VERSION "hnnbnnnynnnnnnnnnnnnnnnnnnnnnnnnnnnnnnnnnn/4/%%%/4/'%**4nnn///"

NS_ :

BS_:

BU_: BAP_Tester Fahrerdisplay_Kombi HUD ICAS1_X_Gateway ICAS3_Gateway ICC_IO_Node Kombi SmartLight_01 ZR_MIB_TOP_ab_Gen3

BO_ 1175 Parkhilfe_01: 8 ICAS1_X_Gateway
	SG_ PDC_Tonausgabe_Front : 4|4@1+ (1,0) [0|15] ""  Vector__XXX
	SG_ PDC_Tonausgabe_Heck : 8|4@1+ (1,0) [0|15] ""  Vector__XXX
	SG_ PH_Abschaltursache : 13|3@1+ (1,0) [0|7] ""  Vector__XXX
	SG_ PH_Anf_Audioabsenkung : 23|1@1+ (1,0) [0|1] ""  ICAS3_Gateway,ZR_MIB_TOP_ab_Gen3
	SG_ PH_Anf_Verdeck : 30|2@1+ (1,0) [0|3] ""  Vector__XXX
	SG_ PH_defekt : 56|1@1+ (1,0) [0|1] ""  Vector__XXX
	SG_ PH_Display_Kundenwunsch : 61|2@1+ (1,0) [0|3] ""  Vector__XXX
	SG_ PH_Frequenz_hinten : 32|4@1+ (1,0) [0|15] ""  Vector__XXX
	SG_ PH_Frequenz_vorn : 40|4@1+ (1,0) [0|15] ""  Vector__XXX
	SG_ PH_gestoert : 57|1@1+ (1,0) [0|1] ""  Vector__XXX
	SG_ PH_Lautstaerke_hinten : 36|4@1+ (1,0) [0|15] ""  Vector__XXX
	SG_ PH_Lautstaerke_vorn : 44|4@1+ (1,0) [0|15] ""  Vector__XXX
	SG_ PH_nachtr_Stopp_Anf : 12|1@1+ (1,0) [0|1] ""  Vector__XXX
	SG_ PH_Opt_Anz_H_Hindernis : 19|1@1+ (1,0) [0|1] ""  Vector__XXX
	SG_ PH_Opt_Anz_V_Hindernis : 18|1@1+ (1,0) [0|1] ""  Vector__XXX
	SG_ PH_Opt_Anzeige_H_ein : 17|1@1+ (1,0) [0|1] ""  Vector__XXX
	SG_ PH_Opt_Anzeige_V_ein : 16|1@1+ (1,0) [0|1] ""  Vector__XXX
	SG_ PH_StartStopp_Info : 49|2@1+ (1,0) [0|3] ""  Vector__XXX
	SG_ PH_Stoermeldung : 52|4@1+ (1,0) [0|15] ""  Kombi
	SG_ PH_Systemzustand : 58|3@1+ (1,0) [0|7] ""  Vector__XXX
	SG_ PH_Taster : 28|2@1+ (1,0) [0|3] ""  Vector__XXX
	SG_ PH_Tongeber_H_aktiv : 21|1@1+ (1,0) [0|1] ""  Vector__XXX
	SG_ PH_Tongeber_H_verfuegbar : 24|1@1+ (1,0) [0|1] ""  Vector__XXX
	SG_ PH_Tongeber_mute : 22|1@1+ (1,0) [0|1] ""  Vector__XXX
	SG_ PH_Tongeber_V_aktiv : 20|1@1+ (1,0) [0|1] ""  Vector__XXX
	SG_ PH_Visualisierung : 0|3@1+ (1,0) [0|7] ""  ICAS3_Gateway
	SG_ PLA_Anf_Aufschaltung_RVC : 25|1@1+ (1,0) [0|1] ""  Vector__XXX

BO_ 1355 Parkhilfe_04: 8 ICAS1_X_Gateway
	SG_ APS_PaCo_WarningTones : 48|1@1+ (1,0) [0|1] ""  Vector__XXX
	SG_ APSOPS_PaCo_ApproachingFront : 47|1@1+ (1,0) [0|1] ""  Vector__XXX
	SG_ APSOPS_PaCo_ApproachingRear : 46|1@1+ (1,0) [0|1] ""  Vector__XXX
	SG_ APSOPS_PaCo_Button : 38|2@1+ (1,0) [0|3] ""  Vector__XXX
	SG_ APSOPS_PaCo_FunctionState : 43|3@1+ (1,0) [0|7] ""  Vector__XXX
	SG_ APSOPS_PaCo_MainState : 40|3@1+ (1,0) [0|7] ""  Vector__XXX
	SG_ APSOPS_PaCo_ObstacleDetectFront : 35|3@1+ (1,0) [0|7] ""  Vector__XXX
	SG_ APSOPS_PaCo_ObstacleDetectRear : 32|3@1+ (1,0) [0|7] ""  Vector__XXX
	SG_ PH_Aufschaltursache : 16|5@1+ (1,0) [0|31] ""  Vector__XXX
	SG_ PH_Ton_Ausgabe : 21|3@1+ (1,0) [0|7] ""  ICAS3_Gateway,ZR_MIB_TOP_ab_Gen3
	SG_ PH_Ton_Lautstaerke : 52|3@1+ (1,0) [0|7] ""  ICAS3_Gateway,ZR_MIB_TOP_ab_Gen3
	SG_ PH_Ton_Pausenlaenge : 24|8@1+ (1,0) [0|255] ""  ICAS3_Gateway,ZR_MIB_TOP_ab_Gen3
	SG_ PH_Ton_Richtung : 49|3@1+ (1,0) [0|7] ""  ICAS3_Gateway,ZR_MIB_TOP_ab_Gen3
	SG_ PH_Verschmutzungsmeldung : 12|4@1+ (1,0) [0|15] ""  Kombi
	SG_ PH_WAH_Meldung : 55|3@1+ (1,0) [0|7] ""  Kombi
	SG_ RBF_Anf_Meldungen : 9|3@1+ (1,0) [0|7] ""  Kombi
	SG_ RBF_PaCo_Anf_Meldungen : 58|3@1+ (1,0) [0|7] ""  Vector__XXX
	SG_ RBFMA_PaCo_BrakeIntervention : 0|3@1+ (1,0) [0|7] ""  Vector__XXX
	SG_ RBFMA_PaCo_MainState : 3|3@1+ (1,0) [0|7] ""  Vector__XXX

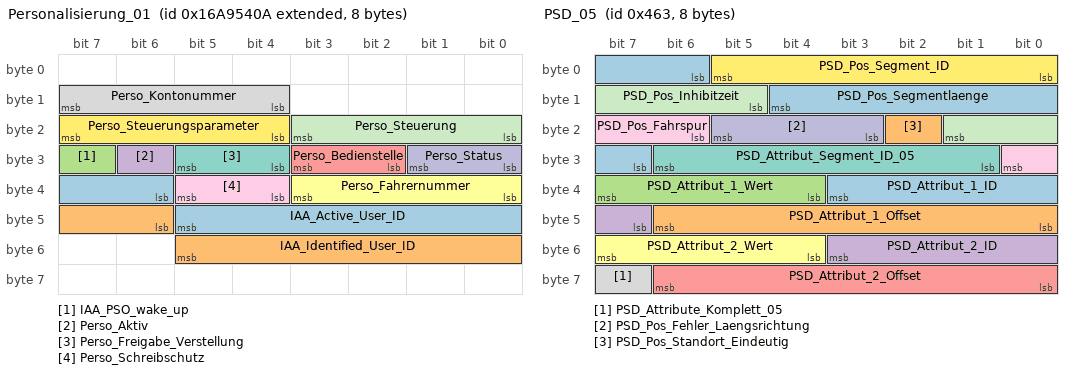
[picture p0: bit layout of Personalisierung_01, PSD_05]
BO_ 2527679498 Personalisierung_01: 8 ICAS1_X_Gateway
	SG_ IAA_Active_User_ID : 38|8@1+ (1,0) [0|255] "None"  ICAS3_Gateway,ZR_MIB_TOP_ab_Gen3
	SG_ IAA_Identified_User_ID : 46|8@1+ (1,0) [0|255] "None"  ICAS3_Gateway,ZR_MIB_TOP_ab_Gen3
	SG_ IAA_PSO_wake_up : 31|1@1+ (1,0) [0|1] ""  ICAS3_Gateway,ZR_MIB_TOP_ab_Gen3
	SG_ Perso_Aktiv : 30|1@1+ (1,0) [0|1] ""  ICAS3_Gateway
	SG_ Perso_Bedienstelle : 26|2@1+ (1,0) [0|3] ""  ICAS3_Gateway
	SG_ Perso_Fahrernummer : 32|4@1+ (1,0) [0|15] ""  ICAS3_Gateway,ZR_MIB_TOP_ab_Gen3
	SG_ Perso_Freigabe_Verstellung : 28|2@1+ (1,0) [0|3] ""  ICAS3_Gateway,ZR_MIB_TOP_ab_Gen3
	SG_ Perso_Kontonummer : 12|4@1+ (1,0) [0|15] ""  ICAS3_Gateway,Kombi,ZR_MIB_TOP_ab_Gen3
	SG_ Perso_Schreibschutz : 36|2@1+ (1,0) [0|3] ""  ICAS3_Gateway
	SG_ Perso_Status : 24|2@1+ (1,0) [0|3] ""  ICAS3_Gateway,Kombi,ZR_MIB_TOP_ab_Gen3
	SG_ Perso_Steuerung : 16|4@1+ (1,0) [0|15] ""  ICAS3_Gateway,Kombi,ZR_MIB_TOP_ab_Gen3
	SG_ Perso_Steuerungsparameter : 20|4@1+ (1,0) [0|15] ""  ICAS3_Gateway,Kombi,ZR_MIB_TOP_ab_Gen3

BO_ 319 PreCrash_02: 8 ICAS1_X_Gateway
	SG_ PreCrash_Anforderung_AFR : 26|3@1+ (1,0) [0|7] ""  Vector__XXX
	SG_ PreCrash_BFS_KSV_verfahren : 47|4@1+ (1,0) [0|15] ""  Vector__XXX
	SG_ PreCrash_BFS_Laengsverstellung : 55|1@1+ (1,0) [0|1] ""  Vector__XXX
	SG_ PreCrash_BFS_Pneumatik_ansteuern : 32|1@1+ (1,0) [0|1] ""  Vector__XXX
	SG_ PreCrash_BFS_Sitzlehne_verfahren : 37|3@1+ (1,0) [0|7] ""  Vector__XXX
	SG_ PreCrash_Blinken : 20|3@1+ (1,0) [0|7] ""  Vector__XXX
	SG_ PreCrash_Charisma_FahrPr : 12|4@1+ (1,0) [0|15] ""  Vector__XXX
	SG_ PreCrash_Charisma_Status : 16|2@1+ (1,0) [0|3] ""  Vector__XXX
	SG_ PreCrash_Fenster_schliessen : 19|1@1+ (1,0) [0|1] ""  Vector__XXX
	SG_ PreCrash_Fo_KSV_verfahren : 51|4@1+ (1,0) [0|15] ""  Vector__XXX
	SG_ PreCrash_Fo_Pneumatik_ansteuern : 33|1@1+ (1,0) [0|1] ""  Vector__XXX
	SG_ PreCrash_Fo_Sitzlehne_verfahren : 40|3@1+ (1,0) [0|7] ""  Vector__XXX
	SG_ PreCrash_FS_KSV_verfahren : 43|4@1+ (1,0) [0|15] ""  Vector__XXX
	SG_ PreCrash_FS_Laengsverstellung : 25|1@1+ (1,0) [0|1] ""  Vector__XXX
	SG_ PreCrash_FS_Pneumatik_ansteuern : 31|1@1+ (1,0) [0|1] ""  Vector__XXX
	SG_ PreCrash_FS_Sitzlehne_verfahren : 34|3@1+ (1,0) [0|7] ""  Vector__XXX
	SG_ PreCrash_Schiebedach_schliessen : 18|1@1+ (1,0) [0|1] ""  Vector__XXX
	SG_ PreCrash_Tueren_Verriegeln : 24|1@1+ (1,0) [0|1] ""  Vector__XXX
	SG_ SC_PreCrash_LED : 29|2@1+ (1,0) [0|3] ""  Vector__XXX
	SG_ SC_PreCrash_Texte : 60|4@1+ (1,0) [0|15] ""  Kombi
	SG_ SC_PreCrash_Warnung : 56|4@1+ (1,0) [0|15] ""  Kombi,ZR_MIB_TOP_ab_Gen3
	SG_ SC_PreSense_FCWP : 23|1@1+ (1,0) [0|1] ""  Vector__XXX

BO_ 1122 PSD_04: 8 ICAS3_Gateway
	SG_ PSD_Abzweigerichtung : 56|1@1+ (1,0) [0|1] ""  ICAS1_X_Gateway
	SG_ PSD_Abzweigewinkel : 57|7@1+ (1.417323,0) [0|180.000021] ""  ICAS1_X_Gateway
	SG_ PSD_ADAS_Qualitaet : 37|1@1+ (1,0) [0|1] ""  ICAS1_X_Gateway
	SG_ PSD_Anfangskruemmung : 47|8@1+ (1,0) [0|254] ""  ICAS1_X_Gateway
	SG_ PSD_Anfangskruemmung_Vorz : 55|1@1+ (1,0) [0|1] ""  ICAS1_X_Gateway
	SG_ PSD_Bebauung : 43|1@1+ (1,0) [0|1] ""  ICAS1_X_Gateway
	SG_ PSD_Endkruemmung : 22|8@1+ (1,0) [0|254] "None"  ICAS1_X_Gateway
	SG_ PSD_Endkruemmung_Vorz : 30|1@1+ (1,0) [0|1] ""  ICAS1_X_Gateway
	SG_ PSD_Fahrspuren_Anzahl : 40|3@1+ (1,0) [0|7] ""  ICAS1_X_Gateway
	SG_ PSD_Geradester_Pfad : 39|1@1+ (1,0) [0|1] ""  ICAS1_X_Gateway
	SG_ PSD_Idenditaets_ID : 31|6@1+ (1,0) [2|63] ""  ICAS1_X_Gateway
	SG_ PSD_Rampe : 45|2@1+ (1,0) [0|3] ""  ICAS1_X_Gateway
	SG_ PSD_Segment_ID : 0|6@1+ (1,0) [2|63] ""  ICAS1_X_Gateway
	SG_ PSD_Segment_Komplett : 44|1@1+ (1,0) [0|1] ""  ICAS1_X_Gateway
	SG_ PSD_Segmentlaenge : 12|7@1+ (2,0) [0|254] "Meter"  ICAS1_X_Gateway
	SG_ PSD_Strassenkategorie : 19|3@1+ (1,0) [0|7] ""  ICAS1_X_Gateway
	SG_ PSD_Vorgaenger_Segment_ID : 6|6@1+ (1,0) [2|63] ""  ICAS1_X_Gateway
	SG_ PSD_wahrscheinlichster_Pfad : 38|1@1+ (1,0) [0|1] ""  ICAS1_X_Gateway

BO_ 1123 PSD_05: 8 ICAS3_Gateway
	SG_ PSD_Attribut_1_ID : 31|5@1+ (1,0) [1|31] ""  ICAS1_X_Gateway
	SG_ PSD_Attribut_1_Offset : 40|7@1+ (2,0) [0|254] "Meter"  ICAS1_X_Gateway
	SG_ PSD_Attribut_1_Wert : 36|4@1+ (1,0) [0|15] ""  ICAS1_X_Gateway
	SG_ PSD_Attribut_2_ID : 47|5@1+ (1,0) [1|31] ""  ICAS1_X_Gateway
	SG_ PSD_Attribut_2_Offset : 56|7@1+ (2,0) [0|254] "Meter"  ICAS1_X_Gateway
	SG_ PSD_Attribut_2_Wert : 52|4@1+ (1,0) [0|15] ""  ICAS1_X_Gateway
	SG_ PSD_Attribut_Segment_ID_05 : 25|6@1+ (1,0) [2|63] ""  ICAS1_X_Gateway
	SG_ PSD_Attribute_Komplett_05 : 63|1@1+ (1,0) [0|1] ""  ICAS1_X_Gateway
	SG_ PSD_Pos_Fahrspur : 22|3@1+ (1,0) [0|7] ""  ICAS1_X_Gateway
	SG_ PSD_Pos_Fehler_Laengsrichtung : 19|3@1+ (1,0) [0|7] ""  ICAS1_X_Gateway
	SG_ PSD_Pos_Inhibitzeit : 13|5@1+ (10,0) [0|310] "MilliSecon"  ICAS1_X_Gateway
	SG_ PSD_Pos_Segment_ID : 0|6@1+ (1,0) [2|63] ""  ICAS1_X_Gateway
	SG_ PSD_Pos_Segmentlaenge : 6|7@1+ (2,0) [0|254] "Meter"  ICAS1_X_Gateway
	SG_ PSD_Pos_Standort_Eindeutig : 18|1@1+ (1,0) [0|1] ""  ICAS1_X_Gateway

BO_ 1124 PSD_06: 8 ICAS3_Gateway
	SG_ PSD_06_Mux M : 0|3@1+ (1,0) [0|7] ""  ICAS1_X_Gateway
	SG_ PSD_Attribut_3_ID m1 : 9|5@1+ (1,0) [1|31] ""  ICAS1_X_Gateway
	SG_ PSD_Attribut_3_Offset m1 : 14|7@1+ (2,0) [0|254] "Meter"  ICAS1_X_Gateway
	SG_ PSD_Attribut_3_Wert m1 : 21|4@1+ (1,0) [0|15] ""  ICAS1_X_Gateway
	SG_ PSD_Attribut_4_ID m1 : 25|5@1+ (1,0) [1|31] ""  ICAS1_X_Gateway
	SG_ PSD_Attribut_4_Offset m1 : 34|7@1+ (2,0) [0|254] "Meter"  ICAS1_X_Gateway
	SG_ PSD_Attribut_4_Wert m1 : 30|4@1+ (1,0) [0|15] ""  ICAS1_X_Gateway
	SG_ PSD_Attribut_5_ID m1 : 41|5@1+ (1,0) [1|31] ""  ICAS1_X_Gateway
	SG_ PSD_Attribut_5_Offset m1 : 46|7@1+ (2,0) [0|254] "Meter"  ICAS1_X_Gateway
	SG_ PSD_Attribut_5_Wert m1 : 53|4@1+ (1,0) [0|15] ""  ICAS1_X_Gateway
	SG_ PSD_Attribut_Segment_ID m1 : 3|6@1+ (1,0) [2|63] ""  ICAS1_X_Gateway
	SG_ PSD_Attribute_Komplett_06 m1 : 57|1@1+ (1,0) [0|1] ""  ICAS1_X_Gateway
	SG_ PSD_Baum_Ausrichtung m3 : 54|10@1+ (0.3515625,0) [0|359.6484375] "DegreOfArc"  ICAS1_X_Gateway
	SG_ PSD_Baum_Breite m3 : 30|24@1+ (0.00001,0) [0|90] "DegreOfArc"  ICAS1_X_Gateway
	SG_ PSD_Baum_Breite_VZ m3 : 29|1@1+ (1,0) [0|1] ""  ICAS1_X_Gateway
	SG_ PSD_Baum_Laenge m3 : 4|25@1+ (0.00001,0) [0|180] "DegreOfArc"  ICAS1_X_Gateway
	SG_ PSD_Baum_Laenge_VZ m3 : 3|1@1+ (1,0) [0|1] ""  ICAS1_X_Gateway
	SG_ PSD_Ges_Attribute_Komplett m2 : 63|1@1+ (1,0) [0|1] ""  ICAS1_X_Gateway
	SG_ PSD_Ges_Geschwindigkeit m2 : 16|5@1+ (1,0) [0|31] ""  ICAS1_X_Gateway
	SG_ PSD_Ges_Geschwindigkeit_Gespann m2 : 29|2@1+ (1,0) [0|3] ""  ICAS1_X_Gateway
	SG_ PSD_Ges_Geschwindigkeit_Std_Anf m2 : 39|5@1+ (1,0) [0|24] "Hours"  ICAS1_X_Gateway
	SG_ PSD_Ges_Geschwindigkeit_Std_Ende m2 : 44|5@1+ (1,0) [0|24] "Hours"  ICAS1_X_Gateway
	SG_ PSD_Ges_Geschwindigkeit_Tag_Anf m2 : 33|3@1+ (1,0) [0|7] ""  ICAS1_X_Gateway
	SG_ PSD_Ges_Geschwindigkeit_Tag_Ende m2 : 36|3@1+ (1,0) [0|7] ""  ICAS1_X_Gateway
	SG_ PSD_Ges_Geschwindigkeit_Witter m2 : 31|2@1+ (1,0) [0|3] ""  ICAS1_X_Gateway
	SG_ PSD_Ges_Gesetzlich_Kategorie m2 : 56|3@1+ (1,0) [0|7] ""  ICAS1_X_Gateway
	SG_ PSD_Ges_Gesetzlich_Zusatz m2 : 59|2@1+ (1,0) [0|3] ""  ICAS1_X_Gateway
	SG_ PSD_Ges_Offset m2 : 9|7@1+ (2,0) [0|254] "Meter"  ICAS1_X_Gateway
	SG_ PSD_Ges_Segment_ID m2 : 3|6@1+ (1,0) [2|63] ""  ICAS1_X_Gateway
	SG_ PSD_Ges_Spur_Geschw_Begrenzung m2 : 23|6@1+ (1,0) [0|63] ""  ICAS1_X_Gateway
	SG_ PSD_Ges_Typ m2 : 21|2@1+ (1,0) [0|3] ""  ICAS1_X_Gateway
	SG_ PSD_Ges_Ueberholverbot m2 : 49|2@1+ (1,0) [0|3] ""  ICAS1_X_Gateway
	SG_ PSD_Ges_Verkehrszeichen_Quelle m2 : 61|2@1+ (1,0) [0|3] ""  ICAS1_X_Gateway
	SG_ PSD_Ges_Wechselverkehrszeichen m2 : 51|3@1+ (1,0) [0|7] ""  ICAS1_X_Gateway
	SG_ PSD_Steigung_1_A_Offset m4 : 17|7@1+ (2,0) [0|254] "Meter"  ICAS1_X_Gateway
	SG_ PSD_Steigung_1_A_Steigung m4 : 9|7@1+ (0.12,0) [0|15] "PerCent"  ICAS1_X_Gateway
	SG_ PSD_Steigung_1_A_Vorz m4 : 16|1@1+ (1,0) [0|1] ""  ICAS1_X_Gateway
	SG_ PSD_Steigung_1_Attribute_kompl m4 : 39|1@1+ (1,0) [0|1] ""  ICAS1_X_Gateway
	SG_ PSD_Steigung_1_B_Offset m4 : 32|7@1+ (2,0) [0|254] "Meter"  ICAS1_X_Gateway
	SG_ PSD_Steigung_1_B_Steigung m4 : 24|7@1+ (0.12,0) [0|15] "PerCent"  ICAS1_X_Gateway
	SG_ PSD_Steigung_1_B_Vorz m4 : 31|1@1+ (1,0) [0|1] ""  ICAS1_X_Gateway
	SG_ PSD_Steigung_1_Segment_ID m4 : 3|6@1+ (1,0) [2|63] ""  ICAS1_X_Gateway
	SG_ PSD_Steigung_2_Attribute_kompl m4 : 61|1@1+ (1,0) [0|1] ""  ICAS1_X_Gateway
	SG_ PSD_Steigung_2_Offset m4 : 54|7@1+ (2,0) [0|254] "Meter"  ICAS1_X_Gateway
	SG_ PSD_Steigung_2_Segment_ID m4 : 40|6@1+ (1,0) [2|63] ""  ICAS1_X_Gateway
	SG_ PSD_Steigung_2_Steigung m4 : 46|7@1+ (0.12,0) [0|15] "PerCent"  ICAS1_X_Gateway
	SG_ PSD_Steigung_2_Vorz m4 : 53|1@1+ (1,0) [0|1] ""  ICAS1_X_Gateway
	SG_ PSD_Sys_Alter_Karte m0 : 23|3@1+ (1,0) [0|7] ""  ICAS1_X_Gateway
	SG_ PSD_Sys_Geometrieguete m0 : 19|2@1+ (1,0) [0|3] ""  ICAS1_X_Gateway
	SG_ PSD_Sys_Geometrieguete_erweitert m0 : 40|8@1+ (1,0) [0|255] ""  ICAS1_X_Gateway
	SG_ PSD_Sys_Geschwindigkeit_Einheit m0 : 17|1@1+ (1,0) [0|1] ""  ICAS1_X_Gateway
	SG_ PSD_Sys_Laendercode m0 : 9|8@1+ (1,0) [0|255] ""  ICAS1_X_Gateway,Kombi
	SG_ PSD_Sys_Mapmatchingguete m0 : 21|2@1+ (1,0) [0|3] ""  ICAS1_X_Gateway
	SG_ PSD_Sys_Quali_Geometrien m0 : 33|3@1+ (1,0) [0|7] "None"  ICAS1_X_Gateway
	SG_ PSD_Sys_Quali_Ortsinfo m0 : 36|2@1+ (1,0) [0|3] "None"  ICAS1_X_Gateway
	SG_ PSD_Sys_Quali_sonstige_Attribute m0 : 48|3@1+ (1,0) [0|7] "None"  ICAS1_X_Gateway
	SG_ PSD_Sys_Quali_Steigungen m0 : 51|3@1+ (1,0) [0|7] ""  ICAS1_X_Gateway
	SG_ PSD_Sys_Quali_Strassenkennz m0 : 54|3@1+ (1,0) [0|7] "None"  ICAS1_X_Gateway
	SG_ PSD_Sys_Quali_Tempolimits m0 : 57|3@1+ (1,0) [0|7] "None"  ICAS1_X_Gateway
	SG_ PSD_Sys_Quali_verfuegbar m0 : 38|1@1+ (1,0) [0|1] ""  ICAS1_X_Gateway
	SG_ PSD_Sys_Quali_Vorfahrtsregelung m0 : 60|3@1+ (1,0) [0|7] "None"  ICAS1_X_Gateway
	SG_ PSD_Sys_Segment_ID m0 : 3|6@1+ (1,0) [2|63] ""  ICAS1_X_Gateway
	SG_ PSD_Sys_US_State m0 : 27|6@1+ (1,0) [0|63] ""  ICAS1_X_Gateway
	SG_ PSD_Sys_Verkehrsrichtung m0 : 18|1@1+ (1,0) [0|1] ""  ICAS1_X_Gateway
	SG_ PSD_Sys_Zielfuehrung m0 : 26|1@1+ (1,0) [0|1] ""  ICAS1_X_Gateway
	SG_ PSD_Sys_Zielfuehrung_geaendert m0 : 39|1@1+ (1,0) [0|1] ""  ICAS1_X_Gateway
	SG_ PSD_Wechselverkehrszeichen_Typ m2 : 54|2@1+ (1,0) [0|3] ""  ICAS1_X_Gateway

BO_ 1125 PSD_LR_01: 8 ICAS3_Gateway
	SG_ PSD_LR_01_MUX M : 2|2@1+ (1,0) [0|3] ""  ICAS1_X_Gateway
	SG_ PSD_LR_Attribut_1_Offset m2 : 4|12@1+ (0.0244140625,0) [0|99.9755859375] "PerCent"  ICAS1_X_Gateway
	SG_ PSD_LR_Attribut_1_Wert m2 : 16|8@1+ (1,0) [0|255] ""  ICAS1_X_Gateway
	SG_ PSD_LR_Attribut_2_Offset m2 : 24|12@1+ (0.0244140625,0) [0|99.9755859375] "PerCent"  ICAS1_X_Gateway
	SG_ PSD_LR_Attribut_2_Wert m2 : 36|8@1+ (1,0) [0|255] ""  ICAS1_X_Gateway
	SG_ PSD_LR_Attribut_3_Offset m2 : 44|12@1+ (0.0244140625,0) [0|99.9755859375] "PerCent"  ICAS1_X_Gateway
	SG_ PSD_LR_Attribut_3_Wert m2 : 56|8@1+ (1,0) [0|255] ""  ICAS1_X_Gateway
	SG_ PSD_LR_Fahrzeug_Pos m0 : 18|14@1+ (0.006103888,0) [0|99.999997104] "PerCent"  ICAS1_X_Gateway
	SG_ PSD_LR_Globale_Steigung m0 : 33|19@1+ (0.000028610284,0) [0|14.999999999998] "PerCent"  ICAS1_X_Gateway
	SG_ PSD_LR_Globale_Steigung_Vorz m0 : 32|1@1+ (1,0) [0|1] ""  ICAS1_X_Gateway
	SG_ PSD_LR_Koeff_1_Amp m1 : 10|9@1+ (0.01956947162,0) [0|9.99999999782] "PerCent"  ICAS1_X_Gateway
	SG_ PSD_LR_Koeff_1_Phase m1 : 19|9@1+ (0.0122958616,0) [0|6.2831852776] "DegreOfArc"  ICAS1_X_Gateway
	SG_ PSD_LR_Koeff_2_Amp m1 : 28|9@1+ (0.01956947162,0) [0|9.99999999782] "PerCent"  ICAS1_X_Gateway
	SG_ PSD_LR_Koeff_2_Phase m1 : 37|9@1+ (0.0122958616,0) [0|6.2831852776] "DegreOfArc"  ICAS1_X_Gateway
	SG_ PSD_LR_Koeff_3_Amp m1 : 46|9@1+ (0.01956947162,0) [0|9.99999999782] "PerCent"  ICAS1_X_Gateway
	SG_ PSD_LR_Koeff_3_Phase m1 : 55|9@1+ (0.0122958616,0) [0|6.2831852776] "DegreOfArc"  ICAS1_X_Gateway
	SG_ PSD_LR_Koeffizientensatz_Nr m1 : 4|6@1+ (1,0) [0|63] ""  ICAS1_X_Gateway
	SG_ PSD_LR_Max_Koeff_Amp m0 : 52|11@1+ (2,0) [0|4094] "Meter"  ICAS1_X_Gateway
	SG_ PSD_LR_Profil_Laenge m0 : 4|14@1+ (0.25,0) [0|4095.75] "KiloMeter"  ICAS1_X_Gateway
	SG_ PSD_LR_Profil_Nummer : 0|2@1+ (1,0) [0|3] ""  ICAS1_X_Gateway
	SG_ PSD_LR_Reset m0 : 63|1@1+ (1,0) [0|1] ""  ICAS1_X_Gateway
	SG_ PSD_LR_Steigung_1_Offset m3 : 4|12@1+ (0.0244140625,0) [0|99.9755859375] "PerCent"  ICAS1_X_Gateway
	SG_ PSD_LR_Steigung_1_Vorz m3 : 16|1@1+ (1,0) [0|1] ""  ICAS1_X_Gateway
	SG_ PSD_LR_Steigung_1_Wert m3 : 17|7@1+ (0.12,0) [0|15.24] "PerCent"  ICAS1_X_Gateway
	SG_ PSD_LR_Steigung_2_Offset m3 : 24|12@1+ (0.0244140625,0) [0|99.9755859375] "PerCent"  ICAS1_X_Gateway
	SG_ PSD_LR_Steigung_2_Vorz m3 : 36|1@1+ (1,0) [0|1] ""  ICAS1_X_Gateway
	SG_ PSD_LR_Steigung_2_Wert m3 : 37|7@1+ (0.12,0) [0|15.24] "PerCent"  ICAS1_X_Gateway
	SG_ PSD_LR_Steigung_3_Offset m3 : 44|12@1+ (0.0244140625,0) [0|99.9755859375] "PerCent"  ICAS1_X_Gateway
	SG_ PSD_LR_Steigung_3_Vorz m3 : 56|1@1+ (1,0) [0|1] ""  ICAS1_X_Gateway
	SG_ PSD_LR_Steigung_3_Wert m3 : 57|7@1+ (0.12,0) [0|15.24] "PerCent"  ICAS1_X_Gateway

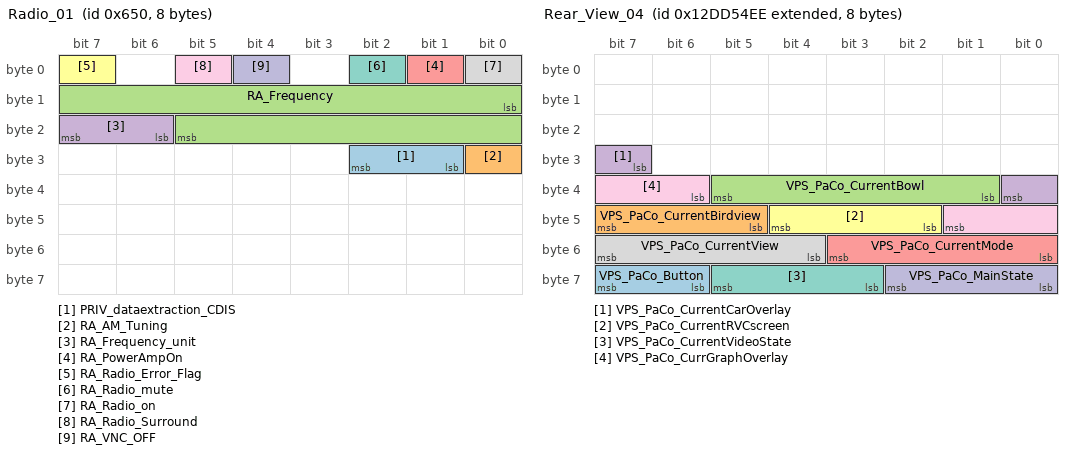
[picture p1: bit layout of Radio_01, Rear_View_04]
BO_ 1616 Radio_01: 8 ICAS3_Gateway
	SG_ PRIV_dataextraction_CDIS : 25|2@1+ (1,0) [0|3] ""  ICAS1_X_Gateway
	SG_ RA_AM_Tuning : 24|1@1+ (1,0) [0|1] ""  ICAS1_X_Gateway
	SG_ RA_Frequency : 8|14@1+ (1,0) [0|16383] "None"  ICAS1_X_Gateway
	SG_ RA_Frequency_unit : 22|2@1+ (1,0) [0|3] ""  ICAS1_X_Gateway
	SG_ RA_PowerAmpOn : 1|1@1+ (1,0) [0|1] ""  ICAS1_X_Gateway
	SG_ RA_Radio_Error_Flag : 7|1@1+ (1,0) [0|1] ""  ICAS1_X_Gateway
	SG_ RA_Radio_mute : 2|1@1+ (1,0) [0|1] ""  ICAS1_X_Gateway
	SG_ RA_Radio_on : 0|1@1+ (1,0) [0|1] ""  ICAS1_X_Gateway
	SG_ RA_Radio_Surround : 5|1@1+ (1,0) [0|1] ""  ICAS1_X_Gateway
	SG_ RA_VNC_OFF : 4|1@1+ (1,0) [0|1] ""  ICAS1_X_Gateway

BO_ 2527679748 RDK_11: 32 ICAS1_X_Gateway
	SG_ TPMS_CalTyp : 12|2@1+ (1,0) [0|3] ""  Vector__XXX
	SG_ TPMS_disable : 189|1@1+ (1,0) [0|1] ""  Vector__XXX
	SG_ TPMS_enable : 188|1@1+ (1,0) [0|1] ""  Vector__XXX
	SG_ TPMS_LearningState : 214|4@1+ (1,0) [0|15] ""  Vector__XXX
	SG_ TPMS_PDeFrLe : 108|7@1+ (0.1,-6.3) [-6.3|6.3] "Bar"  Vector__XXX
	SG_ TPMS_PDeFrRi : 115|7@1+ (0.1,-6.3) [-6.3|6.3] "Bar"  Vector__XXX
	SG_ TPMS_PDeReLe : 122|7@1+ (0.1,-6.3) [-6.3|6.3] "Bar"  Vector__XXX
	SG_ TPMS_PDeReRi : 129|7@1+ (0.1,-6.3) [-6.3|6.3] "Bar"  Vector__XXX
	SG_ TPMS_RaceTrckMdSts : 43|1@1+ (1,0) [0|1] ""  Vector__XXX
	SG_ TPMS_SensBattStsFrLe : 136|7@1+ (1,0) [0|100] "PerCent"  Vector__XXX
	SG_ TPMS_SensBattStsFrRi : 143|7@1+ (1,0) [0|100] "PerCent"  Vector__XXX
	SG_ TPMS_SensBattStsReLe : 150|7@1+ (1,0) [0|100] "PerCent"  Vector__XXX
	SG_ TPMS_SensBattStsReRi : 157|7@1+ (1,0) [0|100] "PerCent"  Vector__XXX
	SG_ TPMS_SensPFrLe : 84|6@1+ (0.1,0) [0|6.2] "Bar"  Vector__XXX
	SG_ TPMS_SensPFrRi : 90|6@1+ (0.1,0) [0|6.2] "Bar"  Vector__XXX
	SG_ TPMS_SensPReLe : 96|6@1+ (0.1,0) [0|6.2] "Bar"  Vector__XXX
	SG_ TPMS_SensPReRi : 102|6@1+ (0.1,0) [0|6.2] "Bar"  Vector__XXX
	SG_ TPMS_SensSigAgeFrLe : 164|4@1+ (1,0) [0|10] "Minut"  Vector__XXX
	SG_ TPMS_SensSigAgeFrRi : 168|4@1+ (1,0) [0|10] "Minut"  Vector__XXX
	SG_ TPMS_SensSigAgeReLe : 172|4@1+ (1,0) [0|10] "Minut"  Vector__XXX
	SG_ TPMS_SensSigAgeReRi : 176|4@1+ (1,0) [0|10] "Minut"  Vector__XXX
	SG_ TPMS_SensStsFrLe : 180|1@1+ (1,0) [0|1] ""  Vector__XXX
	SG_ TPMS_SensStsFrRi : 181|1@1+ (1,0) [0|1] ""  Vector__XXX
	SG_ TPMS_SensStsReLe : 182|1@1+ (1,0) [0|1] ""  Vector__XXX
	SG_ TPMS_SensStsReRi : 183|1@1+ (1,0) [0|1] ""  Vector__XXX
	SG_ TPMS_SensTFrLe : 52|8@1+ (1,-60) [-60|193] "DegreCelsi"  Vector__XXX
	SG_ TPMS_SensTFrRi : 60|8@1+ (1,-60) [-60|193] "DegreCelsi"  Vector__XXX
	SG_ TPMS_SensTReLe : 68|8@1+ (1,-60) [-60|193] "DegreCelsi"  Vector__XXX
	SG_ TPMS_SensTReRi : 76|8@1+ (1,-60) [-60|193] "DegreCelsi"  Vector__XXX
	SG_ TPMS_SensTypFrLe : 184|1@1+ (1,0) [0|1] ""  Vector__XXX
	SG_ TPMS_SensTypFrRi : 185|1@1+ (1,0) [0|1] ""  Vector__XXX
	SG_ TPMS_SensTypReLe : 186|1@1+ (1,0) [0|1] ""  Vector__XXX
	SG_ TPMS_SensTypReRi : 187|1@1+ (1,0) [0|1] ""  Vector__XXX
	SG_ TPMS_TarPTmpDepFrLe : 190|6@1+ (0.1,0) [0|6.2] "Bar"  Vector__XXX
	SG_ TPMS_TarPTmpDepFrRi : 196|6@1+ (0.1,0) [0|6.2] "Bar"  Vector__XXX
	SG_ TPMS_TarPTmpDepReLe : 202|6@1+ (0.1,0) [0|6.2] "Bar"  Vector__XXX
	SG_ TPMS_TarPTmpDepReRi : 208|6@1+ (0.1,0) [0|6.2] "Bar"  Vector__XXX
	SG_ TPMS_Warn1 : 18|1@1+ (1,0) [0|1] ""  Vector__XXX
	SG_ TPMS_Warn1TireFrLe : 19|1@1+ (1,0) [0|1] ""  Vector__XXX
	SG_ TPMS_Warn1TireFrRi : 20|1@1+ (1,0) [0|1] ""  Vector__XXX
	SG_ TPMS_Warn1TireReLe : 21|1@1+ (1,0) [0|1] ""  Vector__XXX
	SG_ TPMS_Warn1TireReRi : 22|1@1+ (1,0) [0|1] ""  Vector__XXX
	SG_ TPMS_Warn2 : 23|1@1+ (1,0) [0|1] ""  Vector__XXX
	SG_ TPMS_Warn2TireFrLe : 24|1@1+ (1,0) [0|1] ""  Vector__XXX
	SG_ TPMS_Warn2TireFrRi : 25|1@1+ (1,0) [0|1] ""  Vector__XXX
	SG_ TPMS_Warn2TireReLe : 26|1@1+ (1,0) [0|1] ""  Vector__XXX
	SG_ TPMS_Warn2TireReRi : 27|1@1+ (1,0) [0|1] ""  Vector__XXX
	SG_ TPMS_Warn3 : 28|1@1+ (1,0) [0|1] ""  Vector__XXX
	SG_ TPMS_Warn3TireFrLe : 29|1@1+ (1,0) [0|1] ""  Vector__XXX
	SG_ TPMS_Warn3TireFrRi : 30|1@1+ (1,0) [0|1] ""  Vector__XXX
	SG_ TPMS_Warn3TireReLe : 31|1@1+ (1,0) [0|1] ""  Vector__XXX
	SG_ TPMS_Warn3TireReRi : 32|1@1+ (1,0) [0|1] ""  Vector__XXX
	SG_ TPMS_Warn4 : 33|1@1+ (1,0) [0|1] ""  Vector__XXX
	SG_ TPMS_Warn4TireFrLe : 34|1@1+ (1,0) [0|1] ""  Vector__XXX
	SG_ TPMS_Warn4TireFrRi : 35|1@1+ (1,0) [0|1] ""  Vector__XXX
	SG_ TPMS_Warn4TireReLe : 36|1@1+ (1,0) [0|1] ""  Vector__XXX
	SG_ TPMS_Warn4TireReRi : 37|1@1+ (1,0) [0|1] ""  Vector__XXX
	SG_ TPMS_WarnAcoCalOk : 44|1@1+ (1,0) [0|1] ""  Vector__XXX
	SG_ TPMS_WarnCalOk : 38|1@1+ (1,0) [0|1] ""  Vector__XXX
	SG_ TPMS_WarnCmftP : 45|1@1+ (1,0) [0|1] ""  Vector__XXX
	SG_ TPMS_WarnFltIdc : 46|1@1+ (1,0) [0|1] ""  Vector__XXX
	SG_ TPMS_WarnFr : 47|1@1+ (1,0) [0|1] ""  Vector__XXX
	SG_ TPMS_WarnLmpStMil : 39|1@1+ (1,0) [0|1] ""  Kombi
	SG_ TPMS_WarnLmpStP : 48|1@1+ (1,0) [0|1] ""  Kombi
	SG_ TPMS_WarnMaxV : 49|1@1+ (1,0) [0|1] ""  Vector__XXX
	SG_ TPMS_WarnRaceTrckMdMinP : 50|1@1+ (1,0) [0|1] ""  Vector__XXX
	SG_ TPMS_WarnRe : 51|1@1+ (1,0) [0|1] ""  Vector__XXX
	SG_ TPMS_WarnSysLrn : 40|1@1+ (1,0) [0|1] ""  Vector__XXX
	SG_ TPMS_WarnTmpFlt : 41|1@1+ (1,0) [0|1] ""  Vector__XXX
	SG_ TPMS_WarnWhlChgDet : 42|1@1+ (1,0) [0|1] ""  Vector__XXX
	SG_ TPMS_WhlChgDetFrLe : 14|1@1+ (1,0) [0|1] ""  Vector__XXX
	SG_ TPMS_WhlChgDetFrRi : 15|1@1+ (1,0) [0|1] ""  Vector__XXX
	SG_ TPMS_WhlChgDetReLe : 16|1@1+ (1,0) [0|1] ""  Vector__XXX
	SG_ TPMS_WhlChgDetReRi : 17|1@1+ (1,0) [0|1] ""  Vector__XXX

BO_ 2463978734 Rear_View_04: 8 ICAS1_X_Gateway
	SG_ VPS_PaCo_Button : 62|2@1+ (1,0) [0|3] ""  Vector__XXX
	SG_ VPS_PaCo_CurrentBirdview : 45|3@1+ (1,0) [0|7] ""  Vector__XXX
	SG_ VPS_PaCo_CurrentBowl : 33|5@1+ (1,0) [0|31] ""  Vector__XXX
	SG_ VPS_PaCo_CurrentCarOverlay : 31|2@1+ (1,0) [0|3] ""  Vector__XXX
	SG_ VPS_PaCo_CurrentMode : 48|4@1+ (1,0) [0|15] ""  Vector__XXX
	SG_ VPS_PaCo_CurrentRVCscreen : 42|3@1+ (1,0) [0|7] ""  Vector__XXX
	SG_ VPS_PaCo_CurrentVideoState : 59|3@1+ (1,0) [0|7] ""  ICAS3_Gateway
	SG_ VPS_PaCo_CurrentView : 52|4@1+ (1,0) [0|15] ""  Vector__XXX
	SG_ VPS_PaCo_CurrGraphOverlay : 38|4@1+ (1,0) [0|15] ""  Vector__XXX
	SG_ VPS_PaCo_MainState : 56|3@1+ (1,0) [0|7] ""  Vector__XXX

BO_ 2527679742 Rear_View_06: 8 ICAS1_X_Gateway
	SG_ Kam_Anf_Meldung : 12|3@1+ (1,0) [0|7] ""  Kombi
	SG_ Kam_PaCo_MainState : 15|3@1+ (1,0) [0|7] ""  Vector__XXX

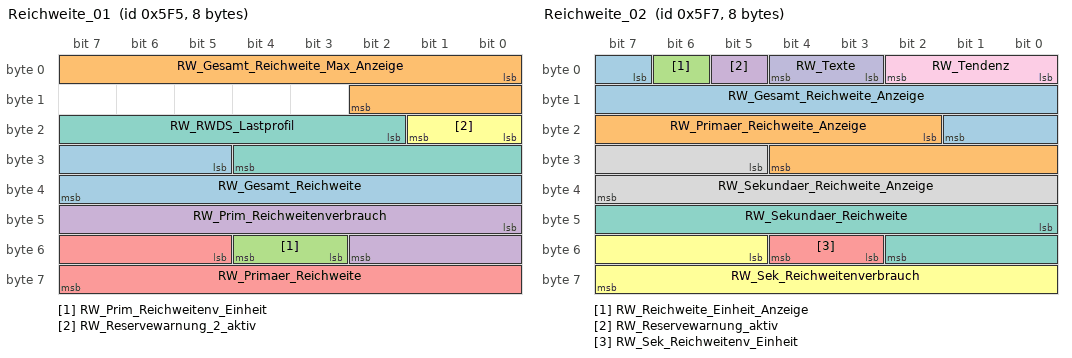
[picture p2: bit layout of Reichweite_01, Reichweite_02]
BO_ 1525 Reichweite_01: 8 ICAS1_X_Gateway
	SG_ RW_Gesamt_Reichweite : 29|11@1+ (1,0) [0|2044] "KiloMeter"  Kombi
	SG_ RW_Gesamt_Reichweite_Max_Anzeige : 0|11@1+ (1,0) [0|2044] "None"  Kombi
	SG_ RW_Prim_Reichweitenv_Einheit : 51|2@1+ (1,0) [0|3] ""  Kombi
	SG_ RW_Prim_Reichweitenverbrauch : 40|11@1+ (0.1,0) [0|204.4] "None"  Kombi
	SG_ RW_Primaer_Reichweite : 53|11@1+ (1,0) [0|2044] "KiloMeter"  Kombi
	SG_ RW_Reservewarnung_2_aktiv : 16|2@1+ (1,0) [0|3] ""  Kombi
	SG_ RW_RWDS_Lastprofil : 18|11@1+ (1,0) [0|2045] "Amper"  Kombi

BO_ 1527 Reichweite_02: 8 ICAS1_X_Gateway
	SG_ RW_Gesamt_Reichweite_Anzeige : 7|11@1+ (1,0) [0|2044] "None"  Kombi
	SG_ RW_Primaer_Reichweite_Anzeige : 18|11@1+ (1,0) [0|2044] "None"  Kombi,ZR_MIB_TOP_ab_Gen3
	SG_ RW_Reichweite_Einheit_Anzeige : 6|1@1+ (1,0) [0|1] ""  Kombi
	SG_ RW_Reservewarnung_aktiv : 5|1@1+ (1,0) [0|1] ""  Kombi
	SG_ RW_Sek_Reichweitenv_Einheit : 51|2@1+ (1,0) [0|3] ""  Kombi
	SG_ RW_Sek_Reichweitenverbrauch : 53|11@1+ (0.1,0) [0|204.4] "None"  Kombi
	SG_ RW_Sekundaer_Reichweite : 40|11@1+ (1,0) [0|2044] "KiloMeter"  Kombi
	SG_ RW_Sekundaer_Reichweite_Anzeige : 29|11@1+ (1,0) [0|2044] "None"  Kombi
	SG_ RW_Tendenz : 0|3@1+ (1,0) [0|7] ""  Vector__XXX
	SG_ RW_Texte : 3|2@1+ (1,0) [0|3] ""  Vector__XXX

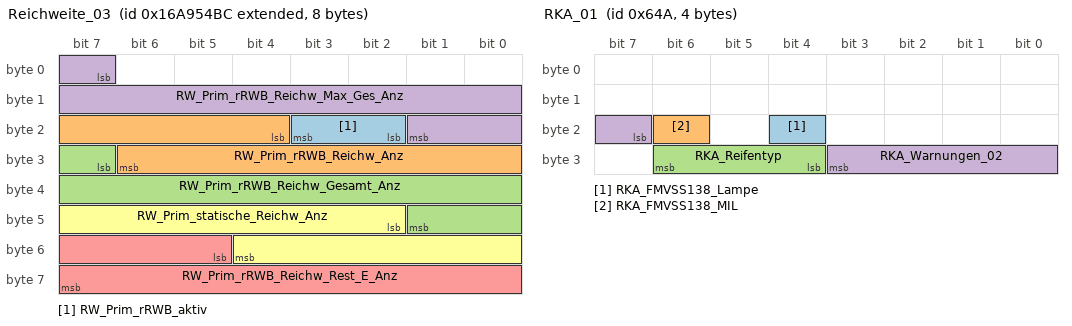
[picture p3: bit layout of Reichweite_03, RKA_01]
BO_ 2527679676 Reichweite_03: 8 ICAS1_X_Gateway
	SG_ RW_Prim_rRWB_aktiv : 18|2@1+ (1,0) [0|3] ""  Kombi,ZR_MIB_TOP_ab_Gen3
	SG_ RW_Prim_rRWB_Reichw_Anz : 20|11@1+ (1,0) [0|2044] ""  Kombi
	SG_ RW_Prim_rRWB_Reichw_Gesamt_Anz : 31|11@1+ (1,0) [0|2044] "None"  Kombi,ZR_MIB_TOP_ab_Gen3
	SG_ RW_Prim_rRWB_Reichw_Max_Ges_Anz : 7|11@1+ (1,0) [0|2044] ""  Kombi
	SG_ RW_Prim_rRWB_Reichw_Rest_E_Anz : 53|11@1+ (1,0) [0|2044] ""  Kombi
	SG_ RW_Prim_statische_Reichw_Anz : 42|11@1+ (1,0) [0|2044] ""  Kombi

BO_ 1610 RKA_01: 4 ICAS1_X_Gateway
	SG_ RKA_FMVSS138_Lampe : 20|1@1+ (1,0) [0|1] ""  Fahrerdisplay_Kombi,Kombi
	SG_ RKA_FMVSS138_MIL : 22|1@1+ (1,0) [0|1] ""  Fahrerdisplay_Kombi,Kombi
	SG_ RKA_Reifentyp : 28|3@1+ (1,0) [0|7] ""  Vector__XXX
	SG_ RKA_Warnungen_02 : 23|5@1+ (1,0) [0|31] ""  Kombi

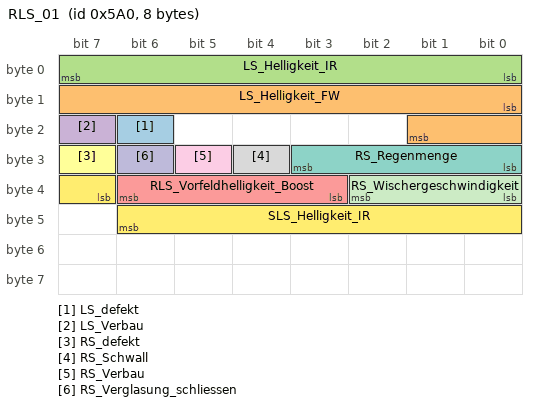
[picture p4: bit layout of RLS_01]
BO_ 1440 RLS_01: 8 ICAS1_X_Gateway
	SG_ LS_defekt : 22|1@1+ (1,0) [0|1] ""  SmartLight_01
	SG_ LS_Helligkeit_FW : 8|10@1+ (6,0) [0|6126] "Lux"  SmartLight_01
	SG_ LS_Helligkeit_IR : 0|8@1+ (400,0) [0|101200] "Lux"  SmartLight_01
	SG_ LS_Verbau : 23|1@1+ (1,0) [0|1] ""  Vector__XXX
	SG_ RLS_Vorfeldhelligkeit_Boost : 35|4@1+ (1,0) [0|15] ""  SmartLight_01
	SG_ RS_defekt : 31|1@1+ (1,0) [0|1] ""  Kombi
	SG_ RS_Regenmenge : 24|4@1+ (1,0) [0|15] ""  Vector__XXX
	SG_ RS_Schwall : 28|1@1+ (1,0) [0|1] ""  Vector__XXX
	SG_ RS_Verbau : 29|1@1+ (1,0) [0|1] ""  Vector__XXX
	SG_ RS_Verglasung_schliessen : 30|1@1+ (1,0) [0|1] ""  Vector__XXX
	SG_ RS_Wischergeschwindigkeit : 32|3@1+ (1,0) [0|7] ""  Vector__XXX
	SG_ SLS_Helligkeit_IR : 39|8@1+ (250,0) [0|7000] "Lux"  Vector__XXX

BO_ 2527679669 RLS_02: 8 ICAS1_X_Gateway
	SG_ LS_Autobahnfahrlicht : 22|1@1+ (1,0) [0|1] ""  SmartLight_01
	SG_ LS_Dunkel : 21|1@1+ (1,0) [0|1] ""  SmartLight_01
	SG_ LS_Error : 26|1@1+ (1,0) [0|1] ""  SmartLight_01
	SG_ LS_Helligkeit_FW : 40|10@1+ (6,0) [0|6126] "Lux"  HUD,SmartLight_01
	SG_ LS_Helligkeit_IR : 32|8@1+ (400,0) [0|101200] "Lux"  HUD,SmartLight_01
	SG_ LS_Licht_ein : 19|1@1+ (1,0) [0|1] ""  SmartLight_01
	SG_ LS_Licht_ein_invers : 20|1@1+ (1,0) [0|1] ""  SmartLight_01
	SG_ RLS_02_BZ : 8|4@1+ (1,0) [0|15] ""  HUD
	SG_ RLS_02_CRC : 0|8@1+ (1,0) [0|255] ""  HUD
	SG_ RLS_Qualifizierungsbit : 12|1@1+ (1,0) [0|1] ""  SmartLight_01
	SG_ RLS_ResponseError : 27|1@1+ (1,0) [0|1] ""  Vector__XXX
	SG_ RLS_Vorfeldhelligkeit_Boost : 28|4@1+ (1,0) [0|15] ""  HUD,SmartLight_01
	SG_ RS_AdaptierungError : 24|1@1+ (1,0) [0|1] ""  Vector__XXX
	SG_ RS_Error : 25|1@1+ (1,0) [0|1] ""  Vector__XXX
	SG_ RS_Regenfahrlicht : 23|1@1+ (1,0) [0|1] ""  Vector__XXX
	SG_ RS_Regenmenge : 52|4@1+ (1,0) [0|15] ""  Vector__XXX
	SG_ RS_Schwall : 16|1@1+ (1,0) [0|1] ""  Vector__XXX
	SG_ RS_Verglasung_schliessen : 17|1@1+ (1,0) [0|1] ""  Vector__XXX
	SG_ RS_versParklage_Wischer : 18|1@1+ (1,0) [0|1] ""  Vector__XXX
	SG_ RS_Wischergeschwindigkeit : 13|3@1+ (1,0) [0|7] ""  Vector__XXX

BO_ 2463978697 SAL_01: 8 ICAS1_X_Gateway
	SG_ AFS_Lampe : 47|1@1+ (1,0) [0|1] ""  Kombi
	SG_ BCM2_Bremsl_durch_ECD : 18|1@1+ (1,0) [0|1] ""  Vector__XXX
	SG_ DLI_Ambex_RefStatus : 60|3@1+ (1,0) [0|7] ""  Vector__XXX
	SG_ LWR_Lampe : 46|1@1+ (1,0) [0|1] ""  Kombi
	SG_ LWR_Reisemodus_Texte : 48|2@1+ (1,0) [0|3] ""  Kombi
	SG_ LWR_SollDC : 32|8@1+ (0.5,0) [0|100] "PerCent"  Vector__XXX
	SG_ SAL_01_BZ : 8|4@1+ (1,0) [0|15] ""  Vector__XXX
	SG_ SAL_01_CRC : 0|8@1+ (1,0) [0|255] ""  Vector__XXX
	SG_ SAL_Aussenbeleuchtung_defekt : 63|1@1+ (1,0) [0|1] ""  Vector__XXX
	SG_ SAL_Blinkerzyklus_L : 45|1@1+ (1,0) [0|1] ""  Vector__XXX
	SG_ SAL_Blinkerzyklus_R : 44|1@1+ (1,0) [0|1] ""  Vector__XXX
	SG_ SAL_BLK_L_Anf : 26|1@1+ (1,0) [0|1] ""  Vector__XXX
	SG_ SAL_BLK_R_Anf : 25|1@1+ (1,0) [0|1] ""  Vector__XXX
	SG_ SAL_Bremszyklus : 43|1@1+ (1,0) [0|1] ""  Vector__XXX
	SG_ SAL_BRL_Anf : 20|1@1+ (1,0) [0|1] ""  Vector__XXX
	SG_ SAL_CH_Anf : 22|1@1+ (1,0) [0|1] ""  Vector__XXX
	SG_ SAL_HGB_Anf : 30|1@1+ (1,0) [0|1] ""  Vector__XXX
	SG_ SAL_Kl_15 : 59|1@1+ (1,0) [0|1] ""  Vector__XXX
	SG_ SAL_Kl_15_vFzg : 58|1@1+ (1,0) [0|1] ""  Vector__XXX
	SG_ SAL_Kl_15_vFzg_S : 57|1@1+ (1,0) [0|1] ""  Vector__XXX
	SG_ SAL_KL_50 : 51|1@1+ (1,0) [0|1] ""  Vector__XXX
	SG_ SAL_KL_50_5s : 56|1@1+ (1,0) [0|1] ""  Vector__XXX
	SG_ SAL_Kl_75 : 55|1@1+ (1,0) [0|1] ""  Vector__XXX
	SG_ SAL_KL_75_vFzg : 54|1@1+ (1,0) [0|1] ""  Vector__XXX
	SG_ SAL_KL_75a : 53|1@1+ (1,0) [0|1] ""  Vector__XXX
	SG_ SAL_KL_75a_vFzg : 52|1@1+ (1,0) [0|1] ""  Vector__XXX
	SG_ SAL_KZL_Anf : 50|1@1+ (1,0) [0|1] ""  Vector__XXX
	SG_ SAL_LDS_Abblendlicht_Anf : 12|1@1+ (1,0) [0|1] ""  Vector__XXX
	SG_ SAL_LDS_Assistenzfahrlicht_Anf : 13|1@1+ (1,0) [0|1] ""  Vector__XXX
	SG_ SAL_LDS_Nullstellung_Anf : 14|1@1+ (1,0) [0|1] ""  Vector__XXX
	SG_ SAL_LDS_Standlicht_Anf : 15|1@1+ (1,0) [0|1] ""  Vector__XXX
	SG_ SAL_LH_Anf : 19|1@1+ (1,0) [0|1] ""  Vector__XXX
	SG_ SAL_NSL_Anf : 28|1@1+ (1,0) [0|1] ""  Vector__XXX
	SG_ SAL_PL_L_Anf : 24|1@1+ (1,0) [0|1] ""  Vector__XXX
	SG_ SAL_PL_R_Anf : 23|1@1+ (1,0) [0|1] ""  Vector__XXX
	SG_ SAL_RFL_Anf : 27|1@1+ (1,0) [0|1] ""  Vector__XXX
	SG_ SAL_SL_Anf : 29|1@1+ (1,0) [0|1] ""  Vector__XXX
	SG_ SAL_WBT_Bel : 21|1@1+ (1,0) [0|1] ""  Vector__XXX
	SG_ SBBR_SL_AnimDimm_Freigabe : 16|2@1+ (1,0) [0|3] ""  Vector__XXX

BO_ 517 SAM_01: 8 ICAS1_X_Gateway
	SG_ BCM_Bremsbelag_Sensor_CND : 33|1@1+ (1,0) [0|1] ""  Kombi
	SG_ BCM_Bremsbelag_Sensor_NAR : 32|1@1+ (1,0) [0|1] ""  Kombi
	SG_ BCM_Bremsbelag_Sensor_Rdw : 30|2@1+ (1,0) [0|3] ""  Kombi
	SG_ BCM_KiSi_Umschalt_gesperrt : 47|1@1+ (1,0) [0|1] ""  Vector__XXX
	SG_ BCM_Tankklappensteller_Fehler : 56|1@1+ (1,0) [0|1] ""  Vector__XXX
	SG_ BRL_Bremslicht_Schalter : 36|1@1+ (1,0) [0|1] ""  Vector__XXX
	SG_ HD_Hauptraste : 53|1@1+ (1,0) [0|1] ""  Vector__XXX
	SG_ HD_Vorraste : 54|1@1+ (1,0) [0|1] ""  Vector__XXX
	SG_ HW_Drehfalle_Tuer_HL : 41|1@1+ (1,0) [0|1] ""  ICAS3_Gateway
	SG_ HW_Drehfalle_Tuer_HR : 40|1@1+ (1,0) [0|1] ""  ICAS3_Gateway
	SG_ HW_HD_Taste_Innenraum : 57|1@1+ (1,0) [0|1] ""  Vector__XXX
	SG_ HW_HSB_erkannt : 52|1@1+ (1,0) [0|1] ""  Vector__XXX
	SG_ HW_MH_Schalter1 : 60|1@1+ (1,0) [0|1] ""  Vector__XXX
	SG_ HW_MH_Schalter2 : 59|1@1+ (1,0) [0|1] ""  Vector__XXX
	SG_ HW_Softtouch_betaetigt : 58|1@1+ (1,0) [0|1] ""  Vector__XXX
	SG_ HW_Status_Schloss_gesafet_HL : 45|1@1+ (1,0) [0|1] ""  Vector__XXX
	SG_ HW_Status_Schloss_gesafet_HR : 44|1@1+ (1,0) [0|1] ""  Vector__XXX
	SG_ HW_Status_Schloss_verriegelt_HL : 43|1@1+ (1,0) [0|1] ""  ICAS3_Gateway
	SG_ HW_Status_Schloss_verriegelt_HR : 42|1@1+ (1,0) [0|1] ""  ICAS3_Gateway
	SG_ HW_Tankdeckel_offen : 46|1@1+ (1,0) [0|1] ""  Vector__XXX
	SG_ HW_Toggle_Taster : 61|1@1+ (1,0) [0|1] ""  Vector__XXX
	SG_ KST_BSW_Fehlermode2 : 39|1@1+ (1,0) [0|1] ""  Vector__XXX
	SG_ KST_BSW_Klemme_15_HW_Ist : 34|2@1+ (1,0) [0|3] ""  Vector__XXX
	SG_ KST_BSW_Klemmenhochschalten_Sper : 55|1@1+ (1,0) [0|1] ""  Vector__XXX
	SG_ KST_BSW_Not_Taster_betaetigt : 62|1@1+ (1,0) [0|1] ""  Vector__XXX
	SG_ KST_BSW_ZAT_betaetigt : 63|1@1+ (1,0) [0|1] ""  Vector__XXX
	SG_ SAL_li1_Blinker_Status : 37|1@1+ (1,0) [0|1] ""  Vector__XXX
	SG_ SAL_re1_Blinker_Status : 38|1@1+ (1,0) [0|1] ""  Vector__XXX
	SG_ SAM_01_BZ : 8|4@1+ (1,0) [0|15] ""  Vector__XXX
	SG_ SAM_01_CRC : 0|8@1+ (1,0) [0|255] ""  Vector__XXX
	SG_ SAM_Fehler_DC_LWR : 29|1@1+ (1,0) [0|1] ""  Vector__XXX
	SG_ ZV_Ladeklappe_VerEntriegeln : 12|2@1+ (1,0) [0|3] ""  Vector__XXX
	SG_ ZV_LadeklappenStatus : 14|1@1+ (1,0) [0|1] ""  Vector__XXX

BO_ 1522 Sensorik_Dimmung_01: 2 Fahrerdisplay_Kombi
	SG_ KBI_Dimmpoti : 8|7@1+ (1,0) [0|100] "PerCent"  Vector__XXX
	SG_ KBI_Phototransistor : 0|8@1+ (1,0) [0|253] ""  ICAS1_X_Gateway

BO_TX_BU_ 1175 :ICAS1_X_Gateway;
BO_TX_BU_ 1355 :ICAS1_X_Gateway;
BO_TX_BU_ 2527679498 :ICAS1_X_Gateway;
BO_TX_BU_ 319 :ICAS1_X_Gateway;
BO_TX_BU_ 1122 :ICAS3_Gateway,ZR_MIB_TOP_ab_Gen3;
BO_TX_BU_ 1123 :ICAS3_Gateway,ZR_MIB_TOP_ab_Gen3;
BO_TX_BU_ 1124 :ICAS3_Gateway,ZR_MIB_TOP_ab_Gen3;
BO_TX_BU_ 1125 :ICAS3_Gateway,ZR_MIB_TOP_ab_Gen3;
BO_TX_BU_ 1616 :ICAS3_Gateway,ZR_MIB_TOP_ab_Gen3;
BO_TX_BU_ 2527679748 :ICAS1_X_Gateway;
BO_TX_BU_ 2463978734 :ICAS1_X_Gateway;
BO_TX_BU_ 2527679742 :ICAS1_X_Gateway;
BO_TX_BU_ 1525 :ICAS1_X_Gateway;
BO_TX_BU_ 1527 :ICAS1_X_Gateway;
BO_TX_BU_ 2527679676 :ICAS1_X_Gateway;
BO_TX_BU_ 1610 :ICAS1_X_Gateway;
BO_TX_BU_ 1440 :ICAS1_X_Gateway;
BO_TX_BU_ 2527679669 :ICAS1_X_Gateway;
BO_TX_BU_ 2463978697 :ICAS1_X_Gateway;
BO_TX_BU_ 517 :ICAS1_X_Gateway;
BO_TX_BU_ 1522 :Fahrerdisplay_Kombi;
CM_ BO_ 1175 "neue Struktur ab MQB ohne KD-Fehler";
CM_ BO_ 1355 "neue Struktur ab MQB ohne KD-Fehler";
CM_ BO_ 1522 "MQB";
CM_ SG_ 1175 PDC_Tonausgabe_Front "In Abhï?½ngigkeit der Systemaktivitï?½ten werden unterschiedliche Tonwarnungen ausgegeben. \nKombi spielt entsprechende WAV.-Datei ï?½ber internen Audiomaster ab.\n\n0 = kein Ton\n1 = Intervallton 1\n2 = Intervallton 2\n3 = Intervallton 3\n4 = Intervallton 4\n5";
CM_ SG_ 1175 PDC_Tonausgabe_Heck "In Abhï?½ngigkeit der Systemaktivitï?½ten werden unterschiedliche Tonwarnungen ausgegeben. \nKombi spielt entsprechende WAV.-Datei ï?½ber internen Audiomaster ab.\n\n0 = kein Ton\n1 = Intervallton 1\n2 = Intervallton 2\n3 = Intervallton 3\n4 = Intervallton 4\n5";
CM_ SG_ 1175 PH_Abschaltursache "Abschaltursache bleibt bis zur nï?½chsten Aktivierung bzw. bis KL15 aus gesetzt\nIm Fehlerfall (blinkende LED) wird '7' gesendet obwohl das System noch aktiv ist, bei 'geheiltem' Fehler wird sofort wieder der Zustand '0' gesendet";
CM_ SG_ 1175 PH_Anf_Audioabsenkung "Es gibt zwei unterschiedliche Nachlauftimer fï?½r dieses Bit:\n1. normale Funktion\n2. Demotonausgabe";
CM_ SG_ 1175 PH_Anf_Verdeck "Anforderung an ein Verdeck-System, die vom Fahrer angeforderte ï?½ffnung/Schlieï?½ung zu verhindern";
CM_ SG_ 1175 PH_defekt "Zeigt an das sich die Parkhilfe im Fehlerzustand befindet. Signal bleibt bis zur nï?½chsten 'Gut-Aktivierung' gesetzt.\nSpezialfall: Sensordefekt hinten bei Anhï?½ngerbetrieb. Anhï?½nger wird abgesteckt Fehler wird gesetzt. Fehlerfall bleibt bis Behebung des De";
CM_ SG_ 1175 PH_Display_Kundenwunsch "Anzeige der bei Aktivierung verwendeten Parameter bzgl. Kundenwunsch Displayanziege. ï?½nderungen werden erst bei erneuter Aktivierung aktualisiert.";
CM_ SG_ 1175 PH_Frequenz_hinten "Uebertragung der aktuell im APS Steuergeraet gespeicherten Werte fuer Tongeber Frequenz hinten\nAnzeige der aktuell verwendeten Parameter (nicht zwingend die abgespeicherten - da Werte erst 2s nach der letzten ï?½nderung gespeichert werden!)";
CM_ SG_ 1175 PH_Frequenz_vorn "Uebertragung der aktuell im APS Steuergeraet gespeicherten Werte fuer Tongeber Frequenz vorne\nAnzeige der aktuell verwendeten Parameter (nicht zwingend die abgespeicherten - da Werte erst 2s nach der letzten ï?½nderung gespeichert werden!)";
CM_ SG_ 1175 PH_gestoert "Eine Stï?½rung ist aufgetreten, der die Parkhilfe in einen 'gestï?½rt-Zustand' versetzt, z.B. massiver Fremdultraschall, Vereisung, Schnee.Derzeit nur fï?½r Stï?½rschall benutzt, da keinerlei andere Erkennung implementiert.";
CM_ SG_ 1175 PH_Lautstaerke_hinten "Uebertragung der aktuell im APS Steuergeraet gespeicherten Werte fuer Tongeber Lautstaerke hinten\nAnzeige der aktuell verwendeten Parameter (nicht zwingend die abgespeicherten - da Werte erst 2s nach der letzten ï?½nderung gespeichert werden!)";
CM_ SG_ 1175 PH_Lautstaerke_vorn "Uebertragung der aktuell im APS Steuergeraet gespeicherten Werte fuer Tongeber Lautstaerke vorn.\nAnzeige der aktuell verwendeten Parameter (nicht zwingend die abgespeicherten - da Werte erst 2s nach der letzten ï?½nderung gespeichert werden!)";
CM_ SG_ 1175 PH_nachtr_Stopp_Anf "Dieses Signal dient dem Motor als Trigger, dass ein nachtrï?½glicher Motorstopp eingeleitet werden kann, wenn es die Bedingungen des StSt Koordinators dies zulassen. ";
CM_ SG_ 1175 PH_Opt_Anz_H_Hindernis "mindestens 1 Segment wird fï?½r den hinteren Detekionsbereich dargestellt, also ein Hindernis ist im Detektionsbereich. Funktion nur bei gesicherter Rï?½ckmeldung vom ASG gegeben.";
CM_ SG_ 1175 PH_Opt_Anz_V_Hindernis "mindestens 1 Segment wird fï?½r den vorderen Detekionsbereich dargestellt, also ein Hindernis ist im Detektionsbereich. Funktion nur bei gesicherter Rï?½ckmeldung vom ASG gegeben.";
CM_ SG_ 1175 PH_Opt_Anzeige_H_ein "OPS hinten ist im Display aktiv bzw. Anzeigemodule hinten sind eingeschaltet. Funktion nur bei gesicherter Rï?½ckmeldung vom ASG gegeben.";
CM_ SG_ 1175 PH_Opt_Anzeige_V_ein "OPS vorne ist im Display aktiv bzw. Anzeigemodule vorne sind eingeschaltet. Funktion nur bei gesicherter Rï?½ckmeldung vom ASG gegeben.";
CM_ SG_ 1175 PH_StartStopp_Info "Stopp-Freigabe und Start-Anforderung an den Start-Stopp-Koordinator";
CM_ SG_ 1175 PH_Stoermeldung "Meldung einer Stï?½rung der PDC an das Kombi";
CM_ SG_ 1175 PH_Systemzustand "Aktivierungsursache wird fï?½r die Dauer der Aktivierung gemeldet.\nIm Fehlerfall bei atkviem System wechselt das Signal auf '7'\n(siehe auch 'Abschaltursache')";
CM_ SG_ 1175 PH_Taster "Taster Status (fï?½r RVC/TopView)";
CM_ SG_ 1175 PH_Tongeber_H_aktiv "Rohsignal fï?½r 'Tongeber hinten wird angesteuert', verlï?½ngerbar mit Nachlauftimer.\nBit wird nicht wï?½hrend des Stellgliedtests angesteuert.";
CM_ SG_ 1175 PH_Tongeber_H_verfuegbar "Tongeber ist fï?½r die Tonausgabe fï?½r externe Funktionen verfï?½gbar. PDC ist aktiv und Tongeber ist nicht gestï?½rt.";
CM_ SG_ 1175 PH_Tongeber_mute "Die Akustikausgabe des Systems wird unterdrï?½ckt, z.B. Wï?½hlhebel in 'P', Parlbremse geschlossen (8-Kanal-System)";
CM_ SG_ 1175 PH_Tongeber_V_aktiv "Rohsignal fï?½r 'Tongeber vorne wird angesteuert', verlï?½ngerbar mit Nachlauftimer.\nBit wird nicht wï?½hrend des Stellgliedtests angesteuert.";
CM_ SG_ 1175 PH_Visualisierung "Signal zeigt den Partnersteuergerï?½ten RearView/TopView/ARA/... den aktuellen Status der Visualisierung des OPS. Die Partnersteuergerï?½te kï?½nnen dadurch auch ihre Aufschaltung an dieses Signal koppeln.";
CM_ SG_ 1175 PLA_Anf_Aufschaltung_RVC "Anforderung der Aufschaltung RVC durch PLA";
CM_ SG_ 1355 APS_PaCo_WarningTones "Signalisierung, ob seitens der Kundenfunktion APS eine akustische Warntonausgabe mï?½glich ist.\n\n0 Not_Possible: Akustische Tonausgabe derzeit nicht mï?½glich\n1 Possible: Akustische Tonausgabe derzeit mï?½glich";
CM_ SG_ 1355 APSOPS_PaCo_ApproachingFront "Signalisierung einer Annï?½herung an ein kritisches Hindernis im vorderen Fahrzeugbereich.\n\n0 No_Obstacle_Approaching: APSOPS erkennt kein Hindernis vor dem Fahrzeug\n1 Obstacle_Approaching: APSOPS erkennt ein Hindernis vor dem Fahrzeug";
CM_ SG_ 1355 APSOPS_PaCo_ApproachingRear "Signalisierung einer Annï?½herung an ein kritisches Hindernis im hinteren Fahrzeugbereich.\n\n0 No_Obstacle_Approaching: APSOPS erkennt kein Hindernis hinter dem Fahrzeug\n1 Obstacle_Approaching: APSOPS erkennt ein Hindernis hinter dem Fahrzeug";
CM_ SG_ 1355 APSOPS_PaCo_Button "Signalisierung eines gedrï?½ckten PDC-Hardkeys.\n\n0 Init_Or_Not_Equipped: Init oder kein PDC-Hardkey vorhanden\n1 Button_Not_Pressed: PDC-Hardkey ist nicht gedrï?½ckt\n2 Button_Pressed_Debounced: PDC-Hardkey ist gedrï?½ckt (entprellt)\n3 Error: Fehler";
CM_ SG_ 1355 APSOPS_PaCo_FunctionState "Signalisierung des Funktionszustandes von APSOPS.\n\n0 No_Error: es liegt kein Fehler von APSOPS vor\n1 Sensor_Defect: es liegt ein Fehler aufgrund eines Sensordefekts von APSOPS vor, der ï?½ber Teilverfï?½gbarkeit abgehandelt warden kann\n2 Sensor_Contaminat";
CM_ SG_ 1355 APSOPS_PaCo_MainState "Hauptzustand der Kundenfunktion APSOPS.\n\n0 Init: APSOPS befindet sich in der Initialisierung\n1 InOperation_NoError: APSOPS befindet sich im Betrieb ohne Fehler\n7 Fehler: APSOPS befindet sich im Fehlerzustand";
CM_ SG_ 1355 APSOPS_PaCo_ObstacleDetectFront "Signalisierung, wenn im vorderen Fahrzeugbereich Hindernisse detektiert werden. Der vordere Fahrzeugbereich umfasst alle Hindernisse vor dem Fahrzeug bis zur Fahrzeugmitte und damit auch die beiden vorderen seitlichen Sektoren. Es wird immer der Signalzus";
CM_ SG_ 1355 APSOPS_PaCo_ObstacleDetectRear "Signalisierung, wenn im hinteren Fahrzeugbereich Hindernisse detektiert werden. Der hintere Fahrzeugbereich umfasst alle Hindernisse hinter dem Fahrzeug bis zur Fahrzeugmitte und damit auch die beiden hinteren seitlichen Sektoren. Es wird immer der Signal";
CM_ SG_ 1355 PH_Aufschaltursache "Der Grund fï?½r die Aufschaltung der Einparkhilfe wird angegeben, z.B. bei der Aktivierung der Einparkhilfe durch eine andere Funktion, wird diese Funktion als Aktivierungsursache fï?½r die Dauer der Aktivierung gemeldet.\nDas Signal wird den PH_Systemzustand";
CM_ SG_ 1355 PH_Ton_Ausgabe "Anforderung einer Tonausgabe beim MIB3 durch die Parkhilfe";
CM_ SG_ 1355 PH_Ton_Lautstaerke "Wunschlautstï?½rke der Tonanforderung beim MIB3 durch die Parkhilfe.";
CM_ SG_ 1355 PH_Ton_Pausenlaenge "Pause zwischen den angeforderten Tï?½nen beim MIB3 durch die Parkhilfe. Nur fï?½r Intervalltï?½ne, nicht relevant fï?½r Dauerton und Quittierungston.";
CM_ SG_ 1355 PH_Ton_Richtung "Abspielrichtung des angeforderten Ton beim MIB3 durch die Parkhilfe";
CM_ SG_ 1355 PH_Verschmutzungsmeldung "Meldung einer Verschmutzung/Vereisung der PDC an das Kombi";
CM_ SG_ 1355 PH_WAH_Meldung "Steuert die HMI-Meldungen im Kombi fï?½r den Wiederanfahrhinweis";
CM_ SG_ 1355 RBF_Anf_Meldungen "ï?½ber das Signal werden die RBF Meldungen von der Funktion RBF am Kombi angefordert. Ursprï?½nglich waren die Meldungen in der PLA_Status_02 Botschaft. Da RBF auch nur mit PDC einsetzt wird ein neuse  Signal benï?½tigt.";
CM_ SG_ 1355 RBF_PaCo_Anf_Meldungen "ï?½ber das Signal werden die RBF Meldungen von der Funktion RBF ï?½ber den PaCo beim Infotainment bzw. Kombi angefordert.";
CM_ SG_ 1355 RBFMA_PaCo_BrakeIntervention "Signalisierung, ob die Kundenfunktion RBF/MA einen Bremseingriff ansteuert.\n\n0 Inactive: RBF/MA steuert derzeit keinen Bremseingriff an\n1 Active_Rear: RBF/MA steuert derzeit einen Bremseingriff aufgrund eines Hindernisses hinten an\n2 Active_Front: RBF";
CM_ SG_ 1355 RBFMA_PaCo_MainState "Hauptzustand der Kundenfunktion RBF/MA\n\n0 Init: RBF/MA befindet sich in der Initialisierung\n1 InOperation_NoError: RBF/MA befindet sich im Betrieb ohne Fehler\n2 Eingeschraenkt\n7 Fehler: RBF/MA befindet sich im Fehlerzustand";
CM_ SG_ 2527679498 IAA_Active_User_ID "Signal gibt die IAA Nutzer ID des aktiven IAA Nutzers an.";
CM_ SG_ 2527679498 IAA_Identified_User_ID "Signal gibt die IAA Nutzer ID des vom BCM identifizierten IAA Nutzers an";
CM_ SG_ 2527679498 IAA_PSO_wake_up "Signal zum Wake_up der IAA und PSO Komponenten im Kombi und in der OCU";
CM_ SG_ 2527679498 Perso_Aktiv "Status Personalisierung fï?½r den Fahrer aktiviert/ deaktiviert (via HMI)";
CM_ SG_ 2527679498 Perso_Bedienstelle "Signal zeigt an, ï?½ber welche Bedienstelle die Umschaltung des Benutzerkontos gestartet wurden.";
CM_ SG_ 2527679498 Perso_Fahrernummer "Signal gibt die jewels aktuelle Nummer des Fahrers fï?½r die Personalisierung an.\nNicht fï?½r AU736 und AU48x.";
CM_ SG_ 2527679498 Perso_Freigabe_Verstellung "Signal zeigt an, ob die Ergonomiefunktionen nach Umschaltung des Benutzerkontos verfahren dï?½rfen.";
CM_ SG_ 2527679498 Perso_Kontonummer "Signal gibt die jewels aktuelle Kontonummer fï?½r die Personalisierung an.\nNicht fï?½r AU736 und AU48x.";
CM_ SG_ 2527679498 Perso_Schreibschutz "Signal zeigt an, ob der Schreibschutz der Personalisierung aktiv ist.";
CM_ SG_ 2527679498 Perso_Status "Codierstatus der Personalisierung\nNicht fï?½r AU736 und AU49x.";
CM_ SG_ 2527679498 Perso_Steuerung "Signal gibt einen Steuerungsbefehl an die Funktionsteilnehmer der Personalisierung.\nNicht fï?½r AU736 und AU49x.";
CM_ SG_ 2527679498 Perso_Steuerungsparameter "Signal gibt einen Parameter zum Steuerungsbefehl (Signal Perso_Steuerung) fï?½r die Personalisierung an.\nNicht fï?½r AU736 und AU49x.";
CM_ SG_ 319 PreCrash_Anforderung_AFR "Anforderungen der Funktion PrecrashSeite an Fahrwerksregelung";
CM_ SG_ 319 PreCrash_BFS_KSV_verfahren "Ansteuerung der Kopfstuetze Beifahrerseite durch die Funktion PreCrash\n\nSignalwert 0x09 fï?½r vereinfachte Ansteuerung mit Logik im Sitz-SG (MQB37W)";
CM_ SG_ 319 PreCrash_BFS_Laengsverstellung "Ansteuerung der Laengsverstellung des Beifahrersitzes durch die PreCrash-Funktionen";
CM_ SG_ 319 PreCrash_BFS_Pneumatik_ansteuern "Ansteuerung des Beifahrersitzes durch die PreCrash-Funktionen";
CM_ SG_ 319 PreCrash_BFS_Sitzlehne_verfahren "Ansteuerung des Beifahrersitzes durch die PreCrash-Funktionen\n\nWert 0x06 und 0x07 fï?½r vereinfachte Ansteuerung Sitzlehne";
CM_ SG_ 319 PreCrash_Blinken "Safety Computer ï?½bermittelt Blinkverhalten bei einer PreCrash-Auslï?½sung an den BCM2";
CM_ SG_ 319 PreCrash_Charisma_FahrPr "Aktuell eingestelltes Fahrprogramm der Funktion PreCrash";
CM_ SG_ 319 PreCrash_Charisma_Status "Verfï?½gbarkeit der Funktion PreCrash fï?½r die Ansteuerung durch den Charisma_Koordinator";
CM_ SG_ 319 PreCrash_Fenster_schliessen "Anforderung Seitenscheiben schlieï?½en durch die Funktion PreCrash";
CM_ SG_ 319 PreCrash_Fo_KSV_verfahren "Ansteuerung der Kopfstuetzen im Fond durch die PreCrash-Funktionen";
CM_ SG_ 319 PreCrash_Fo_Pneumatik_ansteuern "Ansteuerung der Fondsitze durch die PreCrash-Funktionen";
CM_ SG_ 319 PreCrash_Fo_Sitzlehne_verfahren "Ansteuerung des Fondsitzes durch die PreCrash-Funktionen";
CM_ SG_ 319 PreCrash_FS_KSV_verfahren "Ansteuerung der Kopfstuetze Fahrerseite durch die PreCrash-Funktionen\n\nSignalwert 0x09 fï?½r vereinfachte Ansteuerung mit Logik im Sitz-SG (MQB37W)";
CM_ SG_ 319 PreCrash_FS_Laengsverstellung "Ansteuerung der Laengsverstellung des Fahrersitzes durch die PreCrash-Funktionen";
CM_ SG_ 319 PreCrash_FS_Pneumatik_ansteuern "Ansteuerung des Fahrersitzes durch die PreCrash-Funktionen";
CM_ SG_ 319 PreCrash_FS_Sitzlehne_verfahren "Ansteuerung des Fahrersitzes durch die PreCrash-Funktionen\n\nWert 0x06 und 0x07 fï?½r vereinfachte Ansteuerung Sitzlehne";
CM_ SG_ 319 PreCrash_Schiebedach_schliessen "Anforderung Schiebedach schlieï?½en durch die Funktion PreCrash";
CM_ SG_ 319 PreCrash_Tueren_Verriegeln "Anforderung Tï?½ren Verriegeln durch die Funktion PreCrash";
CM_ SG_ 319 SC_PreCrash_LED "Ansteuerung LED-Leiste im Kombi durch SC";
CM_ SG_ 319 SC_PreCrash_Texte "Safety Computer ï?½bermittelt Systemstatus der PreCrash Funktionen an Kombi";
CM_ SG_ 319 SC_PreCrash_Warnung "Safety Computer ï?½bermittelt Warnung der PreCrash Funktionen an Kombi";
CM_ SG_ 319 SC_PreSense_FCWP "Mitteilung an das NightVision, auf welche Art von Objekt eine Warnung angefordert wird";
CM_ SG_ 1122 PSD_Abzweigerichtung "Richtung, in der die Abzweigung von der Hauptroute abzweigt\n";
CM_ SG_ 1122 PSD_Abzweigewinkel "Winkel, unter dem die Abzweigung von der Hauptroute abzweigt.\n";
CM_ SG_ 1122 PSD_ADAS_Qualitaet "ADAS Qualtitï?½t des Streckensegments.";
CM_ SG_ 1122 PSD_Anfangskruemmung "Startkrï?½mmung der Klothoide des ï?½bermittelten abzweigenden Streckensegments. \n1/(1+0.155 * x^2) {1/m}'\n";
CM_ SG_ 1122 PSD_Anfangskruemmung_Vorz "Vorzeichen fï?½r die Startkrï?½mmung bei Abzweigungen\n";
CM_ SG_ 1122 PSD_Bebauung "Segement befindet sich innerhalb bebauten Gebietes";
CM_ SG_ 1122 PSD_Endkruemmung "'Endkrï?½mmung der Klotoide des ï?½bermittelten Streckensegments. Die Anfangskrï?½mmung des folgenden Streckensegments entspricht der Endkrï?½mmung dieses Segments. Krï?½mmung = 1/(1+0.155 * xï?½) [1/m]\n\n";
CM_ SG_ 1122 PSD_Fahrspuren_Anzahl "Anzahl der Fahrspuren in Fahrtrichtung\n";
CM_ SG_ 1122 PSD_Geradester_Pfad "Segment ist Teil des geradesten Pfades";
CM_ SG_ 1122 PSD_Idenditaets_ID "Identifier auf ein Streckensegment, dass mit dem aktuell ï?½bertragenen geometrisch identisch ist.";
CM_ SG_ 1122 PSD_Segment_ID "Identifier des prï?½diktiven Streckensegments\n";
CM_ SG_ 1122 PSD_Segment_Komplett "Zeigt, ob alle Attribute fï?½r das Segment ï?½bertragen worden sind\n";
CM_ SG_ 1122 PSD_Segmentlaenge "Gesamtlï?½nge des prï?½diktiven Streckensegments";
CM_ SG_ 1122 PSD_Strassenkategorie "Klassifizierung der Straï?½e des beschriebenen Segments\n";
CM_ SG_ 1122 PSD_Vorgaenger_Segment_ID "An dem Streckensegment mit diesem Identifier schlieï?½t sich das neue Segment mit der ID 'PSD_01_Segment_ID' an.\n";
CM_ SG_ 1122 PSD_wahrscheinlichster_Pfad "Identifiziert den vom Navigationssystem berechneten wahrscheinlichsten Pfad des Fahrzeuges. ";
CM_ SG_ 1123 PSD_Attribut_1_ID "Identifier des ersten Attributes";
CM_ SG_ 1123 PSD_Attribut_1_Offset "Positionsoffset im Segment fï?½r die Position des Attributs";
CM_ SG_ 1123 PSD_Attribut_1_Wert "Wert des ersten Attributes";
CM_ SG_ 1123 PSD_Attribut_2_ID "Identifier des zweiten Attributes";
CM_ SG_ 1123 PSD_Attribut_2_Offset "Positionsoffset im Segment fï?½r die Position des Attributs";
CM_ SG_ 1123 PSD_Attribut_2_Wert "Wert des zweiten Attributes";
CM_ SG_ 1123 PSD_Attribut_Segment_ID_05 "Identifier des Streckensegments, fï?½r das die weiteren Attribute in der Botschaft gï?½ltig sind";
CM_ SG_ 1123 PSD_Attribute_Komplett_05 "Zeigt, ob alle Attribute fï?½r das Segment ï?½bertragen worden sind";
CM_ SG_ 1123 PSD_Pos_Fahrspur "Spur, auf der sich das Fahrzeug aktuell befindet";
CM_ SG_ 1123 PSD_Pos_Fehler_Laengsrichtung "Laengsfehler der Positionierung";
CM_ SG_ 1123 PSD_Pos_Inhibitzeit "Zeitspanne zwischen Generierung der PSD Daten im Navigationssystem und Versand der Daten auf den Most\n";
CM_ SG_ 1123 PSD_Pos_Segment_ID "Identifier des Streckensegments, auf dem sich das Fahrzeug aktuell befindet\n";
CM_ SG_ 1123 PSD_Pos_Segmentlaenge "Verbleibende Lï?½nge des Streckensegments, auf dem sich das Fahrzeug aktuell befindet\n";
CM_ SG_ 1123 PSD_Pos_Standort_Eindeutig "Ist die Position des Fahrzeugs eindeutig dem aktuelle Segment zugeordnet, oder gibt es fahrbare alternative Segmente, die bei akteller GPS-Position ebenfalls als aktuelles Segment mï?½glich wï?½ren.";
CM_ SG_ 1124 PSD_06_Mux "Multiplex Zï?½hler fï?½r die PSD_06-Botschaft.\nDie unterschiedlichen Muxe folgen keiner festen Reihenfolge. Je nach Inhalt des PSD-Protokolls an der aktuellen Position werden jeweils die notwendigen PSD6-Botschaften gesendet.";
CM_ SG_ 1124 PSD_Attribut_3_ID "Identifier des dritten Attributes";
CM_ SG_ 1124 PSD_Attribut_3_Offset "Positionsoffset im Segment fï?½r die Position des Attributs";
CM_ SG_ 1124 PSD_Attribut_3_Wert "Wert des dritten Attributes";
CM_ SG_ 1124 PSD_Attribut_4_ID "Typ von Attribut 4";
CM_ SG_ 1124 PSD_Attribut_4_Offset "Offset von Attribut 4";
CM_ SG_ 1124 PSD_Attribut_4_Wert "Wert von Attribut 4";
CM_ SG_ 1124 PSD_Attribut_5_ID "Typ von Attribut 5";
CM_ SG_ 1124 PSD_Attribut_5_Offset "Offset von Attribut 5";
CM_ SG_ 1124 PSD_Attribut_5_Wert "Wert von Attribut 5";
CM_ SG_ 1124 PSD_Attribut_Segment_ID "Identifier des Streckensegments,fï?½r das die weiteren Attribute in der Botschaft gï?½ltig sind";
CM_ SG_ 1124 PSD_Attribute_Komplett_06 "Zeigt, ob alle Attribute fï?½r das Segment ï?½bertragen worden sind\n";
CM_ SG_ 1124 PSD_Baum_Ausrichtung "Ausrichtung des Fahrzeugsegments zu Nord";
CM_ SG_ 1124 PSD_Baum_Breite "WGS84 Breite des Fahrzeugsegments";
CM_ SG_ 1124 PSD_Baum_Breite_VZ "Vorzeichen WGS84 Breite des Fahrzeugsegments";
CM_ SG_ 1124 PSD_Baum_Laenge "WGS84 Laenge des Fahrzeugsegments";
CM_ SG_ 1124 PSD_Baum_Laenge_VZ "Vorzeichen WGS84 Laenge des Fahrzeugsegments";
CM_ SG_ 1124 PSD_Ges_Attribute_Komplett "Zeigt, ob alle Attribute fï?½r das Segment ï?½bertragen worden sind";
CM_ SG_ 1124 PSD_Ges_Geschwindigkeit_Gespann "Gilt diese Einschrï?½nkung der Geschwindigkeit fï?½r alle Fahrzeuge oder ausschlieï?½lich fï?½r PKW mit Gespann oder fï?½r LKW, Buss, etc.";
CM_ SG_ 1124 PSD_Ges_Geschwindigkeit_Std_Anf "Stunde, zu der die stï?½ndliche Geschwindigkeitsbegrenzung beginnt\n0h.. 24h";
CM_ SG_ 1124 PSD_Ges_Geschwindigkeit_Std_Ende "Stunde, an der die stï?½ndliche Geschwindigkeitsbegrenzung endet\n0h.. 24h";
CM_ SG_ 1124 PSD_Ges_Geschwindigkeit_Tag_Anf "Wochentag, an dem die tï?½gliche Geschwindigkeitsbegrenzung beginnt";
CM_ SG_ 1124 PSD_Ges_Geschwindigkeit_Tag_Ende "Wochentag, an dem die tï?½gliche Geschwindigkeitsbegrenzung endet";
CM_ SG_ 1124 PSD_Ges_Geschwindigkeit_Witter "Witterungsabhï?½ngigkeit der Geschwindigkeitsbegrenzung";
CM_ SG_ 1124 PSD_Ges_Gesetzlich_Kategorie "Kategorie fï?½r das legale Gebot";
CM_ SG_ 1124 PSD_Ges_Gesetzlich_Zusatz "Zusatz fï?½r das legale Gebot";
CM_ SG_ 1124 PSD_Ges_Offset "Positionsoffset im Segment fï?½r die Position des Attributs";
CM_ SG_ 1124 PSD_Ges_Segment_ID "Identifier des prï?½diktiven Streckensegments ab dem die Geschwindigkeitsbegrenzungen und mï?½gliche Einschrï?½nkungen gelten.\n";
CM_ SG_ 1124 PSD_Ges_Spur_Geschw_Begrenzung "Definition der Spuren, fï?½r die das ï?½bertragene Gebot gilt";
CM_ SG_ 1124 PSD_Ges_Typ "Typ der Geschwindigkeitsbegrenzung\n";
CM_ SG_ 1124 PSD_Ges_Verkehrszeichen_Quelle "Quelle der Verkehrszeicheninformation";
CM_ SG_ 1124 PSD_Ges_Wechselverkehrszeichen "Am Beginn des Segments ist ein Wechselverkehrszeichen angebracht.";
CM_ SG_ 1124 PSD_Steigung_1_A_Offset "Positionsoffset im Segment fï?½r die Position der Steigung 1 A";
CM_ SG_ 1124 PSD_Steigung_1_A_Steigung "Steigung des Segments ab Offset 1A";
CM_ SG_ 1124 PSD_Steigung_1_A_Vorz "Vorzeichen fï?½r Steigung 1 A";
CM_ SG_ 1124 PSD_Steigung_1_Attribute_kompl "Alle Steigungsdaten fï?½r dieses Segment gesendet";
CM_ SG_ 1124 PSD_Steigung_1_B_Offset "Positionsoffset im Segment fï?½r die Position der Steigung 1 B";
CM_ SG_ 1124 PSD_Steigung_1_B_Steigung "Steigung des Segments ab Offset 1B";
CM_ SG_ 1124 PSD_Steigung_1_B_Vorz "Vorzeichen fï?½r Steigung 1 B";
CM_ SG_ 1124 PSD_Steigung_1_Segment_ID "Identifier des prï?½diktiven Streckensegments, zu dem die  ersten beiden Steigungswerte dieser Botschaft gehï?½ren";
CM_ SG_ 1124 PSD_Steigung_2_Attribute_kompl "Alle Steigungsdaten fï?½r dieses Segment gesendet";
CM_ SG_ 1124 PSD_Steigung_2_Offset "Positionsoffset im Segment fï?½r die Position der Steigung 2";
CM_ SG_ 1124 PSD_Steigung_2_Segment_ID "Identifier des prï?½diktiven Streckensegments, zu dem der dritte Steigungswert dieser Botschaft gehï?½rt";
CM_ SG_ 1124 PSD_Steigung_2_Steigung "Steigung des Segments ab Offset 2";
CM_ SG_ 1124 PSD_Steigung_2_Vorz "Vorzeichen fï?½r Steigung 2";
CM_ SG_ 1124 PSD_Sys_Alter_Karte "Alter der Karte";
CM_ SG_ 1124 PSD_Sys_Geometrieguete "Maï?½ fï?½r die Gï?½te der Klothoidengeometrie.";
CM_ SG_ 1124 PSD_Sys_Geometrieguete_erweitert "Gï?½te der Kurvenreprï?½sentation der Klothoiden";
CM_ SG_ 1124 PSD_Sys_Geschwindigkeit_Einheit "Unterscheidung zwischen km/h und miles/h";
CM_ SG_ 1124 PSD_Sys_Laendercode "Lï?½ndercode\n";
CM_ SG_ 1124 PSD_Sys_Mapmatchingguete "Gï?½te des Mapmatchings";
CM_ SG_ 1124 PSD_Sys_Quali_Geometrien "Qualitï?½t der Geometrien in dieser Region";
CM_ SG_ 1124 PSD_Sys_Quali_Ortsinfo "Qualitï?½t Ortsinformationen (Bebauung, Ortsschild) dieser Region";
CM_ SG_ 1124 PSD_Sys_Quali_sonstige_Attribute "Qualitï?½t sonstiger Attribute dieser Region";
CM_ SG_ 1124 PSD_Sys_Quali_Steigungen "Qualitï?½t der Steigungen dieser Region";
CM_ SG_ 1124 PSD_Sys_Quali_Strassenkennz "Qualitï?½t Straï?½enkennzeichnungen dieser Region";
CM_ SG_ 1124 PSD_Sys_Quali_Tempolimits "Qualitï?½t Tempolimits dieser Region";
CM_ SG_ 1124 PSD_Sys_Quali_verfuegbar "Karte enthï?½lt gï?½ltige Qualitï?½tskriterien";
CM_ SG_ 1124 PSD_Sys_Quali_Vorfahrtsregelung "Qualitï?½t Vorfahrtsregelungen dieser Region";
CM_ SG_ 1124 PSD_Sys_Segment_ID "Identifier des prï?½diktiven Streckensegments ab dem die Systeminformationen gï?½ltig sind.\n";
CM_ SG_ 1124 PSD_Sys_US_State "Name des USA-State";
CM_ SG_ 1124 PSD_Sys_Verkehrsrichtung "Unterscheidung zwischen Linksverkehr und Rechtsverkehr";
CM_ SG_ 1124 PSD_Sys_Zielfuehrung "Zielfuehrung im Navigationssystem. Damit lï?½sst sich der wahrscheinlichste Pfad des Fahrzeuges zuverlï?½ssig angeben.";
CM_ SG_ 1124 PSD_Sys_Zielfuehrung_geaendert "Die Zielfï?½hrung (Route) hat sich geï?½ndert hat ohne dass der Fahrer eine neue Zielfï?½hrung gestartet hat";
CM_ SG_ 1124 PSD_Wechselverkehrszeichen_Typ "Typ des Wechselverkehrszeichen";
CM_ SG_ 1125 PSD_LR_01_MUX "Fehlende Beschreibung (Import)";
CM_ SG_ 1125 PSD_LR_Attribut_1_Offset "Relative Position fï?½r Attribut 1 im Profil.\nSignal wird nur bei aktiver PSD-Funktion zyklisch gesendet.";
CM_ SG_ 1125 PSD_LR_Attribut_1_Wert "Wert von Attribut 1 (Definition siehe PSD Spec)\nSignal wird nur bei aktiver PSD-Funktion zyklisch gesendet.";
CM_ SG_ 1125 PSD_LR_Attribut_2_Offset "Relative Position fï?½r Attribut 2 im Profil\nSignal wird nur bei aktiver PSD-Funktion zyklisch gesendet.";
CM_ SG_ 1125 PSD_LR_Attribut_2_Wert "Wert von Attribut 2 (Definition siehe PSD Spec)\nSignal wird nur bei aktiver PSD-Funktion zyklisch gesendet.";
CM_ SG_ 1125 PSD_LR_Attribut_3_Offset "Relative Position fï?½r Attribut 3 im Profil\nSignal wird nur bei aktiver PSD-Funktion zyklisch gesendet.";
CM_ SG_ 1125 PSD_LR_Attribut_3_Wert "Wert von Attribut 3 (Definition siehe PSD Spec)\nSignal wird nur bei aktiver PSD-Funktion zyklisch gesendet.";
CM_ SG_ 1125 PSD_LR_Fahrzeug_Pos "Position des Fahrzeug in % relativ zur Gesamtlaenge des Profils.\nSignal wird nur bei aktiver PSD-Funktion zyklisch gesendet.";
CM_ SG_ 1125 PSD_LR_Globale_Steigung "Gesamtsteigung der in diesem  Profil ï?½bertragenen Strecke.\nSignal wird nur bei aktiver PSD-Funktion zyklisch gesendet.";
CM_ SG_ 1125 PSD_LR_Globale_Steigung_Vorz "Vorzeichen fï?½r globale Steigung des Profils.\nSignal wird nur bei aktiver PSD-Funktion zyklisch gesendet.";
CM_ SG_ 1125 PSD_LR_Koeff_1_Amp "Fehlende Beschreibung (Import)";
CM_ SG_ 1125 PSD_LR_Koeff_1_Phase "Phasenwert des ersten FFT-Koeffizienten.\nSignal wird nur bei aktiver PSD-Funktion zyklisch gesendet.";
CM_ SG_ 1125 PSD_LR_Koeff_2_Amp "Fehlende Beschreibung (Import)";
CM_ SG_ 1125 PSD_LR_Koeff_2_Phase "Phasenwert des zweiten FFT-Koeffizienten.\nSignal wird nur bei aktiver PSD-Funktion zyklisch gesendet.";
CM_ SG_ 1125 PSD_LR_Koeff_3_Amp "Fehlende Beschreibung (Import)";
CM_ SG_ 1125 PSD_LR_Koeff_3_Phase "Phasenwert des dritten FFT-Koeffizienten.\nSignal wird nur bei aktiver PSD-Funktion zyklisch gesendet.";
CM_ SG_ 1125 PSD_LR_Koeffizientensatz_Nr "Nummer des aktuell ï?½bertragenen Koeffizientansatzes.\nSignal wird nur bei aktiver PSD-Funktion zyklisch gesendet.";
CM_ SG_ 1125 PSD_LR_Max_Koeff_Amp "Maximale Hï?½he der ï?½bertragenen Amplitudenwerte.\nSignal wird nur bei aktiver PSD-Funktion zyklisch gesendet.";
CM_ SG_ 1125 PSD_LR_Profil_Laenge "Gesamtlï?½nge des ï?½bertragenen Profils.\nSignal wird nur bei aktiver PSD-Funktion zyklisch gesendet.";
CM_ SG_ 1125 PSD_LR_Profil_Nummer "Nummer des aktuell ï?½bertragenen Profils";
CM_ SG_ 1125 PSD_LR_Reset "Reset-Signal, wenn der PSD-LR-Baum ungï?½ltig wird.\nSignal wird nur bei aktiver PSD-Funktion zyklisch gesendet.";
CM_ SG_ 1125 PSD_LR_Steigung_1_Offset "Relative Position fï?½r die Steigung 1 im Profil.\nSignal wird nur bei aktiver PSD-Funktion zyklisch gesendet.";
CM_ SG_ 1125 PSD_LR_Steigung_1_Vorz "Vorzeichen fï?½r Steigung 1.\nSignal wird nur bei aktiver PSD-Funktion zyklisch gesendet.";
CM_ SG_ 1125 PSD_LR_Steigung_1_Wert "Mittlere Steigung zwischen dem Offset 1 und dem letzten Steigungswert.\nSignal wird nur bei aktiver PSD-Funktion zyklisch gesendet.";
CM_ SG_ 1125 PSD_LR_Steigung_2_Offset "Relative Position fï?½r die Steigung 2 im Profil.\nSignal wird nur bei aktiver PSD-Funktion zyklisch gesendet.";
CM_ SG_ 1125 PSD_LR_Steigung_2_Vorz "Vorzeichen fï?½r Steigung 2.\nSignal wird nur bei aktiver PSD-Funktion zyklisch gesendet.";
CM_ SG_ 1125 PSD_LR_Steigung_2_Wert "Mittlere Steigung zwischen dem Offset 2 und dem letzten Steigungswert.\nSignal wird nur bei aktiver PSD-Funktion zyklisch gesendet.";
CM_ SG_ 1125 PSD_LR_Steigung_3_Offset "Relative Position fï?½r die Steigung 3 im Profil.\nSignal wird nur bei aktiver PSD-Funktion zyklisch gesendet.";
CM_ SG_ 1125 PSD_LR_Steigung_3_Vorz "Vorzeichen fï?½r Steigung 3.\nSignal wird nur bei aktiver PSD-Funktion zyklisch gesendet.";
CM_ SG_ 1125 PSD_LR_Steigung_3_Wert "Mittlere Steigung zwischen dem Offset 3 und dem letzten Steigungswert.\nSignal wird nur bei aktiver PSD-Funktion zyklisch gesendet.";
CM_ SG_ 1616 PRIV_dataextraction_CDIS "Signal zur Steuerung der Datenausleitungsfunktion der CDIS\n\n0 = Init\n1 = Datenausleitungsfunktion deaktiviert\n2 = Datenausleitungsfunktion aktiviert";
CM_ SG_ 1616 RA_AM_Tuning "Das Signal kennzeichnet einen aktiven AM Suchlauf. Wï?½hrend des Suchlaufes wird die Frequenz = 0 ï?½bertragen.\n0 = frequency locked => Stï?½rquelle vermeidet die aktuelle Frequenz\n1 = AM tuning in progress => Stï?½rquelle abschalten bzw.PWM Signal auf DC umsch";
CM_ SG_ 1616 RA_Frequency "ï?½bermittlung der eingestellten Sendefrequenz AM oder FM, diese wird mit RA_Frequency_unit multipliziert.\nIm DAB oder Hybrid/Online Mode wird die aktuelle FM-Alternativfrequenz oder, falls nicht vorhanden, die zuletzt gehï?½rte Senderfrequenz ï?½bertragen (AM";
CM_ SG_ 1616 RA_Frequency_unit "Faktor fï?½r RA_Frequency\nbei AM: Faktor 0 = 1kHz\nsonst   Faktor 1 = 100kHz";
CM_ SG_ 1616 RA_PowerAmpOn "1 = Request for Amplifier; 0 = Amplifier mute/off";
CM_ SG_ 1616 RA_Radio_Error_Flag "1 = mindestens ein Kundendienstfehlerspeicher Eintrag vorhanden";
CM_ SG_ 1616 RA_Radio_mute "1=Radio is muted for telephone";
CM_ SG_ 1616 RA_Radio_on "1 = user perceived On";
CM_ SG_ 1616 RA_Radio_Surround "1 = Surround ON; 0 = Surround OFF\nrequests the Amp to switch Surroundmode";
CM_ SG_ 1616 RA_VNC_OFF "VNC = Vehicle Noice Cancellation;\n1 = VNC OFF; 0 = VNC ON\nrequests the Amp to switch VNC off";
CM_ SG_ 2527679748 TPMS_CalTyp "Specification type of target pressure";
CM_ SG_ 2527679748 TPMS_disable "Das Signal wird zur Textanzeige im Fahrerdisplay benï?½tigt. TPMS wird automatisch ausgeschaltet.";
CM_ SG_ 2527679748 TPMS_enable "Das Signal wird zur Textanzeige im Fahrerdisplay benï?½tigt. TPMS wird automatisch eingeschaltet.";
CM_ SG_ 2527679748 TPMS_LearningState "Status of the TPMS learning process";
CM_ SG_ 2527679748 TPMS_PDeFrLe "Pressure deviation between actual and set pressure front left, normalized to 20ï?½C";
CM_ SG_ 2527679748 TPMS_PDeFrRi "Pressure deviation between actual and set pressure front right, normalized to 20ï?½C";
CM_ SG_ 2527679748 TPMS_PDeReLe "Pressure deviation between actual and set pressure rear left, normalized to 20ï?½C";
CM_ SG_ 2527679748 TPMS_PDeReRi "Pressure deviation between actual and set pressure rear right, normalized to 20ï?½C";
CM_ SG_ 2527679748 TPMS_RaceTrckMdSts "State of the racetrack mode";
CM_ SG_ 2527679748 TPMS_SensBattStsFrLe "Sensor Battery Status front left";
CM_ SG_ 2527679748 TPMS_SensBattStsFrRi "Sensor Battery Status front right";
CM_ SG_ 2527679748 TPMS_SensBattStsReLe "Sensor Battery Status rear left";
CM_ SG_ 2527679748 TPMS_SensBattStsReRi "Sensor Battery Status rear right";
CM_ SG_ 2527679748 TPMS_SensPFrLe "Sensor measured pressure (tire pressure uncompensated) front left";
CM_ SG_ 2527679748 TPMS_SensPFrRi "Sensor measured pressure (tire pressure uncompensated) front right";
CM_ SG_ 2527679748 TPMS_SensPReLe "Sensor measured pressure (tire pressure uncompensated) rear left";
CM_ SG_ 2527679748 TPMS_SensPReRi "Sensor measured pressure (tire pressure uncompensated) rear right";
CM_ SG_ 2527679748 TPMS_SensSigAgeFrLe "Indicates the age of the sensor signal front left";
CM_ SG_ 2527679748 TPMS_SensSigAgeFrRi "Indicates the age of the sensor signal front right";
CM_ SG_ 2527679748 TPMS_SensSigAgeReLe "Indicates the age of the sensor signal rear left";
CM_ SG_ 2527679748 TPMS_SensSigAgeReRi "Indicates the age of the sensor signal rear right";
CM_ SG_ 2527679748 TPMS_SensStsFrLe "Own diagnostic of TPMS-Sensor front left";
CM_ SG_ 2527679748 TPMS_SensStsFrRi "Own diagnostic of TPMS-Sensor front right";
CM_ SG_ 2527679748 TPMS_SensStsReLe "Own diagnostic of TPMS-Sensor rear left";
CM_ SG_ 2527679748 TPMS_SensStsReRi "Own diagnostic of TPMS-Sensor rear right";
CM_ SG_ 2527679748 TPMS_SensTFrLe "Sensor measured temperature front left";
CM_ SG_ 2527679748 TPMS_SensTFrRi "Sensor measured temperature front right";
CM_ SG_ 2527679748 TPMS_SensTReLe "Sensor measured temperature rear left";
CM_ SG_ 2527679748 TPMS_SensTReRi "Sensor measured temperature rear right";
CM_ SG_ 2527679748 TPMS_SensTypFrLe "TPM sensor type front left";
CM_ SG_ 2527679748 TPMS_SensTypFrRi "TPM sensor type front right";
CM_ SG_ 2527679748 TPMS_SensTypReLe "TPM sensor type rear left";
CM_ SG_ 2527679748 TPMS_SensTypReRi "TPM sensor type rear right";
CM_ SG_ 2527679748 TPMS_TarPTmpDepFrLe "Temperature dependent target pressure front left";
CM_ SG_ 2527679748 TPMS_TarPTmpDepFrRi "Temperature dependent target pressure front right";
CM_ SG_ 2527679748 TPMS_TarPTmpDepReLe "Temperature dependent target pressure rear left";
CM_ SG_ 2527679748 TPMS_TarPTmpDepReRi "Temperature dependent target pressure rear right";
CM_ SG_ 2527679748 TPMS_Warn1 "General Warning Level 1";
CM_ SG_ 2527679748 TPMS_Warn1TireFrLe "Stage 1 warning for left front tires";
CM_ SG_ 2527679748 TPMS_Warn1TireFrRi "Stage 1 warning for left right tires";
CM_ SG_ 2527679748 TPMS_Warn1TireReLe "Stage 1 warning for left rear tires";
CM_ SG_ 2527679748 TPMS_Warn1TireReRi "Stage 1 warning for right front tires";
CM_ SG_ 2527679748 TPMS_Warn2 "General Warning Level 2";
CM_ SG_ 2527679748 TPMS_Warn2TireFrLe "Stage 2 warning for left front tires";
CM_ SG_ 2527679748 TPMS_Warn2TireFrRi "Stage 2 warning for right front tires";
CM_ SG_ 2527679748 TPMS_Warn2TireReLe "Stage 2 warning for left rear tires";
CM_ SG_ 2527679748 TPMS_Warn2TireReRi "Stage 2 warning for right rear tires";
CM_ SG_ 2527679748 TPMS_Warn3 "General Warning Level 3";
CM_ SG_ 2527679748 TPMS_Warn3TireFrLe "Stage 3 warning for left front tire";
CM_ SG_ 2527679748 TPMS_Warn3TireFrRi "Stage 3 warning for right front tire";
CM_ SG_ 2527679748 TPMS_Warn3TireReLe "Stage 3 warning for left rear tire";
CM_ SG_ 2527679748 TPMS_Warn3TireReRi "Stage 3 warning for right rear tire";
CM_ SG_ 2527679748 TPMS_Warn4 "General Warning Level 4";
CM_ SG_ 2527679748 TPMS_Warn4TireFrLe "Stage 4 warning for left front tyres";
CM_ SG_ 2527679748 TPMS_Warn4TireFrRi "Stage 4 warning for right front tyres";
CM_ SG_ 2527679748 TPMS_Warn4TireReLe "Stage 4 warning for left rear tyres";
CM_ SG_ 2527679748 TPMS_Warn4TireReRi "Stage 4 warning for right rear tyres";
CM_ SG_ 2527679748 TPMS_WarnAcoCalOk "Acoustic output for correct calibration (only necessary for switch calibration)";
CM_ SG_ 2527679748 TPMS_WarnCalOk "Text output for correct calibration (only necessary for switch calibration)";
CM_ SG_ 2527679748 TPMS_WarnCmftP "Warning when the comfort pressure is active";
CM_ SG_ 2527679748 TPMS_WarnFltIdc "Warning when the TPMS is in fault";
CM_ SG_ 2527679748 TPMS_WarnFr "Imbalance warning - front axle";
CM_ SG_ 2527679748 TPMS_WarnLmpStMil "Control of the TPMS lamp in the instrument cluster for system fault";
CM_ SG_ 2527679748 TPMS_WarnLmpStP "Control of the TPMS warning lamp  in the instrument cluster for pressure warning";
CM_ SG_ 2527679748 TPMS_WarnMaxV "Warning when the maximum speed for TPMS is active";
CM_ SG_ 2527679748 TPMS_WarnRaceTrckMdMinP "If the minimum pressure for race track mode is not reached, a warning should be displayed";
CM_ SG_ 2527679748 TPMS_WarnRe "Imbalance warning - rear axle";
CM_ SG_ 2527679748 TPMS_WarnSysLrn "Warning when the TPMS system is learning";
CM_ SG_ 2527679748 TPMS_WarnTmpFlt "Warning when the TPMS has a temporary fault";
CM_ SG_ 2527679748 TPMS_WarnWhlChgDet "Warning on wheel change detected";
CM_ SG_ 2527679748 TPMS_WhlChgDetFrLe "Wheel change front left detected";
CM_ SG_ 2527679748 TPMS_WhlChgDetFrRi "Wheel change front right detected";
CM_ SG_ 2527679748 TPMS_WhlChgDetReLe "Wheel change rear left detected";
CM_ SG_ 2527679748 TPMS_WhlChgDetReRi "Wheel change rear right detected";
CM_ SG_ 2463978734 VPS_PaCo_Button "Signalisierung eines gedrï?½ckten VPS-Hardkeys.\n\n\n0 Init_Or_Not_Equipped: Init oder kein VPS-Hardkey vorhanden\n1 Button_Not_Pressed: VPS-Hardkey ist nicht gedrï?½ckt\n2 Button_Pressed_Debounced: VPS-Hardkey ist gedrï?½ckt (entprellt)\n3 Error: Fehler";
CM_ SG_ 2463978734 VPS_PaCo_CurrentBirdview "Current-Birdview of the  VPS-Function";
CM_ SG_ 2463978734 VPS_PaCo_CurrentBowl "Control of the 3D view direction";
CM_ SG_ 2463978734 VPS_PaCo_CurrentCarOverlay "Ist-Car Overlay der VPS Funktion (aus, ein, transparent)";
CM_ SG_ 2463978734 VPS_PaCo_CurrentMode "Current-Mode of the  VPS-Function";
CM_ SG_ 2463978734 VPS_PaCo_CurrentRVCscreen "Signal zum Umschalten der Rearview Ansicht\n\nWerte:\n0x0=NoScreen\n0x1=Fullscreen\n0x2=Side-by-Side / Splitscreen";
CM_ SG_ 2463978734 VPS_PaCo_CurrentVideoState "Current-VideoState of the  VPS-Function";
CM_ SG_ 2463978734 VPS_PaCo_CurrentView "Current-View of the  VPS-Function";
CM_ SG_ 2463978734 VPS_PaCo_CurrGraphOverlay "Control of the graphical overlay on the video image";
CM_ SG_ 2463978734 VPS_PaCo_MainState "Main-State of the VPS-Function";
CM_ SG_ 2527679742 Kam_Anf_Meldung "ï?½ber das Signal fordert die Funktion AEB-PR die Warnmeldungen an den Fahrer an.";
CM_ SG_ 2527679742 Kam_PaCo_MainState "Hauptzustand der Kundenfunktion AEB-PR\n\n0 Init: AEB-PR befindet sich in der Initialisierung\n1 InOperation_NoError: AEB-PR befindet sich im Betrieb ohne Fehler\n2 Eingeschraenkt: AEB-PR ist eingeschraenkt verfï?½gbar\n7 Fehler: AEB-PR befindet sich im Feh";
CM_ SG_ 1525 RW_Gesamt_Reichweite "Reichweite fï?½r primï?½r und sekundï?½r Reichweite (eventuell Gewichtet)";
CM_ SG_ 1525 RW_Gesamt_Reichweite_Max_Anzeige "Angabe der Maximalen Anzeige der gesamten Reichweite.\nErgï?½nzt das Signal RW_Gesamt_Reichweite_Anzeige.Die Einheit dieser Signal ist ï?½ber RW_Reichweite_Einheit_Anzeige bereitgestellt.";
CM_ SG_ 1525 RW_Prim_Reichweitenv_Einheit "Fï?½r primï?½re  Reichweitenberechnung (KBI_Prim_Reichweitenverbrauch) zugrunde gelegte Einheit";
CM_ SG_ 1525 RW_Prim_Reichweitenverbrauch "Fï?½r primï?½re Reichweitenberechnung zugrunde gelegter Verbrauch";
CM_ SG_ 1525 RW_Primaer_Reichweite "Reichweite der primï?½ren Antriebsart";
CM_ SG_ 1525 RW_Reservewarnung_2_aktiv "Ansteuerung der Reservewarnung im Kombiinstrument (Leuchte und MFA-Warnhinweis). Wird gesetzt bei Erreichen / Unterschreiten eines unteren Reichweitenschwellwerts und zurï?½ckgenommen bei Erreich.\nZusï?½tzlich erfolgt eine logische Verknï?½pfung mit einer akti";
CM_ SG_ 1525 RW_RWDS_Lastprofil "Lastprofil zur Bestimmung der notwendigen Nachladeenergie (Reichweitendurchschnittstrom)";
CM_ SG_ 1527 RW_Gesamt_Reichweite_Anzeige "Reichweite fï?½r primï?½r und sekundï?½r Reichweite (eventuell Gewichtet) zur Anzeige im Kombi. Die Einheit dieser Signal ist ï?½ber RW_Reichweite_Einheit_Anzeige bereitgestellt.";
CM_ SG_ 1527 RW_Primaer_Reichweite_Anzeige "Reichweite der primï?½ren Antriebsart zur Anzeige im Kombi";
CM_ SG_ 1527 RW_Reichweite_Einheit_Anzeige "Einheit fï?½r Primaer-/Sekundaer-/Gesamt- Reichweite zur Anzeige im Kombi";
CM_ SG_ 1527 RW_Reservewarnung_aktiv "Ansteuerung der Reservewarnung im Kombiinstrument (Leuchte und MFA-Warnhinweis). Wird gesetzt bei Erreichen / Unterschreiten eines unteren Reichweitenschwellwerts und zurï?½ckgenommen bei Erreichen / ï?½berschreiten eines oberen Reichweitenschwellwerts.";
CM_ SG_ 1527 RW_Sek_Reichweitenv_Einheit "Fï?½r sekundï?½re Reichweitenberechnung (KBI_Sek_Reichweitenverbrauch) zugrunde gelegte Einheit";
CM_ SG_ 1527 RW_Sek_Reichweitenverbrauch "Fï?½r sekundï?½re Reichweitenberechnung zugrunde gelegter Verbrauch";
CM_ SG_ 1527 RW_Sekundaer_Reichweite "Reichweite der sekundaeren Antriebsart";
CM_ SG_ 1527 RW_Sekundaer_Reichweite_Anzeige "Reichweite der sekundaeren Antriebsart zur Anzeige im Kombi";
CM_ SG_ 1527 RW_Tendenz "Signalisierung der RW-Tendenz auf Basis der aktuellen Fahrweise. ";
CM_ SG_ 1527 RW_Texte "Signal zum Steuern von reichweitenbezogenen Hinweistexten fï?½r Pop-Up Anzeigen im Kombiinstrument";
CM_ SG_ 2527679676 RW_Prim_rRWB_aktiv "Signalisiert eine aktive Routen basierende Reichweitenberechnung";
CM_ SG_ 2527679676 RW_Prim_rRWB_Reichw_Anz "Routen basierende Reichweite im Fall einer Navi Zielfuehrung";
CM_ SG_ 2527679676 RW_Prim_rRWB_Reichw_Gesamt_Anz "Gesamte Routen basierende Reichweite im Fall einer Navi Zielfuehrung";
CM_ SG_ 2527679676 RW_Prim_rRWB_Reichw_Max_Ges_Anz "Routen basierende gesamte maximal Reichweite im Fall einer Navi Zielfuehrung.\nEinheit ï?½ber RW_Reichweite_Einheit_Anzeige definiert.";
CM_ SG_ 2527679676 RW_Prim_rRWB_Reichw_Rest_E_Anz "Reichweite basierend auf dem Restenergieinhalt am Ziel im Fall einer Navi Zielfuehrung";
CM_ SG_ 2527679676 RW_Prim_statische_Reichw_Anz "Orientierungsreichweite aufgrund eines festen, bzw. geringfuegig adaptierbaren Reichweitenverbrauches";
CM_ SG_ 1610 RKA_FMVSS138_Lampe "Kein Einsatz RKA im D4 Hybrid";
CM_ SG_ 1610 RKA_FMVSS138_MIL "Zentral blinkend fï?½r 1 Minute immer nur gelbe Lampe, dann statisch an. \n\nKein Einsatz RKA im D4 Hybrid";
CM_ SG_ 1610 RKA_Reifentyp "Ausgabe von Reifentyp";
CM_ SG_ 1610 RKA_Warnungen_02 "Ansteuerung der Warnungen (Texte, Tï?½ne, Lampen) im Kombi fï?½r Funktion RKA+\n\nKein Einsatz RKA im D4 Hybrid";
CM_ SG_ 1440 LS_defekt "Fehlererkennung Lichtsensor\n";
CM_ SG_ 1440 LS_Helligkeit_FW "Vorfeldhelligkeit";
CM_ SG_ 1440 LS_Helligkeit_IR "Globalfeldhelligkeit";
CM_ SG_ 1440 LS_Verbau "Verbauinfo Lichtsensor";
CM_ SG_ 1440 RLS_Vorfeldhelligkeit_Boost "erweiterte Helligkeitssensierung fï?½r HUD";
CM_ SG_ 1440 RS_defekt "Fehlererkennung Regensensor";
CM_ SG_ 1440 RS_Regenmenge "Regenmenge";
CM_ SG_ 1440 RS_Schwall "Schwallereignis";
CM_ SG_ 1440 RS_Verbau "Verbauinfo Regensensor";
CM_ SG_ 1440 RS_Verglasung_schliessen "Anforderung: Verglasung schliessen\n";
CM_ SG_ 1440 RS_Wischergeschwindigkeit "Wischergeschwindigkeit (Hï?½be/min)";
CM_ SG_ 1440 SLS_Helligkeit_IR "Helligkeitswert des 'Smart-Light-Sensor' im Dashboard analog / alternativ zu LS_Helligkeit_IR.\n\nEs ist entweder ein RLS_LIN oder ein Smart-LS im FZG verbaut.";
CM_ SG_ 2527679669 LS_Autobahnfahrlicht "Autobahnfahrlicht Anforderung";
CM_ SG_ 2527679669 LS_Dunkel "Regen- / Lichtsensor";
CM_ SG_ 2527679669 LS_Error "Fehler/Defekt Lichtsensorik";
CM_ SG_ 2527679669 LS_Helligkeit_FW "Vorfeldhelligkeit";
CM_ SG_ 2527679669 LS_Helligkeit_IR "Globalfeldhelligkeit";
CM_ SG_ 2527679669 LS_Licht_ein "Anfoderung Fahrlicht";
CM_ SG_ 2527679669 LS_Licht_ein_invers "Inversbit Anforderung Fahrlicht";
CM_ SG_ 2527679669 RLS_02_BZ "4bit Botschaftszï?½hler, wird mit jeder Sendebotschaft inkrementiert";
CM_ SG_ 2527679669 RLS_02_CRC "Fï?½r MLB:\nBerechnung siehe Lastenheft 'Kommunikationsabsicherung fï?½r FlexRay und CAN'\nAb MQB und MLBevo:\nBerechnung siehe Lastenheft 'End-to-End Kommunikationsabsicherung'\n\nEndwerte siehe Begleitdokument 'S-PDU Kennungsfolgen'";
CM_ SG_ 2527679669 RLS_Qualifizierungsbit "Qualifizierungsbit fï?½r die Signale 'LS_Licht_ein' und 'LS_Licht_ein_invers'";
CM_ SG_ 2527679669 RLS_ResponseError "siehe LIN2.0-Specification\n(Darf nicht ï?½ber ein Fehlergueltigkeitsbit abgesichtert werden!)";
CM_ SG_ 2527679669 RLS_Vorfeldhelligkeit_Boost "erweiterte Helligkeitssensierung fï?½r HUD";
CM_ SG_ 2527679669 RS_AdaptierungError "Adaptierungsfehler Regensensor";
CM_ SG_ 2527679669 RS_Error "Fehler/Defekt Regensensorik";
CM_ SG_ 2527679669 RS_Regenfahrlicht "Regenlicht Anforderung";
CM_ SG_ 2527679669 RS_Regenmenge "Regenmenge";
CM_ SG_ 2527679669 RS_Schwall "Schwallereignis";
CM_ SG_ 2527679669 RS_Verglasung_schliessen "Anforderung: Verglasung schliessen\n";
CM_ SG_ 2527679669 RS_versParklage_Wischer "versenkte Parklage Wischer";
CM_ SG_ 2527679669 RS_Wischergeschwindigkeit "Wischergeschwindigkeit (Hï?½be/min)";
CM_ SG_ 2463978697 AFS_Lampe "Status der Fehlerlampe: aktuell anliegender Fehlerzustand des dynamischen oder statischen Kurvenlichtes";
CM_ SG_ 2463978697 BCM2_Bremsl_durch_ECD "Bremslicht (ECD-Bremsung)\n";
CM_ SG_ 2463978697 DLI_Ambex_RefStatus "Status vom DLI an das Exterieur Ambiente";
CM_ SG_ 2463978697 LWR_Lampe "Status der Fehlerlampe: aktuell anliegender Fehlerzustand";
CM_ SG_ 2463978697 LWR_Reisemodus_Texte "Anzeige der eingestellten Verkehrsart bei aktivem Touristenlicht";
CM_ SG_ 2463978697 LWR_SollDC "Sollspannung in [% von UBatt] des linken und rechten Abblendlichtbï?½ndels.";
CM_ SG_ 2463978697 SAL_01_BZ "4bit Botschaftszï?½hler, wird mit jeder Sendebotschaft inkrementiert";
CM_ SG_ 2463978697 SAL_01_CRC "Fï?½r MLB:\nBerechnung siehe Lastenheft 'Kommunikationsabsicherung fï?½r FlexRay und CAN'\nAb MQB und MLBevo:\nBerechnung siehe Lastenheft 'End-to-End Kommunikationsabsicherung'\n\nEndwerte siehe Begleitdokument 'S-PDU Kennungsfolgen'";
CM_ SG_ 2463978697 SAL_Aussenbeleuchtung_defekt "Signal gibt an, ob mindestens ein Leuchtmittel der Auï?½enbeleuchtung defekt ist. Dies wird fï?½r Funktionen benï?½tigt, die bei defekter Auï?½enbeleuchtung nicht starten bzw. abbrechen (z.B. IPA/RPA, Parkhauspilot, etc.)";
CM_ SG_ 2463978697 SAL_Blinkerzyklus_L "Signal wird im MEB benï?½tigt, um dem SAM mitzuteilen, dass eine Blinkfunktion fï?½r die linke Seite aktiv ist.";
CM_ SG_ 2463978697 SAL_Blinkerzyklus_R "Signal wird im MEB benï?½tigt, um dem SAM mitzuteilen, dass eine Blinkfunktion fï?½r die rechte Seite aktiv ist.";
CM_ SG_ 2463978697 SAL_BLK_L_Anf "Blink-Anforderung links an Lichtrouter";
CM_ SG_ 2463978697 SAL_BLK_R_Anf "Anforderung Blinker rechts an Lichtrouter";
CM_ SG_ 2463978697 SAL_Bremszyklus "Das Signal ist aktiv, wenn im Falle einer Notbremsung (Bremslicht-Blinken EA bzw. NBA) das Bremslicht hochfrequenz blinkt.";
CM_ SG_ 2463978697 SAL_BRL_Anf "Bremslicht-Anforderung an Lichtrouter";
CM_ SG_ 2463978697 SAL_CH_Anf "Anforderung CH an Lichtrouter";
CM_ SG_ 2463978697 SAL_HGB_Anf "Anforderung HGB an Lichtrouter";
CM_ SG_ 2463978697 SAL_Kl_15 "Vom Standard Auï?½enlicht generierte Kl15, welche durch das Geschwindigkeitssignal plausibilisiert ist. Hiermit wird sichergestellt, dass das Licht nicht erlischt, wenn die Kl15 aus ist und das FZG trotzdem rollt.";
CM_ SG_ 2463978697 SAL_Kl_15_vFzg "Die Kl-15 Botschaft, erweitert um die Information, ob das Fahrzeug aktive Wegstrecke zurï?½cklegt.";
CM_ SG_ 2463978697 SAL_Kl_15_vFzg_S "Kl_15_vfzg_S fï?½r Sicherheitsanforderung im Auï?½enlicht.";
CM_ SG_ 2463978697 SAL_KL_50 "Klemme 50 nach Plausibilisierung des Startwunsches. Dies wird fï?½r das Auï?½enlicht benï?½tigt.";
CM_ SG_ 2463978697 SAL_KL_50_5s "Kl_50_5s ist die um 5 Sekunden verzï?½gerte Klemme 50.";
CM_ SG_ 2463978697 SAL_Kl_75 "Fï?½r Standard-Auï?½enlicht wird die abgesicherte Kl.75 benï?½tigt. Diese wird um das Geschwindigkeitssignal erweitert.";
CM_ SG_ 2463978697 SAL_KL_75_vFzg "Die um das Geschwindigkeitssignal erweiterte Klemme 75.";
CM_ SG_ 2463978697 SAL_KL_75a "Fï?½r Standard-Auï?½enlicht wird die abgesicherte Kl.75a benï?½tigt. Diese wird um das Geschwindigkeitssignal erweitert.";
CM_ SG_ 2463978697 SAL_KL_75a_vFzg "Die um die Geschwindigkeitsinformation erweiterte Kl75a.";
CM_ SG_ 2463978697 SAL_KZL_Anf "Anforderung Kennzeichenleuchte an Lichtrouter";
CM_ SG_ 2463978697 SAL_LDS_Abblendlicht_Anf "Signal gibt an, ob das Abblendlicht angefordert wird.";
CM_ SG_ 2463978697 SAL_LDS_Assistenzfahrlicht_Anf "Signal gibt an, ob das Assistenzfahrlicht (AUTO) angefordert wird.";
CM_ SG_ 2463978697 SAL_LDS_Nullstellung_Anf "Signal gibt an, ob das Nullstellung vom Lichtdrehschalter angefordert wird.";
CM_ SG_ 2463978697 SAL_LDS_Standlicht_Anf "Signal gibt an, ob das Standlicht angefordert wird.";
CM_ SG_ 2463978697 SAL_LH_Anf "Anforderung LH an Lichtrouter";
CM_ SG_ 2463978697 SAL_NSL_Anf "Anforderung Nebelschlussleuchte an Lichtrouter";
CM_ SG_ 2463978697 SAL_PL_L_Anf "Anforderung Parklicht Links an Lichtrouter.";
CM_ SG_ 2463978697 SAL_PL_R_Anf "Anforderung Parklicht rechts an Lichtrouter";
CM_ SG_ 2463978697 SAL_RFL_Anf "Anforderung Rï?½ckfahrlicht an Lichtrouter";
CM_ SG_ 2463978697 SAL_SL_Anf "Anforderung Standlicht an Lichtrouter.";
CM_ SG_ 2463978697 SAL_WBT_Bel "Beleuchtung Warnblinktaster an SAM";
CM_ SG_ 2463978697 SBBR_SL_AnimDimm_Freigabe "Freigabesignal fï?½r Dimmung und Animation";
CM_ SG_ 517 BCM_Bremsbelag_Sensor_CND "Fahrerinformation Warnfall CND wenn ISO-Symbol (ggf. auch im Display)";
CM_ SG_ 517 BCM_Bremsbelag_Sensor_NAR "Fahrerinformation Warnfall US (sofern keine eigne BRAKE WARE- Symbolik vorhanden und daher die Gesetzeserfï?½llung ï?½ber eine statische BKL-Ansteuerung erfolgen muss.";
CM_ SG_ 517 BCM_Bremsbelag_Sensor_Rdw "Fahrerinformation Warnfall RdW wenn ISO-Symbol (ggf. auch im Display) oder auch fï?½r US, wenn eigene BRAKE WARE- Symbolik vorhanden.";
CM_ SG_ 517 BCM_KiSi_Umschalt_gesperrt "Umschalten der Kindersicherung gesperrt";
CM_ SG_ 517 BCM_Tankklappensteller_Fehler "Fehler: nicht Funktionalitï?½t des Tankklappenstellers";
CM_ SG_ 517 BRL_Bremslicht_Schalter "Einlesen des Bremslicht-Schalters";
CM_ SG_ 517 HD_Hauptraste "SBL-Schloss (MQB/MLBevo): Drehfalle Heckdeckel\nsonst (MQB): Hauptraste Heckdeckel";
CM_ SG_ 517 HD_Vorraste "SBL_Schloss (MQB/MLBevo): Sperrklinke Heckdeckel\nsonst (MQB): Vorraste Heckdeckel";
CM_ SG_ 517 HW_Drehfalle_Tuer_HL "Hardwaresignal der Drehfalle der Tï?½r Hinten Links";
CM_ SG_ 517 HW_Drehfalle_Tuer_HR "Hardwaresignal der Drehfalle der Tï?½r Hinten Rechts";
CM_ SG_ 517 HW_HD_Taste_Innenraum "Hardwaresignal des Heckdeckeltasters im Innenraum";
CM_ SG_ 517 HW_HSB_erkannt "Signal wird verwendet, um den DWA-Master einen Heckscheibenbruch zu signalisieren. Die Qualifizierung erfolgt im Sensorsteuergerï?½t.";
CM_ SG_ 517 HW_MH_Schalter1 "Hardwaresignal des 1. Motorhaubenkontakts";
CM_ SG_ 517 HW_MH_Schalter2 "Hardwaresignal des 2. Motorhaubenkontakts";
CM_ SG_ 517 HW_Softtouch_betaetigt "Hardwaresignal des Softtouchs.";
CM_ SG_ 517 HW_Status_Schloss_gesafet_HL "HW-Signal Schlossstatus gesafet";
CM_ SG_ 517 HW_Status_Schloss_gesafet_HR "HW-Signal Schlossstatus gesafet";
CM_ SG_ 517 HW_Status_Schloss_verriegelt_HL "Hardwaresignal Schlossstatus verriegelt";
CM_ SG_ 517 HW_Status_Schloss_verriegelt_HR "Hardwaresignal Schlossstatus verriegelt";
CM_ SG_ 517 HW_Tankdeckel_offen "Signal zum Erfassen des Status des Tankdeckels.\n\nSignal vom Aktor Steuergerï?½t fï?½r die Auswertung im ZV-Master";
CM_ SG_ 517 HW_Toggle_Taster "HW-Signal des Toggletasters fï?½r ZV";
CM_ SG_ 517 KST_BSW_Fehlermode2 "Signal wird gesetzt, wenn das SAM einen klemmensteuerungs-relevanten Fehler diagnostiziert. Fehler, die das Weiterfahren mit der Anforderung eines zeitnahen Werkstattbesuches erlauben, werden in den Fehlermode 2 eingestuft.";
CM_ SG_ 517 KST_BSW_Klemme_15_HW_Ist "Spiegelung des Klemme 15 Hardware Status auf dem CAN, welcher im MEB durch das SAM gesetzt wird";
CM_ SG_ 517 KST_BSW_Klemmenhochschalten_Sper "Hochschalten der Klemmen im SAM gesperrt";
CM_ SG_ 517 KST_BSW_Not_Taster_betaetigt "Not-Taster betï?½tigt";
CM_ SG_ 517 KST_BSW_ZAT_betaetigt "Zï?½ndanlass-Taster (ZAT) betï?½tigt";
CM_ SG_ 517 SAL_li1_Blinker_Status "Blinker-Statusï?½berwachung des SAM zur Erfï?½llung der funktionalen Sicherheit (Falschblinken, Blinken ohne Anforderung).";
CM_ SG_ 517 SAL_re1_Blinker_Status "Blinker-Statusï?½berwachung des SAM zur Erfï?½llung der funktionalen Sicherheit (Falschblinken, Blinken ohne Anforderung).";
CM_ SG_ 517 SAM_01_BZ "4bit Botschaftszï?½hler, wird mit jeder Sendebotschaft inkrementiert";
CM_ SG_ 517 SAM_01_CRC "Fï?½r MLB:\nBerechnung siehe Lastenheft 'Kommunikationsabsicherung fï?½r FlexRay und CAN'\nAb MQB und MLBevo:\nBerechnung siehe Lastenheft 'End-to-End Kommunikationsabsicherung'\n\nEndwerte siehe Begleitdokument 'S-PDU Kennungsfolgen'";
CM_ SG_ 517 SAM_Fehler_DC_LWR "Fehler im DC-Steller";
CM_ SG_ 517 ZV_Ladeklappe_VerEntriegeln "Ver- u. Entriegeln der Ladeklappe";
CM_ SG_ 517 ZV_LadeklappenStatus "Gibt den Staus der Ladeklappe aus";
CM_ SG_ 1522 KBI_Dimmpoti "Signal wird benï?½tigt fï?½r Dimmung im Audi B8. Der Signalfluss erfolgt vom Kombi an das BCM1.";
CM_ SG_ 1522 KBI_Phototransistor "Signal wird benï?½tigt fï?½r die Dimmung von Such- Funktions- und Displaybeleuchtungen. Der Signalfluss erfolgt vom Steuergerï?½t mit Fotosensor an die jeweiligen Dimmmaster-Steuergerï?½te.\n\nFï?½r Audi B8/Q5 und D4/C7/VW526 vor PA: \n0xFE Phototransistor nicht ve";
BA_DEF_ BO_ "CANFD_BRS" ENUM "0", "1";
BA_DEF_ BO_ "DiagRequest" ENUM "No", "Yes";
BA_DEF_ BO_ "DiagResponse" ENUM "No", "Yes";
BA_DEF_ BO_ "DiagState" ENUM "No", "Yes";
BA_DEF_ BO_ "GenMsgChkConstant" HEX 0 4095;
BA_DEF_ BO_ "GenMsgCycleTime" INT 0 65535;
BA_DEF_ BO_ "GenMsgCycleTimeFast" INT 0 65535;
BA_DEF_ BO_ "GenMsgDelayTime" INT 0 100000;
BA_DEF_ BO_ "GenMsgILSupport" ENUM "No", "Yes";
BA_DEF_ BO_ "GenMsgNrOfRepetition" INT 0 100;
BA_DEF_ BO_ "GenMsgPDUConstants" STRING;
BA_DEF_ BO_ "GenMsgSendType" ENUM "Cyclic", "not_used", "not_used", "not_used", "not_used", "not_used", "not_used", "IfActive", "NoMsgSendType";
BA_DEF_ BO_ "GenMsgStartDelayTime" INT 0 100000;
BA_DEF_ BO_ "MsgType" ENUM "Application", "NM ", "NMH", "TP2.0", "ISO-TP ", "BAP", "EID", "KS", "XCP_PRE_CONFIGURED", "XCP_RUNTIME_CONFIGURED";
BA_DEF_ BO_ "NmMessage" ENUM "No", "Yes";
BA_DEF_ BO_ "NmhMessage" ENUM "No", "Yes";
BA_DEF_ BO_ "VAGTP20_API" HEX 0 255;
BA_DEF_ BO_ "VAGTP20_DynConnection" ENUM "No", "Yes";
BA_DEF_ BO_ "VAGTP20_DynSetup" ENUM "No", "Yes";
BA_DEF_ BO_ "VAGTP20_StatConnection" ENUM "No", "Yes";
BA_DEF_ BO_ "VFrameFormat" ENUM "StandardCAN", "ExtendedCAN", "reserved", "reserved", "reserved", "reserved", "reserved", "reserved", "reserved", "reserved", "reserved", "reserved", "reserved", "reserved", "StandardCAN_FD", "ExtendedCAN_FD";
BA_DEF_ SG_ "Fehlerwert" HEX 0 2147483647;
BA_DEF_ SG_ "GenSigActiveRepetitions" INT -2147483648 2147483647;
BA_DEF_ SG_ "GenSigFuncType" ENUM "NoFunction", "MsgCounter", "CRC-8", "XOR", "XOR-2", "DatedBit", "SW-Kl15", "CHK", "Constant", "Protocol", "CRC-8-SAE_J1850", "CRC-32", "DataLength", "DataID", "MsgCounter16", "SOK-Signatur", "Cluster";
BA_DEF_ SG_ "GenSigInactiveValue" INT -2147483648 2147483647;
BA_DEF_ SG_ "GenSigMissingSourceValue" HEX 0 2147483647;
BA_DEF_ SG_ "GenSigSendType" ENUM "Cyclic", "OnWrite", "OnWriteWithRepetition", "OnChange", "OnChangeWithRepetition", "IfActive", "IfActiveWithRepetition", "NoSigSendType", "OnChangeAndIfActive", "OnChangeAndIfActiveWithRepetition";
BA_DEF_ SG_ "GenSigStartValue" INT -2147483648 2147483647;
BA_DEF_ SG_ "GenSigSwitchedByIgnition" ENUM "No", "Yes";
BA_DEF_ SG_ "NWM-WakeupAllowed" ENUM "No", "Yes";

BA_DEF_REL_ BU_SG_REL_ "GenSigTimeoutTime" INT 0 65535;
BA_DEF_DEF_ "CANFD_BRS" "1";
BA_DEF_DEF_ "DiagRequest" "No";
BA_DEF_DEF_ "DiagResponse" "No";
BA_DEF_DEF_ "DiagState" "No";
BA_DEF_DEF_ "Fehlerwert" 0;
BA_DEF_DEF_ "GenMsgChkConstant" 0;
BA_DEF_DEF_ "GenMsgCycleTime" 0;
BA_DEF_DEF_ "GenMsgCycleTimeFast" 0;
BA_DEF_DEF_ "GenMsgDelayTime" 0;
BA_DEF_DEF_ "GenMsgILSupport" "No";
BA_DEF_DEF_ "GenMsgNrOfRepetition" 0;
BA_DEF_DEF_ "GenMsgPDUConstants" "";
BA_DEF_DEF_ "GenMsgSendType" "NoMsgSendType";
BA_DEF_DEF_ "GenMsgStartDelayTime" 0;
BA_DEF_DEF_ "GenSigActiveRepetitions" 0;
BA_DEF_DEF_ "GenSigFuncType" "NoFunction";
BA_DEF_DEF_ "GenSigInactiveValue" 0;
BA_DEF_DEF_ "GenSigMissingSourceValue" 0;
BA_DEF_DEF_ "GenSigSendType" "NoSigSendType";
BA_DEF_DEF_ "GenSigStartValue" 0;
BA_DEF_DEF_ "GenSigSwitchedByIgnition" "Yes";
BA_DEF_DEF_ "MsgType" "Application";
BA_DEF_DEF_ "NWM-WakeupAllowed" "No";
BA_DEF_DEF_ "NmMessage" "No";
BA_DEF_DEF_ "NmhMessage" "No";
BA_DEF_DEF_ "VAGTP20_API" 0;
BA_DEF_DEF_ "VAGTP20_DynConnection" "No";
BA_DEF_DEF_ "VAGTP20_DynSetup" "No";
BA_DEF_DEF_ "VAGTP20_StatConnection" "No";
BA_DEF_DEF_ "VFrameFormat" "StandardCAN";
BA_DEF_DEF_REL_ "GenSigTimeoutTime" 0;
BA_ "GenMsgCycleTime" BO_ 1175 100;
BA_ "GenMsgDelayTime" BO_ 1175 50;
BA_ "GenMsgILSupport" BO_ 1175 1;
BA_ "GenMsgSendType" BO_ 1175 0;
BA_ "VFrameFormat" BO_ 1175 14;
BA_ "GenMsgCycleTime" BO_ 1355 500;
BA_ "GenMsgDelayTime" BO_ 1355 20;
BA_ "GenMsgILSupport" BO_ 1355 1;
BA_ "GenMsgSendType" BO_ 1355 0;
BA_ "VFrameFormat" BO_ 1355 14;
BA_ "GenMsgCycleTime" BO_ 2527679498 1000;
BA_ "GenMsgCycleTimeFast" BO_ 2527679498 200;
BA_ "GenMsgDelayTime" BO_ 2527679498 50;
BA_ "GenMsgILSupport" BO_ 2527679498 1;
BA_ "GenMsgNrOfRepetition" BO_ 2527679498 3;
BA_ "GenMsgSendType" BO_ 2527679498 0;
BA_ "VFrameFormat" BO_ 2527679498 15;
BA_ "GenMsgCycleTime" BO_ 319 200;
BA_ "GenMsgDelayTime" BO_ 319 20;
BA_ "GenMsgILSupport" BO_ 319 1;
BA_ "GenMsgSendType" BO_ 319 0;
BA_ "VFrameFormat" BO_ 319 14;
BA_ "GenMsgCycleTime" BO_ 1122 150;
BA_ "GenMsgILSupport" BO_ 1122 1;
BA_ "GenMsgSendType" BO_ 1122 0;
BA_ "VFrameFormat" BO_ 1122 14;
BA_ "GenMsgCycleTime" BO_ 1123 150;
BA_ "GenMsgILSupport" BO_ 1123 1;
BA_ "GenMsgSendType" BO_ 1123 0;
BA_ "VFrameFormat" BO_ 1123 14;
BA_ "GenMsgCycleTime" BO_ 1124 150;
BA_ "GenMsgILSupport" BO_ 1124 1;
BA_ "GenMsgSendType" BO_ 1124 0;
BA_ "VFrameFormat" BO_ 1124 14;
BA_ "GenMsgCycleTime" BO_ 1125 450;
BA_ "GenMsgILSupport" BO_ 1125 1;
BA_ "GenMsgSendType" BO_ 1125 0;
BA_ "VFrameFormat" BO_ 1125 14;
BA_ "GenMsgCycleTime" BO_ 1616 1000;
BA_ "GenMsgDelayTime" BO_ 1616 50;
BA_ "GenMsgILSupport" BO_ 1616 1;
BA_ "GenMsgSendType" BO_ 1616 0;
BA_ "VFrameFormat" BO_ 1616 14;
BA_ "GenMsgCycleTime" BO_ 2527679748 200;
BA_ "GenMsgILSupport" BO_ 2527679748 1;
BA_ "GenMsgSendType" BO_ 2527679748 0;
BA_ "VFrameFormat" BO_ 2527679748 15;
BA_ "GenMsgCycleTime" BO_ 2463978734 100;
BA_ "GenMsgDelayTime" BO_ 2463978734 50;
BA_ "GenMsgILSupport" BO_ 2463978734 1;
BA_ "GenMsgSendType" BO_ 2463978734 0;
BA_ "VFrameFormat" BO_ 2463978734 15;
BA_ "GenMsgCycleTime" BO_ 2527679742 100;
BA_ "GenMsgILSupport" BO_ 2527679742 1;
BA_ "GenMsgSendType" BO_ 2527679742 0;
BA_ "VFrameFormat" BO_ 2527679742 15;
BA_ "GenMsgCycleTime" BO_ 1525 1000;
BA_ "GenMsgILSupport" BO_ 1525 1;
BA_ "GenMsgSendType" BO_ 1525 0;
BA_ "VFrameFormat" BO_ 1525 14;
BA_ "GenMsgCycleTime" BO_ 1527 1000;
BA_ "GenMsgDelayTime" BO_ 1527 100;
BA_ "GenMsgILSupport" BO_ 1527 1;
BA_ "GenMsgSendType" BO_ 1527 0;
BA_ "VFrameFormat" BO_ 1527 14;
BA_ "GenMsgCycleTime" BO_ 2527679676 500;
BA_ "GenMsgILSupport" BO_ 2527679676 1;
BA_ "GenMsgSendType" BO_ 2527679676 0;
BA_ "VFrameFormat" BO_ 2527679676 15;
BA_ "GenMsgCycleTime" BO_ 1610 500;
BA_ "GenMsgILSupport" BO_ 1610 1;
BA_ "GenMsgSendType" BO_ 1610 0;
BA_ "VFrameFormat" BO_ 1610 14;
BA_ "GenMsgCycleTime" BO_ 1440 200;
BA_ "GenMsgILSupport" BO_ 1440 1;
BA_ "GenMsgSendType" BO_ 1440 0;
BA_ "VFrameFormat" BO_ 1440 14;
BA_ "GenMsgCycleTime" BO_ 2527679669 80;
BA_ "GenMsgILSupport" BO_ 2527679669 1;
BA_ "GenMsgPDUConstants" BO_ 2527679669 "0x2c,0x57,0x41,0xc4,0x6c,0xd9,0x38,0x4d,0x73,0x8f,0x70,0xb3,0xd1,0x96,0xc9,0xc6";
BA_ "GenMsgSendType" BO_ 2527679669 0;
BA_ "VFrameFormat" BO_ 2527679669 15;
BA_ "GenMsgCycleTime" BO_ 2463978697 80;
BA_ "GenMsgCycleTimeFast" BO_ 2463978697 50;
BA_ "GenMsgDelayTime" BO_ 2463978697 10;
BA_ "GenMsgILSupport" BO_ 2463978697 1;
BA_ "GenMsgNrOfRepetition" BO_ 2463978697 5;
BA_ "GenMsgPDUConstants" BO_ 2463978697 "0xde,0xa9,0x83,0x0b,0x0c,0x64,0x79,0x44,0x0f,0xf6,0xc6,0xc7,0x05,0x45,0xb7,0x59";
BA_ "GenMsgSendType" BO_ 2463978697 0;
BA_ "VFrameFormat" BO_ 2463978697 15;
BA_ "GenMsgCycleTime" BO_ 517 200;
BA_ "GenMsgCycleTimeFast" BO_ 517 20;
BA_ "GenMsgDelayTime" BO_ 517 10;
BA_ "GenMsgPDUConstants" BO_ 517 "0x19,0x36,0xd4,0x1e,0x80,0x22,0xf4,0xb8,0xad,0x41,0x0b,0x3f,0x87,0x42,0x25,0x40";
BA_ "GenMsgSendType" BO_ 517 0;
BA_ "VFrameFormat" BO_ 517 14;
BA_ "GenMsgCycleTime" BO_ 1522 200;
BA_ "GenMsgDelayTime" BO_ 1522 50;
BA_ "GenMsgILSupport" BO_ 1522 1;
BA_ "GenMsgSendType" BO_ 1522 0;
BA_ "VFrameFormat" BO_ 1522 14;
BA_ "GenSigSendType" SG_ 1175 PDC_Tonausgabe_Front 3;
BA_ "GenSigSendType" SG_ 1175 PDC_Tonausgabe_Heck 3;
BA_ "GenSigSendType" SG_ 1175 PH_Abschaltursache 3;
BA_ "GenSigSendType" SG_ 1175 PH_Anf_Audioabsenkung 3;
BA_ "GenSigSendType" SG_ 1175 PH_Anf_Verdeck 3;
BA_ "GenSigSendType" SG_ 1175 PH_defekt 3;
BA_ "GenSigSendType" SG_ 1175 PH_Display_Kundenwunsch 3;
BA_ "GenSigSendType" SG_ 1175 PH_Frequenz_hinten 3;
BA_ "GenSigSendType" SG_ 1175 PH_Frequenz_vorn 3;
BA_ "GenSigSendType" SG_ 1175 PH_gestoert 3;
BA_ "GenSigSendType" SG_ 1175 PH_Lautstaerke_hinten 3;
BA_ "GenSigSendType" SG_ 1175 PH_Lautstaerke_vorn 3;
BA_ "GenSigSendType" SG_ 1175 PH_nachtr_Stopp_Anf 3;
BA_ "GenSigSendType" SG_ 1175 PH_Opt_Anz_H_Hindernis 3;
BA_ "GenSigSendType" SG_ 1175 PH_Opt_Anz_V_Hindernis 3;
BA_ "GenSigSendType" SG_ 1175 PH_Opt_Anzeige_H_ein 3;
BA_ "GenSigSendType" SG_ 1175 PH_Opt_Anzeige_V_ein 3;
BA_ "GenSigSendType" SG_ 1175 PH_StartStopp_Info 3;
BA_ "GenSigSendType" SG_ 1175 PH_Stoermeldung 3;
BA_ "GenSigSendType" SG_ 1175 PH_Systemzustand 3;
BA_ "Fehlerwert" SG_ 1175 PH_Taster 3;
BA_ "GenSigSendType" SG_ 1175 PH_Taster 3;
BA_ "GenSigSendType" SG_ 1175 PH_Tongeber_H_aktiv 3;
BA_ "GenSigSendType" SG_ 1175 PH_Tongeber_H_verfuegbar 3;
BA_ "GenSigSendType" SG_ 1175 PH_Tongeber_mute 3;
BA_ "GenSigSendType" SG_ 1175 PH_Tongeber_V_aktiv 3;
BA_ "Fehlerwert" SG_ 1175 PH_Visualisierung 7;
BA_ "GenSigSendType" SG_ 1175 PH_Visualisierung 3;
BA_ "GenSigStartValue" SG_ 1175 PH_Visualisierung 6;
BA_ "GenSigSendType" SG_ 1175 PLA_Anf_Aufschaltung_RVC 3;
BA_ "GenSigSendType" SG_ 1355 APS_PaCo_WarningTones 3;
BA_ "GenSigSwitchedByIgnition" SG_ 1355 APS_PaCo_WarningTones 0;
BA_ "GenSigSendType" SG_ 1355 APSOPS_PaCo_ApproachingFront 3;
BA_ "GenSigSwitchedByIgnition" SG_ 1355 APSOPS_PaCo_ApproachingFront 0;
BA_ "GenSigSendType" SG_ 1355 APSOPS_PaCo_ApproachingRear 3;
BA_ "GenSigSwitchedByIgnition" SG_ 1355 APSOPS_PaCo_ApproachingRear 0;
BA_ "GenSigSendType" SG_ 1355 APSOPS_PaCo_Button 3;
BA_ "GenSigSwitchedByIgnition" SG_ 1355 APSOPS_PaCo_Button 0;
BA_ "GenSigSendType" SG_ 1355 APSOPS_PaCo_FunctionState 3;
BA_ "GenSigSwitchedByIgnition" SG_ 1355 APSOPS_PaCo_FunctionState 0;
BA_ "Fehlerwert" SG_ 1355 APSOPS_PaCo_MainState 7;
BA_ "GenSigSendType" SG_ 1355 APSOPS_PaCo_MainState 3;
BA_ "GenSigSwitchedByIgnition" SG_ 1355 APSOPS_PaCo_MainState 0;
BA_ "GenSigSendType" SG_ 1355 APSOPS_PaCo_ObstacleDetectFront 3;
BA_ "GenSigSwitchedByIgnition" SG_ 1355 APSOPS_PaCo_ObstacleDetectFront 0;
BA_ "GenSigSendType" SG_ 1355 APSOPS_PaCo_ObstacleDetectRear 3;
BA_ "GenSigSwitchedByIgnition" SG_ 1355 APSOPS_PaCo_ObstacleDetectRear 0;
BA_ "GenSigSendType" SG_ 1355 PH_Aufschaltursache 3;
BA_ "Fehlerwert" SG_ 1355 PH_Ton_Ausgabe 7;
BA_ "GenSigSendType" SG_ 1355 PH_Ton_Ausgabe 3;
BA_ "GenSigSendType" SG_ 1355 PH_Ton_Lautstaerke 3;
BA_ "Fehlerwert" SG_ 1355 PH_Ton_Pausenlaenge 127;
BA_ "GenSigSendType" SG_ 1355 PH_Ton_Pausenlaenge 3;
BA_ "GenSigSendType" SG_ 1355 PH_Ton_Richtung 3;
BA_ "GenSigSendType" SG_ 1355 PH_Verschmutzungsmeldung 3;
BA_ "GenSigSendType" SG_ 1355 PH_WAH_Meldung 3;
BA_ "GenSigSendType" SG_ 1355 RBF_Anf_Meldungen 3;
BA_ "GenSigSendType" SG_ 1355 RBF_PaCo_Anf_Meldungen 0;
BA_ "GenSigSendType" SG_ 1355 RBFMA_PaCo_BrakeIntervention 3;
BA_ "GenSigSwitchedByIgnition" SG_ 1355 RBFMA_PaCo_BrakeIntervention 0;
BA_ "Fehlerwert" SG_ 1355 RBFMA_PaCo_MainState 7;
BA_ "GenSigSendType" SG_ 1355 RBFMA_PaCo_MainState 3;
BA_ "GenSigSwitchedByIgnition" SG_ 1355 RBFMA_PaCo_MainState 0;
BA_ "GenSigSendType" SG_ 2527679498 IAA_Active_User_ID 4;
BA_ "GenSigSwitchedByIgnition" SG_ 2527679498 IAA_Active_User_ID 0;
BA_ "GenSigSendType" SG_ 2527679498 IAA_Identified_User_ID 4;
BA_ "GenSigSwitchedByIgnition" SG_ 2527679498 IAA_Identified_User_ID 0;
BA_ "GenSigSendType" SG_ 2527679498 IAA_PSO_wake_up 4;
BA_ "GenSigSwitchedByIgnition" SG_ 2527679498 IAA_PSO_wake_up 0;
BA_ "GenSigSendType" SG_ 2527679498 Perso_Aktiv 4;
BA_ "GenSigSwitchedByIgnition" SG_ 2527679498 Perso_Aktiv 0;
BA_ "GenSigSendType" SG_ 2527679498 Perso_Bedienstelle 4;
BA_ "GenSigSwitchedByIgnition" SG_ 2527679498 Perso_Bedienstelle 0;
BA_ "GenSigSendType" SG_ 2527679498 Perso_Fahrernummer 4;
BA_ "GenSigSwitchedByIgnition" SG_ 2527679498 Perso_Fahrernummer 0;
BA_ "GenSigSendType" SG_ 2527679498 Perso_Freigabe_Verstellung 4;
BA_ "GenSigSwitchedByIgnition" SG_ 2527679498 Perso_Freigabe_Verstellung 0;
BA_ "GenSigSendType" SG_ 2527679498 Perso_Kontonummer 4;
BA_ "GenSigSwitchedByIgnition" SG_ 2527679498 Perso_Kontonummer 0;
BA_ "GenSigSendType" SG_ 2527679498 Perso_Schreibschutz 4;
BA_ "GenSigSwitchedByIgnition" SG_ 2527679498 Perso_Schreibschutz 0;
BA_ "GenSigSendType" SG_ 2527679498 Perso_Status 1;
BA_ "GenSigSwitchedByIgnition" SG_ 2527679498 Perso_Status 0;
BA_ "GenSigSendType" SG_ 2527679498 Perso_Steuerung 4;
BA_ "GenSigSwitchedByIgnition" SG_ 2527679498 Perso_Steuerung 0;
BA_ "GenSigSendType" SG_ 2527679498 Perso_Steuerungsparameter 4;
BA_ "GenSigSwitchedByIgnition" SG_ 2527679498 Perso_Steuerungsparameter 0;
BA_ "GenSigSendType" SG_ 319 PreCrash_Anforderung_AFR 3;
BA_ "GenSigStartValue" SG_ 319 PreCrash_Anforderung_AFR 7;
BA_ "GenSigSwitchedByIgnition" SG_ 319 PreCrash_Anforderung_AFR 0;
BA_ "GenSigSendType" SG_ 319 PreCrash_BFS_KSV_verfahren 3;
BA_ "GenSigSwitchedByIgnition" SG_ 319 PreCrash_BFS_KSV_verfahren 0;
BA_ "GenSigSendType" SG_ 319 PreCrash_BFS_Laengsverstellung 3;
BA_ "GenSigSwitchedByIgnition" SG_ 319 PreCrash_BFS_Laengsverstellung 0;
BA_ "GenSigSendType" SG_ 319 PreCrash_BFS_Pneumatik_ansteuern 3;
BA_ "GenSigSwitchedByIgnition" SG_ 319 PreCrash_BFS_Pneumatik_ansteuern 0;
BA_ "GenSigSendType" SG_ 319 PreCrash_BFS_Sitzlehne_verfahren 3;
BA_ "GenSigSwitchedByIgnition" SG_ 319 PreCrash_BFS_Sitzlehne_verfahren 0;
BA_ "GenSigSendType" SG_ 319 PreCrash_Blinken 3;
BA_ "GenSigSendType" SG_ 319 PreCrash_Charisma_FahrPr 0;
BA_ "GenSigSendType" SG_ 319 PreCrash_Charisma_Status 0;
BA_ "GenSigSendType" SG_ 319 PreCrash_Fenster_schliessen 3;
BA_ "GenSigSendType" SG_ 319 PreCrash_Fo_KSV_verfahren 3;
BA_ "GenSigSwitchedByIgnition" SG_ 319 PreCrash_Fo_KSV_verfahren 0;
BA_ "GenSigSendType" SG_ 319 PreCrash_Fo_Pneumatik_ansteuern 3;
BA_ "GenSigSwitchedByIgnition" SG_ 319 PreCrash_Fo_Pneumatik_ansteuern 0;
BA_ "GenSigSendType" SG_ 319 PreCrash_Fo_Sitzlehne_verfahren 3;
BA_ "GenSigSwitchedByIgnition" SG_ 319 PreCrash_Fo_Sitzlehne_verfahren 0;
BA_ "GenSigSendType" SG_ 319 PreCrash_FS_KSV_verfahren 3;
BA_ "GenSigSwitchedByIgnition" SG_ 319 PreCrash_FS_KSV_verfahren 0;
BA_ "GenSigSendType" SG_ 319 PreCrash_FS_Laengsverstellung 3;
BA_ "GenSigSwitchedByIgnition" SG_ 319 PreCrash_FS_Laengsverstellung 0;
BA_ "GenSigSendType" SG_ 319 PreCrash_FS_Pneumatik_ansteuern 3;
BA_ "GenSigSwitchedByIgnition" SG_ 319 PreCrash_FS_Pneumatik_ansteuern 0;
BA_ "GenSigSendType" SG_ 319 PreCrash_FS_Sitzlehne_verfahren 3;
BA_ "GenSigSwitchedByIgnition" SG_ 319 PreCrash_FS_Sitzlehne_verfahren 0;
BA_ "GenSigSendType" SG_ 319 PreCrash_Schiebedach_schliessen 3;
BA_ "GenSigSendType" SG_ 319 PreCrash_Tueren_Verriegeln 3;
BA_ "GenSigSwitchedByIgnition" SG_ 319 PreCrash_Tueren_Verriegeln 0;
BA_ "GenSigSendType" SG_ 319 SC_PreCrash_LED 3;
BA_ "GenSigSwitchedByIgnition" SG_ 319 SC_PreCrash_LED 0;
BA_ "GenSigSendType" SG_ 319 SC_PreCrash_Texte 3;
BA_ "GenSigSwitchedByIgnition" SG_ 319 SC_PreCrash_Texte 0;
BA_ "GenSigSendType" SG_ 319 SC_PreCrash_Warnung 3;
BA_ "GenSigSwitchedByIgnition" SG_ 319 SC_PreCrash_Warnung 0;
BA_ "GenSigSendType" SG_ 319 SC_PreSense_FCWP 3;
BA_ "GenSigSwitchedByIgnition" SG_ 319 SC_PreSense_FCWP 0;
BA_ "GenSigSendType" SG_ 1122 PSD_Abzweigerichtung 0;
BA_ "GenSigSwitchedByIgnition" SG_ 1122 PSD_Abzweigerichtung 0;
BA_ "GenSigSendType" SG_ 1122 PSD_Abzweigewinkel 0;
BA_ "GenSigSwitchedByIgnition" SG_ 1122 PSD_Abzweigewinkel 0;
BA_ "GenSigSendType" SG_ 1122 PSD_ADAS_Qualitaet 0;
BA_ "GenSigSendType" SG_ 1122 PSD_Anfangskruemmung 0;
BA_ "GenSigSwitchedByIgnition" SG_ 1122 PSD_Anfangskruemmung 0;
BA_ "GenSigSendType" SG_ 1122 PSD_Anfangskruemmung_Vorz 0;
BA_ "GenSigSwitchedByIgnition" SG_ 1122 PSD_Anfangskruemmung_Vorz 0;
BA_ "GenSigSendType" SG_ 1122 PSD_Bebauung 0;
BA_ "GenSigSendType" SG_ 1122 PSD_Endkruemmung 0;
BA_ "GenSigSendType" SG_ 1122 PSD_Endkruemmung_Vorz 0;
BA_ "GenSigSendType" SG_ 1122 PSD_Fahrspuren_Anzahl 0;
BA_ "GenSigStartValue" SG_ 1122 PSD_Fahrspuren_Anzahl 1;
BA_ "GenSigSwitchedByIgnition" SG_ 1122 PSD_Fahrspuren_Anzahl 0;
BA_ "GenSigSendType" SG_ 1122 PSD_Geradester_Pfad 0;
BA_ "Fehlerwert" SG_ 1122 PSD_Idenditaets_ID 1;
BA_ "GenSigSendType" SG_ 1122 PSD_Idenditaets_ID 0;
BA_ "GenSigSendType" SG_ 1122 PSD_Rampe 0;
BA_ "GenSigSendType" SG_ 1122 PSD_Segment_ID 0;
BA_ "GenSigSendType" SG_ 1122 PSD_Segment_Komplett 0;
BA_ "GenSigSwitchedByIgnition" SG_ 1122 PSD_Segment_Komplett 0;
BA_ "GenSigSendType" SG_ 1122 PSD_Segmentlaenge 0;
BA_ "GenSigSendType" SG_ 1122 PSD_Strassenkategorie 0;
BA_ "GenSigStartValue" SG_ 1122 PSD_Strassenkategorie 7;
BA_ "GenSigSwitchedByIgnition" SG_ 1122 PSD_Strassenkategorie 0;
BA_ "GenSigSendType" SG_ 1122 PSD_Vorgaenger_Segment_ID 0;
BA_ "GenSigSendType" SG_ 1122 PSD_wahrscheinlichster_Pfad 0;
BA_ "GenSigSendType" SG_ 1123 PSD_Attribut_1_ID 0;
BA_ "GenSigSendType" SG_ 1123 PSD_Attribut_1_Offset 0;
BA_ "GenSigSendType" SG_ 1123 PSD_Attribut_1_Wert 0;
BA_ "GenSigSendType" SG_ 1123 PSD_Attribut_2_ID 0;
BA_ "GenSigSendType" SG_ 1123 PSD_Attribut_2_Offset 0;
BA_ "GenSigSendType" SG_ 1123 PSD_Attribut_2_Wert 0;
BA_ "Fehlerwert" SG_ 1123 PSD_Attribut_Segment_ID_05 1;
BA_ "GenSigSendType" SG_ 1123 PSD_Attribut_Segment_ID_05 0;
BA_ "GenSigSendType" SG_ 1123 PSD_Attribute_Komplett_05 0;
BA_ "GenSigSendType" SG_ 1123 PSD_Pos_Fahrspur 0;
BA_ "GenSigSendType" SG_ 1123 PSD_Pos_Fehler_Laengsrichtung 0;
BA_ "GenSigSendType" SG_ 1123 PSD_Pos_Inhibitzeit 0;
BA_ "GenSigSendType" SG_ 1123 PSD_Pos_Segment_ID 0;
BA_ "GenSigSendType" SG_ 1123 PSD_Pos_Segmentlaenge 0;
BA_ "GenSigSendType" SG_ 1123 PSD_Pos_Standort_Eindeutig 0;
BA_ "GenSigSwitchedByIgnition" SG_ 1123 PSD_Pos_Standort_Eindeutig 0;
BA_ "GenSigSendType" SG_ 1124 PSD_06_Mux 0;
BA_ "GenSigSwitchedByIgnition" SG_ 1124 PSD_06_Mux 0;
BA_ "NWM-WakeupAllowed" SG_ 1124 PSD_06_Mux 1;
BA_ "Fehlerwert" SG_ 1124 PSD_Attribut_Segment_ID 1;
BA_ "GenSigSwitchedByIgnition" SG_ 1124 PSD_Attribute_Komplett_06 0;
BA_ "GenSigStartValue" SG_ 1124 PSD_Ges_Typ 3;
BA_ "GenSigSwitchedByIgnition" SG_ 1124 PSD_Ges_Typ 0;
BA_ "GenSigSwitchedByIgnition" SG_ 1124 PSD_Steigung_1_Attribute_kompl 0;
BA_ "Fehlerwert" SG_ 1124 PSD_Steigung_1_Segment_ID 1;
BA_ "GenSigSwitchedByIgnition" SG_ 1124 PSD_Steigung_2_Attribute_kompl 0;
BA_ "Fehlerwert" SG_ 1124 PSD_Steigung_2_Segment_ID 1;
BA_ "GenSigSendType" SG_ 1125 PSD_LR_01_MUX 0;
BA_ "GenSigSendType" SG_ 1125 PSD_LR_Profil_Nummer 0;
BA_ "GenSigSwitchedByIgnition" SG_ 1125 PSD_LR_Steigung_3_Vorz 0;
BA_ "GenSigSendType" SG_ 1616 PRIV_dataextraction_CDIS 0;
BA_ "GenSigSwitchedByIgnition" SG_ 1616 PRIV_dataextraction_CDIS 0;
BA_ "GenSigSendType" SG_ 1616 RA_AM_Tuning 3;
BA_ "GenSigSwitchedByIgnition" SG_ 1616 RA_AM_Tuning 0;
BA_ "GenSigSendType" SG_ 1616 RA_Frequency 3;
BA_ "GenSigSwitchedByIgnition" SG_ 1616 RA_Frequency 0;
BA_ "GenSigSendType" SG_ 1616 RA_Frequency_unit 3;
BA_ "GenSigSwitchedByIgnition" SG_ 1616 RA_Frequency_unit 0;
BA_ "GenSigSendType" SG_ 1616 RA_PowerAmpOn 3;
BA_ "GenSigSwitchedByIgnition" SG_ 1616 RA_PowerAmpOn 0;
BA_ "GenSigSendType" SG_ 1616 RA_Radio_Error_Flag 3;
BA_ "GenSigSwitchedByIgnition" SG_ 1616 RA_Radio_Error_Flag 0;
BA_ "GenSigSendType" SG_ 1616 RA_Radio_mute 3;
BA_ "GenSigSwitchedByIgnition" SG_ 1616 RA_Radio_mute 0;
BA_ "GenSigSendType" SG_ 1616 RA_Radio_on 3;
BA_ "GenSigSwitchedByIgnition" SG_ 1616 RA_Radio_on 0;
BA_ "GenSigSendType" SG_ 1616 RA_Radio_Surround 3;
BA_ "GenSigSwitchedByIgnition" SG_ 1616 RA_Radio_Surround 0;
BA_ "GenSigSendType" SG_ 1616 RA_VNC_OFF 3;
BA_ "GenSigSwitchedByIgnition" SG_ 1616 RA_VNC_OFF 0;
BA_ "GenSigSendType" SG_ 2527679748 TPMS_CalTyp 0;
BA_ "GenSigSendType" SG_ 2527679748 TPMS_disable 0;
BA_ "GenSigSendType" SG_ 2527679748 TPMS_enable 0;
BA_ "Fehlerwert" SG_ 2527679748 TPMS_LearningState 8;
BA_ "GenSigSendType" SG_ 2527679748 TPMS_LearningState 0;
BA_ "GenSigSendType" SG_ 2527679748 TPMS_PDeFrLe 0;
BA_ "GenSigSendType" SG_ 2527679748 TPMS_PDeFrRi 0;
BA_ "GenSigSendType" SG_ 2527679748 TPMS_PDeReLe 0;
BA_ "GenSigSendType" SG_ 2527679748 TPMS_PDeReRi 0;
BA_ "GenSigSendType" SG_ 2527679748 TPMS_RaceTrckMdSts 0;
BA_ "Fehlerwert" SG_ 2527679748 TPMS_SensBattStsFrLe 127;
BA_ "GenSigSendType" SG_ 2527679748 TPMS_SensBattStsFrLe 0;
BA_ "GenSigStartValue" SG_ 2527679748 TPMS_SensBattStsFrLe 126;
BA_ "Fehlerwert" SG_ 2527679748 TPMS_SensBattStsFrRi 127;
BA_ "GenSigSendType" SG_ 2527679748 TPMS_SensBattStsFrRi 0;
BA_ "GenSigStartValue" SG_ 2527679748 TPMS_SensBattStsFrRi 126;
BA_ "Fehlerwert" SG_ 2527679748 TPMS_SensBattStsReLe 127;
BA_ "GenSigSendType" SG_ 2527679748 TPMS_SensBattStsReLe 0;
BA_ "GenSigStartValue" SG_ 2527679748 TPMS_SensBattStsReLe 126;
BA_ "Fehlerwert" SG_ 2527679748 TPMS_SensBattStsReRi 127;
BA_ "GenSigSendType" SG_ 2527679748 TPMS_SensBattStsReRi 0;
BA_ "GenSigStartValue" SG_ 2527679748 TPMS_SensBattStsReRi 126;
BA_ "GenSigSendType" SG_ 2527679748 TPMS_SensPFrLe 0;
BA_ "GenSigStartValue" SG_ 2527679748 TPMS_SensPFrLe 63;
BA_ "GenSigSendType" SG_ 2527679748 TPMS_SensPFrRi 0;
BA_ "GenSigStartValue" SG_ 2527679748 TPMS_SensPFrRi 63;
BA_ "GenSigSendType" SG_ 2527679748 TPMS_SensPReLe 0;
BA_ "GenSigStartValue" SG_ 2527679748 TPMS_SensPReLe 63;
BA_ "GenSigSendType" SG_ 2527679748 TPMS_SensPReRi 0;
BA_ "GenSigStartValue" SG_ 2527679748 TPMS_SensPReRi 63;
BA_ "Fehlerwert" SG_ 2527679748 TPMS_SensSigAgeFrLe 15;
BA_ "GenSigSendType" SG_ 2527679748 TPMS_SensSigAgeFrLe 0;
BA_ "GenSigStartValue" SG_ 2527679748 TPMS_SensSigAgeFrLe 14;
BA_ "Fehlerwert" SG_ 2527679748 TPMS_SensSigAgeFrRi 15;
BA_ "GenSigSendType" SG_ 2527679748 TPMS_SensSigAgeFrRi 0;
BA_ "GenSigStartValue" SG_ 2527679748 TPMS_SensSigAgeFrRi 14;
BA_ "Fehlerwert" SG_ 2527679748 TPMS_SensSigAgeReLe 15;
BA_ "GenSigSendType" SG_ 2527679748 TPMS_SensSigAgeReLe 0;
BA_ "GenSigStartValue" SG_ 2527679748 TPMS_SensSigAgeReLe 14;
BA_ "Fehlerwert" SG_ 2527679748 TPMS_SensSigAgeReRi 15;
BA_ "GenSigSendType" SG_ 2527679748 TPMS_SensSigAgeReRi 0;
BA_ "GenSigStartValue" SG_ 2527679748 TPMS_SensSigAgeReRi 14;
BA_ "GenSigSendType" SG_ 2527679748 TPMS_SensStsFrLe 0;
BA_ "GenSigSendType" SG_ 2527679748 TPMS_SensStsFrRi 0;
BA_ "GenSigSendType" SG_ 2527679748 TPMS_SensStsReLe 0;
BA_ "GenSigSendType" SG_ 2527679748 TPMS_SensStsReRi 0;
BA_ "Fehlerwert" SG_ 2527679748 TPMS_SensTFrLe 255;
BA_ "GenSigSendType" SG_ 2527679748 TPMS_SensTFrLe 0;
BA_ "GenSigStartValue" SG_ 2527679748 TPMS_SensTFrLe 254;
BA_ "Fehlerwert" SG_ 2527679748 TPMS_SensTFrRi 255;
BA_ "GenSigSendType" SG_ 2527679748 TPMS_SensTFrRi 0;
BA_ "GenSigStartValue" SG_ 2527679748 TPMS_SensTFrRi 254;
BA_ "Fehlerwert" SG_ 2527679748 TPMS_SensTReLe 255;
BA_ "GenSigSendType" SG_ 2527679748 TPMS_SensTReLe 0;
BA_ "GenSigStartValue" SG_ 2527679748 TPMS_SensTReLe 254;
BA_ "Fehlerwert" SG_ 2527679748 TPMS_SensTReRi 255;
BA_ "GenSigSendType" SG_ 2527679748 TPMS_SensTReRi 0;
BA_ "GenSigStartValue" SG_ 2527679748 TPMS_SensTReRi 254;
BA_ "GenSigSendType" SG_ 2527679748 TPMS_SensTypFrLe 0;
BA_ "GenSigSendType" SG_ 2527679748 TPMS_SensTypFrRi 0;
BA_ "GenSigSendType" SG_ 2527679748 TPMS_SensTypReLe 0;
BA_ "GenSigSendType" SG_ 2527679748 TPMS_SensTypReRi 0;
BA_ "GenSigSendType" SG_ 2527679748 TPMS_TarPTmpDepFrLe 0;
BA_ "GenSigSwitchedByIgnition" SG_ 2527679748 TPMS_TarPTmpDepFrLe 0;
BA_ "GenSigSendType" SG_ 2527679748 TPMS_TarPTmpDepFrRi 0;
BA_ "GenSigSwitchedByIgnition" SG_ 2527679748 TPMS_TarPTmpDepFrRi 0;
BA_ "GenSigSendType" SG_ 2527679748 TPMS_TarPTmpDepReLe 0;
BA_ "GenSigSwitchedByIgnition" SG_ 2527679748 TPMS_TarPTmpDepReLe 0;
BA_ "GenSigSendType" SG_ 2527679748 TPMS_TarPTmpDepReRi 0;
BA_ "GenSigSwitchedByIgnition" SG_ 2527679748 TPMS_TarPTmpDepReRi 0;
BA_ "GenSigSendType" SG_ 2527679748 TPMS_Warn1 0;
BA_ "GenSigSendType" SG_ 2527679748 TPMS_Warn1TireFrLe 0;
BA_ "GenSigSendType" SG_ 2527679748 TPMS_Warn1TireFrRi 0;
BA_ "GenSigSendType" SG_ 2527679748 TPMS_Warn1TireReLe 0;
BA_ "GenSigSendType" SG_ 2527679748 TPMS_Warn1TireReRi 0;
BA_ "GenSigSendType" SG_ 2527679748 TPMS_Warn2 0;
BA_ "GenSigSendType" SG_ 2527679748 TPMS_Warn2TireFrLe 0;
BA_ "GenSigSendType" SG_ 2527679748 TPMS_Warn2TireFrRi 0;
BA_ "GenSigSendType" SG_ 2527679748 TPMS_Warn2TireReLe 0;
BA_ "GenSigSendType" SG_ 2527679748 TPMS_Warn2TireReRi 0;
BA_ "GenSigSendType" SG_ 2527679748 TPMS_Warn3 0;
BA_ "GenSigSendType" SG_ 2527679748 TPMS_Warn3TireFrLe 0;
BA_ "GenSigSendType" SG_ 2527679748 TPMS_Warn3TireFrRi 0;
BA_ "GenSigSendType" SG_ 2527679748 TPMS_Warn3TireReLe 0;
BA_ "GenSigSendType" SG_ 2527679748 TPMS_Warn3TireReRi 0;
BA_ "GenSigSendType" SG_ 2527679748 TPMS_Warn4 0;
BA_ "GenSigSendType" SG_ 2527679748 TPMS_Warn4TireFrLe 0;
BA_ "GenSigSendType" SG_ 2527679748 TPMS_Warn4TireFrRi 0;
BA_ "GenSigSendType" SG_ 2527679748 TPMS_Warn4TireReLe 0;
BA_ "GenSigSendType" SG_ 2527679748 TPMS_Warn4TireReRi 0;
BA_ "GenSigSendType" SG_ 2527679748 TPMS_WarnAcoCalOk 0;
BA_ "GenSigSendType" SG_ 2527679748 TPMS_WarnCalOk 0;
BA_ "GenSigSendType" SG_ 2527679748 TPMS_WarnCmftP 0;
BA_ "GenSigSendType" SG_ 2527679748 TPMS_WarnFltIdc 0;
BA_ "GenSigSendType" SG_ 2527679748 TPMS_WarnFr 0;
BA_ "GenSigSendType" SG_ 2527679748 TPMS_WarnLmpStMil 0;
BA_ "GenSigSendType" SG_ 2527679748 TPMS_WarnLmpStP 0;
BA_ "GenSigSendType" SG_ 2527679748 TPMS_WarnMaxV 0;
BA_ "GenSigSendType" SG_ 2527679748 TPMS_WarnRaceTrckMdMinP 0;
BA_ "GenSigSendType" SG_ 2527679748 TPMS_WarnRe 0;
BA_ "GenSigSendType" SG_ 2527679748 TPMS_WarnSysLrn 0;
BA_ "GenSigSendType" SG_ 2527679748 TPMS_WarnTmpFlt 0;
BA_ "GenSigSendType" SG_ 2527679748 TPMS_WarnWhlChgDet 0;
BA_ "GenSigSendType" SG_ 2527679748 TPMS_WhlChgDetFrLe 0;
BA_ "GenSigSendType" SG_ 2527679748 TPMS_WhlChgDetFrRi 0;
BA_ "GenSigSendType" SG_ 2527679748 TPMS_WhlChgDetReLe 0;
BA_ "GenSigSendType" SG_ 2527679748 TPMS_WhlChgDetReRi 0;
BA_ "GenSigSendType" SG_ 2463978734 VPS_PaCo_Button 0;
BA_ "GenSigSwitchedByIgnition" SG_ 2463978734 VPS_PaCo_Button 0;
BA_ "GenSigSendType" SG_ 2463978734 VPS_PaCo_CurrentBirdview 3;
BA_ "GenSigSwitchedByIgnition" SG_ 2463978734 VPS_PaCo_CurrentBirdview 0;
BA_ "GenSigSendType" SG_ 2463978734 VPS_PaCo_CurrentBowl 3;
BA_ "GenSigSwitchedByIgnition" SG_ 2463978734 VPS_PaCo_CurrentBowl 0;
BA_ "GenSigSendType" SG_ 2463978734 VPS_PaCo_CurrentCarOverlay 3;
BA_ "GenSigSwitchedByIgnition" SG_ 2463978734 VPS_PaCo_CurrentCarOverlay 0;
BA_ "GenSigSendType" SG_ 2463978734 VPS_PaCo_CurrentMode 3;
BA_ "GenSigSwitchedByIgnition" SG_ 2463978734 VPS_PaCo_CurrentMode 0;
BA_ "GenSigSendType" SG_ 2463978734 VPS_PaCo_CurrentRVCscreen 3;
BA_ "GenSigSwitchedByIgnition" SG_ 2463978734 VPS_PaCo_CurrentRVCscreen 0;
BA_ "GenSigSendType" SG_ 2463978734 VPS_PaCo_CurrentVideoState 3;
BA_ "GenSigSwitchedByIgnition" SG_ 2463978734 VPS_PaCo_CurrentVideoState 0;
BA_ "GenSigSendType" SG_ 2463978734 VPS_PaCo_CurrentView 3;
BA_ "GenSigSwitchedByIgnition" SG_ 2463978734 VPS_PaCo_CurrentView 0;
BA_ "GenSigSendType" SG_ 2463978734 VPS_PaCo_CurrGraphOverlay 3;
BA_ "GenSigSwitchedByIgnition" SG_ 2463978734 VPS_PaCo_CurrGraphOverlay 0;
BA_ "Fehlerwert" SG_ 2463978734 VPS_PaCo_MainState 7;
BA_ "GenSigSendType" SG_ 2463978734 VPS_PaCo_MainState 0;
BA_ "GenSigSwitchedByIgnition" SG_ 2463978734 VPS_PaCo_MainState 0;
BA_ "GenSigSendType" SG_ 2527679742 Kam_Anf_Meldung 0;
BA_ "Fehlerwert" SG_ 2527679742 Kam_PaCo_MainState 7;
BA_ "GenSigSendType" SG_ 2527679742 Kam_PaCo_MainState 0;
BA_ "GenSigSwitchedByIgnition" SG_ 2527679742 Kam_PaCo_MainState 0;
BA_ "Fehlerwert" SG_ 1525 RW_Gesamt_Reichweite 2047;
BA_ "GenSigSendType" SG_ 1525 RW_Gesamt_Reichweite 0;
BA_ "GenSigSwitchedByIgnition" SG_ 1525 RW_Gesamt_Reichweite 0;
BA_ "Fehlerwert" SG_ 1525 RW_Gesamt_Reichweite_Max_Anzeige 2047;
BA_ "GenSigSendType" SG_ 1525 RW_Gesamt_Reichweite_Max_Anzeige 0;
BA_ "GenSigStartValue" SG_ 1525 RW_Gesamt_Reichweite_Max_Anzeige 2046;
BA_ "GenSigSwitchedByIgnition" SG_ 1525 RW_Gesamt_Reichweite_Max_Anzeige 0;
BA_ "GenSigSendType" SG_ 1525 RW_Prim_Reichweitenv_Einheit 0;
BA_ "GenSigStartValue" SG_ 1525 RW_Prim_Reichweitenv_Einheit 3;
BA_ "GenSigSwitchedByIgnition" SG_ 1525 RW_Prim_Reichweitenv_Einheit 0;
BA_ "GenSigSendType" SG_ 1525 RW_Prim_Reichweitenverbrauch 0;
BA_ "GenSigStartValue" SG_ 1525 RW_Prim_Reichweitenverbrauch 2047;
BA_ "GenSigSwitchedByIgnition" SG_ 1525 RW_Prim_Reichweitenverbrauch 0;
BA_ "Fehlerwert" SG_ 1525 RW_Primaer_Reichweite 2047;
BA_ "GenSigSendType" SG_ 1525 RW_Primaer_Reichweite 0;
BA_ "GenSigStartValue" SG_ 1525 RW_Primaer_Reichweite 2046;
BA_ "GenSigSwitchedByIgnition" SG_ 1525 RW_Primaer_Reichweite 0;
BA_ "GenSigSendType" SG_ 1525 RW_Reservewarnung_2_aktiv 0;
BA_ "GenSigSwitchedByIgnition" SG_ 1525 RW_Reservewarnung_2_aktiv 0;
BA_ "Fehlerwert" SG_ 1525 RW_RWDS_Lastprofil 2047;
BA_ "GenSigSendType" SG_ 1525 RW_RWDS_Lastprofil 0;
BA_ "GenSigStartValue" SG_ 1525 RW_RWDS_Lastprofil 2046;
BA_ "GenSigSwitchedByIgnition" SG_ 1525 RW_RWDS_Lastprofil 0;
BA_ "Fehlerwert" SG_ 1527 RW_Gesamt_Reichweite_Anzeige 2047;
BA_ "GenSigSendType" SG_ 1527 RW_Gesamt_Reichweite_Anzeige 0;
BA_ "GenSigStartValue" SG_ 1527 RW_Gesamt_Reichweite_Anzeige 2046;
BA_ "GenSigSwitchedByIgnition" SG_ 1527 RW_Gesamt_Reichweite_Anzeige 0;
BA_ "Fehlerwert" SG_ 1527 RW_Primaer_Reichweite_Anzeige 2047;
BA_ "GenSigSendType" SG_ 1527 RW_Primaer_Reichweite_Anzeige 0;
BA_ "GenSigStartValue" SG_ 1527 RW_Primaer_Reichweite_Anzeige 2046;
BA_ "GenSigSwitchedByIgnition" SG_ 1527 RW_Primaer_Reichweite_Anzeige 0;
BA_ "GenSigSendType" SG_ 1527 RW_Reichweite_Einheit_Anzeige 0;
BA_ "GenSigSwitchedByIgnition" SG_ 1527 RW_Reichweite_Einheit_Anzeige 0;
BA_ "GenSigSendType" SG_ 1527 RW_Reservewarnung_aktiv 0;
BA_ "GenSigSwitchedByIgnition" SG_ 1527 RW_Reservewarnung_aktiv 0;
BA_ "GenSigSendType" SG_ 1527 RW_Sek_Reichweitenv_Einheit 0;
BA_ "GenSigStartValue" SG_ 1527 RW_Sek_Reichweitenv_Einheit 3;
BA_ "GenSigSwitchedByIgnition" SG_ 1527 RW_Sek_Reichweitenv_Einheit 0;
BA_ "GenSigSendType" SG_ 1527 RW_Sek_Reichweitenverbrauch 0;
BA_ "GenSigStartValue" SG_ 1527 RW_Sek_Reichweitenverbrauch 2047;
BA_ "GenSigSwitchedByIgnition" SG_ 1527 RW_Sek_Reichweitenverbrauch 0;
BA_ "Fehlerwert" SG_ 1527 RW_Sekundaer_Reichweite 2047;
BA_ "GenSigSendType" SG_ 1527 RW_Sekundaer_Reichweite 0;
BA_ "GenSigStartValue" SG_ 1527 RW_Sekundaer_Reichweite 2046;
BA_ "GenSigSwitchedByIgnition" SG_ 1527 RW_Sekundaer_Reichweite 0;
BA_ "Fehlerwert" SG_ 1527 RW_Sekundaer_Reichweite_Anzeige 2047;
BA_ "GenSigSendType" SG_ 1527 RW_Sekundaer_Reichweite_Anzeige 0;
BA_ "GenSigStartValue" SG_ 1527 RW_Sekundaer_Reichweite_Anzeige 2046;
BA_ "GenSigSwitchedByIgnition" SG_ 1527 RW_Sekundaer_Reichweite_Anzeige 0;
BA_ "GenSigSendType" SG_ 1527 RW_Tendenz 0;
BA_ "GenSigSwitchedByIgnition" SG_ 1527 RW_Tendenz 0;
BA_ "GenSigSendType" SG_ 1527 RW_Texte 3;
BA_ "GenSigSwitchedByIgnition" SG_ 1527 RW_Texte 0;
BA_ "GenSigSendType" SG_ 2527679676 RW_Prim_rRWB_aktiv 0;
BA_ "GenSigStartValue" SG_ 2527679676 RW_Prim_rRWB_aktiv 3;
BA_ "GenSigSwitchedByIgnition" SG_ 2527679676 RW_Prim_rRWB_aktiv 0;
BA_ "Fehlerwert" SG_ 2527679676 RW_Prim_rRWB_Reichw_Anz 2047;
BA_ "GenSigSendType" SG_ 2527679676 RW_Prim_rRWB_Reichw_Anz 0;
BA_ "GenSigStartValue" SG_ 2527679676 RW_Prim_rRWB_Reichw_Anz 2046;
BA_ "GenSigSwitchedByIgnition" SG_ 2527679676 RW_Prim_rRWB_Reichw_Anz 0;
BA_ "Fehlerwert" SG_ 2527679676 RW_Prim_rRWB_Reichw_Gesamt_Anz 2047;
BA_ "GenSigSendType" SG_ 2527679676 RW_Prim_rRWB_Reichw_Gesamt_Anz 0;
BA_ "GenSigStartValue" SG_ 2527679676 RW_Prim_rRWB_Reichw_Gesamt_Anz 2046;
BA_ "GenSigSwitchedByIgnition" SG_ 2527679676 RW_Prim_rRWB_Reichw_Gesamt_Anz 0;
BA_ "Fehlerwert" SG_ 2527679676 RW_Prim_rRWB_Reichw_Max_Ges_Anz 2047;
BA_ "GenSigSendType" SG_ 2527679676 RW_Prim_rRWB_Reichw_Max_Ges_Anz 0;
BA_ "GenSigStartValue" SG_ 2527679676 RW_Prim_rRWB_Reichw_Max_Ges_Anz 2046;
BA_ "GenSigSwitchedByIgnition" SG_ 2527679676 RW_Prim_rRWB_Reichw_Max_Ges_Anz 0;
BA_ "Fehlerwert" SG_ 2527679676 RW_Prim_rRWB_Reichw_Rest_E_Anz 2047;
BA_ "GenSigSendType" SG_ 2527679676 RW_Prim_rRWB_Reichw_Rest_E_Anz 0;
BA_ "GenSigStartValue" SG_ 2527679676 RW_Prim_rRWB_Reichw_Rest_E_Anz 2046;
BA_ "GenSigSwitchedByIgnition" SG_ 2527679676 RW_Prim_rRWB_Reichw_Rest_E_Anz 0;
BA_ "Fehlerwert" SG_ 2527679676 RW_Prim_statische_Reichw_Anz 2047;
BA_ "GenSigSendType" SG_ 2527679676 RW_Prim_statische_Reichw_Anz 0;
BA_ "GenSigStartValue" SG_ 2527679676 RW_Prim_statische_Reichw_Anz 2046;
BA_ "GenSigSwitchedByIgnition" SG_ 2527679676 RW_Prim_statische_Reichw_Anz 0;
BA_ "GenSigSendType" SG_ 1610 RKA_FMVSS138_Lampe 0;
BA_ "GenSigSwitchedByIgnition" SG_ 1610 RKA_FMVSS138_Lampe 0;
BA_ "GenSigSendType" SG_ 1610 RKA_FMVSS138_MIL 0;
BA_ "GenSigSwitchedByIgnition" SG_ 1610 RKA_FMVSS138_MIL 0;
BA_ "GenSigSendType" SG_ 1610 RKA_Reifentyp 0;
BA_ "GenSigSwitchedByIgnition" SG_ 1610 RKA_Reifentyp 0;
BA_ "GenSigSendType" SG_ 1610 RKA_Warnungen_02 0;
BA_ "GenSigSwitchedByIgnition" SG_ 1610 RKA_Warnungen_02 0;
BA_ "GenSigSendType" SG_ 1440 LS_defekt 0;
BA_ "GenSigSwitchedByIgnition" SG_ 1440 LS_defekt 0;
BA_ "Fehlerwert" SG_ 1440 LS_Helligkeit_FW 1023;
BA_ "GenSigMissingSourceValue" SG_ 1440 LS_Helligkeit_FW 1023;
BA_ "GenSigSendType" SG_ 1440 LS_Helligkeit_FW 0;
BA_ "GenSigStartValue" SG_ 1440 LS_Helligkeit_FW 1022;
BA_ "GenSigSwitchedByIgnition" SG_ 1440 LS_Helligkeit_FW 0;
BA_ "Fehlerwert" SG_ 1440 LS_Helligkeit_IR 255;
BA_ "GenSigMissingSourceValue" SG_ 1440 LS_Helligkeit_IR 255;
BA_ "GenSigSendType" SG_ 1440 LS_Helligkeit_IR 0;
BA_ "GenSigStartValue" SG_ 1440 LS_Helligkeit_IR 254;
BA_ "GenSigSwitchedByIgnition" SG_ 1440 LS_Helligkeit_IR 0;
BA_ "GenSigSendType" SG_ 1440 LS_Verbau 0;
BA_ "GenSigSwitchedByIgnition" SG_ 1440 LS_Verbau 0;
BA_ "GenSigSendType" SG_ 1440 RLS_Vorfeldhelligkeit_Boost 0;
BA_ "GenSigStartValue" SG_ 1440 RLS_Vorfeldhelligkeit_Boost 15;
BA_ "GenSigSwitchedByIgnition" SG_ 1440 RLS_Vorfeldhelligkeit_Boost 0;
BA_ "GenSigSendType" SG_ 1440 RS_defekt 0;
BA_ "GenSigSwitchedByIgnition" SG_ 1440 RS_defekt 0;
BA_ "Fehlerwert" SG_ 1440 RS_Regenmenge 15;
BA_ "GenSigMissingSourceValue" SG_ 1440 RS_Regenmenge 15;
BA_ "GenSigSendType" SG_ 1440 RS_Regenmenge 0;
BA_ "GenSigStartValue" SG_ 1440 RS_Regenmenge 14;
BA_ "GenSigSwitchedByIgnition" SG_ 1440 RS_Regenmenge 0;
BA_ "GenSigSendType" SG_ 1440 RS_Schwall 0;
BA_ "GenSigSwitchedByIgnition" SG_ 1440 RS_Schwall 0;
BA_ "GenSigSendType" SG_ 1440 RS_Verbau 0;
BA_ "GenSigSwitchedByIgnition" SG_ 1440 RS_Verbau 0;
BA_ "GenSigSendType" SG_ 1440 RS_Verglasung_schliessen 0;
BA_ "GenSigSwitchedByIgnition" SG_ 1440 RS_Verglasung_schliessen 0;
BA_ "GenSigSendType" SG_ 1440 RS_Wischergeschwindigkeit 0;
BA_ "GenSigSwitchedByIgnition" SG_ 1440 RS_Wischergeschwindigkeit 0;
BA_ "Fehlerwert" SG_ 1440 SLS_Helligkeit_IR 255;
BA_ "GenSigSendType" SG_ 1440 SLS_Helligkeit_IR 0;
BA_ "GenSigStartValue" SG_ 1440 SLS_Helligkeit_IR 254;
BA_ "GenSigSwitchedByIgnition" SG_ 1440 SLS_Helligkeit_IR 0;
BA_ "GenSigSendType" SG_ 2527679669 LS_Autobahnfahrlicht 0;
BA_ "GenSigSwitchedByIgnition" SG_ 2527679669 LS_Autobahnfahrlicht 0;
BA_ "GenSigSendType" SG_ 2527679669 LS_Dunkel 0;
BA_ "GenSigSwitchedByIgnition" SG_ 2527679669 LS_Dunkel 0;
BA_ "Fehlerwert" SG_ 2527679669 LS_Error 1;
BA_ "GenSigSendType" SG_ 2527679669 LS_Error 0;
BA_ "GenSigSwitchedByIgnition" SG_ 2527679669 LS_Error 0;
BA_ "Fehlerwert" SG_ 2527679669 LS_Helligkeit_FW 1023;
BA_ "GenSigMissingSourceValue" SG_ 2527679669 LS_Helligkeit_FW 1023;
BA_ "GenSigSendType" SG_ 2527679669 LS_Helligkeit_FW 0;
BA_ "GenSigStartValue" SG_ 2527679669 LS_Helligkeit_FW 1022;
BA_ "GenSigSwitchedByIgnition" SG_ 2527679669 LS_Helligkeit_FW 0;
BA_ "Fehlerwert" SG_ 2527679669 LS_Helligkeit_IR 255;
BA_ "GenSigMissingSourceValue" SG_ 2527679669 LS_Helligkeit_IR 255;
BA_ "GenSigSendType" SG_ 2527679669 LS_Helligkeit_IR 0;
BA_ "GenSigStartValue" SG_ 2527679669 LS_Helligkeit_IR 254;
BA_ "GenSigSwitchedByIgnition" SG_ 2527679669 LS_Helligkeit_IR 0;
BA_ "GenSigSendType" SG_ 2527679669 LS_Licht_ein 0;
BA_ "GenSigSwitchedByIgnition" SG_ 2527679669 LS_Licht_ein 0;
BA_ "GenSigSendType" SG_ 2527679669 LS_Licht_ein_invers 0;
BA_ "GenSigStartValue" SG_ 2527679669 LS_Licht_ein_invers 1;
BA_ "GenSigSwitchedByIgnition" SG_ 2527679669 LS_Licht_ein_invers 0;
BA_ "GenSigFuncType" SG_ 2527679669 RLS_02_BZ 1;
BA_ "GenSigSendType" SG_ 2527679669 RLS_02_BZ 0;
BA_ "GenSigSwitchedByIgnition" SG_ 2527679669 RLS_02_BZ 0;
BA_ "GenSigFuncType" SG_ 2527679669 RLS_02_CRC 2;
BA_ "GenSigSendType" SG_ 2527679669 RLS_02_CRC 0;
BA_ "GenSigSwitchedByIgnition" SG_ 2527679669 RLS_02_CRC 0;
BA_ "GenSigSendType" SG_ 2527679669 RLS_Qualifizierungsbit 0;
BA_ "GenSigSwitchedByIgnition" SG_ 2527679669 RLS_Qualifizierungsbit 0;
BA_ "Fehlerwert" SG_ 2527679669 RLS_ResponseError 1;
BA_ "GenSigSendType" SG_ 2527679669 RLS_ResponseError 0;
BA_ "GenSigSwitchedByIgnition" SG_ 2527679669 RLS_ResponseError 0;
BA_ "GenSigSendType" SG_ 2527679669 RLS_Vorfeldhelligkeit_Boost 0;
BA_ "GenSigStartValue" SG_ 2527679669 RLS_Vorfeldhelligkeit_Boost 15;
BA_ "GenSigSwitchedByIgnition" SG_ 2527679669 RLS_Vorfeldhelligkeit_Boost 0;
BA_ "Fehlerwert" SG_ 2527679669 RS_AdaptierungError 1;
BA_ "GenSigSendType" SG_ 2527679669 RS_AdaptierungError 0;
BA_ "GenSigSwitchedByIgnition" SG_ 2527679669 RS_AdaptierungError 0;
BA_ "Fehlerwert" SG_ 2527679669 RS_Error 1;
BA_ "GenSigSendType" SG_ 2527679669 RS_Error 0;
BA_ "GenSigSwitchedByIgnition" SG_ 2527679669 RS_Error 0;
BA_ "GenSigSendType" SG_ 2527679669 RS_Regenfahrlicht 0;
BA_ "GenSigSwitchedByIgnition" SG_ 2527679669 RS_Regenfahrlicht 0;
BA_ "Fehlerwert" SG_ 2527679669 RS_Regenmenge 15;
BA_ "GenSigMissingSourceValue" SG_ 2527679669 RS_Regenmenge 15;
BA_ "GenSigSendType" SG_ 2527679669 RS_Regenmenge 0;
BA_ "GenSigStartValue" SG_ 2527679669 RS_Regenmenge 14;
BA_ "GenSigSwitchedByIgnition" SG_ 2527679669 RS_Regenmenge 0;
BA_ "GenSigSendType" SG_ 2527679669 RS_Schwall 0;
BA_ "GenSigSwitchedByIgnition" SG_ 2527679669 RS_Schwall 0;
BA_ "GenSigSendType" SG_ 2527679669 RS_Verglasung_schliessen 0;
BA_ "GenSigSwitchedByIgnition" SG_ 2527679669 RS_Verglasung_schliessen 0;
BA_ "GenSigSendType" SG_ 2527679669 RS_versParklage_Wischer 0;
BA_ "GenSigSwitchedByIgnition" SG_ 2527679669 RS_versParklage_Wischer 0;
BA_ "GenSigSendType" SG_ 2527679669 RS_Wischergeschwindigkeit 0;
BA_ "GenSigSwitchedByIgnition" SG_ 2527679669 RS_Wischergeschwindigkeit 0;
BA_ "GenSigSendType" SG_ 2463978697 AFS_Lampe 3;
BA_ "GenSigSendType" SG_ 2463978697 BCM2_Bremsl_durch_ECD 4;
BA_ "GenSigSwitchedByIgnition" SG_ 2463978697 BCM2_Bremsl_durch_ECD 0;
BA_ "Fehlerwert" SG_ 2463978697 DLI_Ambex_RefStatus 4;
BA_ "GenSigSendType" SG_ 2463978697 DLI_Ambex_RefStatus 3;
BA_ "GenSigSwitchedByIgnition" SG_ 2463978697 DLI_Ambex_RefStatus 0;
BA_ "GenSigSendType" SG_ 2463978697 LWR_Lampe 3;
BA_ "GenSigSendType" SG_ 2463978697 LWR_Reisemodus_Texte 3;
BA_ "Fehlerwert" SG_ 2463978697 LWR_SollDC 255;
BA_ "GenSigSendType" SG_ 2463978697 LWR_SollDC 3;
BA_ "GenSigStartValue" SG_ 2463978697 LWR_SollDC 254;
BA_ "GenSigSwitchedByIgnition" SG_ 2463978697 LWR_SollDC 0;
BA_ "GenSigFuncType" SG_ 2463978697 SAL_01_BZ 1;
BA_ "GenSigSendType" SG_ 2463978697 SAL_01_BZ 0;
BA_ "GenSigSwitchedByIgnition" SG_ 2463978697 SAL_01_BZ 0;
BA_ "GenSigFuncType" SG_ 2463978697 SAL_01_CRC 2;
BA_ "GenSigSendType" SG_ 2463978697 SAL_01_CRC 0;
BA_ "GenSigSwitchedByIgnition" SG_ 2463978697 SAL_01_CRC 0;
BA_ "GenSigSendType" SG_ 2463978697 SAL_Aussenbeleuchtung_defekt 3;
BA_ "GenSigSwitchedByIgnition" SG_ 2463978697 SAL_Aussenbeleuchtung_defekt 0;
BA_ "GenSigSendType" SG_ 2463978697 SAL_Blinkerzyklus_L 3;
BA_ "GenSigSwitchedByIgnition" SG_ 2463978697 SAL_Blinkerzyklus_L 0;
BA_ "GenSigSendType" SG_ 2463978697 SAL_Blinkerzyklus_R 3;
BA_ "GenSigSwitchedByIgnition" SG_ 2463978697 SAL_Blinkerzyklus_R 0;
BA_ "GenSigSendType" SG_ 2463978697 SAL_BLK_L_Anf 4;
BA_ "GenSigSwitchedByIgnition" SG_ 2463978697 SAL_BLK_L_Anf 0;
BA_ "GenSigSendType" SG_ 2463978697 SAL_BLK_R_Anf 4;
BA_ "GenSigSwitchedByIgnition" SG_ 2463978697 SAL_BLK_R_Anf 0;
BA_ "GenSigSendType" SG_ 2463978697 SAL_Bremszyklus 3;
BA_ "GenSigSwitchedByIgnition" SG_ 2463978697 SAL_Bremszyklus 0;
BA_ "GenSigSendType" SG_ 2463978697 SAL_BRL_Anf 4;
BA_ "GenSigSwitchedByIgnition" SG_ 2463978697 SAL_BRL_Anf 0;
BA_ "GenSigSendType" SG_ 2463978697 SAL_CH_Anf 4;
BA_ "GenSigSwitchedByIgnition" SG_ 2463978697 SAL_CH_Anf 0;
BA_ "GenSigSendType" SG_ 2463978697 SAL_HGB_Anf 4;
BA_ "GenSigSwitchedByIgnition" SG_ 2463978697 SAL_HGB_Anf 0;
BA_ "GenSigSendType" SG_ 2463978697 SAL_Kl_15 3;
BA_ "GenSigSwitchedByIgnition" SG_ 2463978697 SAL_Kl_15 0;
BA_ "GenSigSendType" SG_ 2463978697 SAL_Kl_15_vFzg 3;
BA_ "GenSigSwitchedByIgnition" SG_ 2463978697 SAL_Kl_15_vFzg 0;
BA_ "GenSigSendType" SG_ 2463978697 SAL_Kl_15_vFzg_S 3;
BA_ "GenSigSwitchedByIgnition" SG_ 2463978697 SAL_Kl_15_vFzg_S 0;
BA_ "GenSigSendType" SG_ 2463978697 SAL_KL_50 3;
BA_ "GenSigSwitchedByIgnition" SG_ 2463978697 SAL_KL_50 0;
BA_ "GenSigSendType" SG_ 2463978697 SAL_KL_50_5s 3;
BA_ "GenSigSwitchedByIgnition" SG_ 2463978697 SAL_KL_50_5s 0;
BA_ "GenSigSendType" SG_ 2463978697 SAL_Kl_75 3;
BA_ "GenSigSwitchedByIgnition" SG_ 2463978697 SAL_Kl_75 0;
BA_ "GenSigSendType" SG_ 2463978697 SAL_KL_75_vFzg 3;
BA_ "GenSigSwitchedByIgnition" SG_ 2463978697 SAL_KL_75_vFzg 0;
BA_ "GenSigSendType" SG_ 2463978697 SAL_KL_75a 3;
BA_ "GenSigSwitchedByIgnition" SG_ 2463978697 SAL_KL_75a 0;
BA_ "GenSigSendType" SG_ 2463978697 SAL_KL_75a_vFzg 3;
BA_ "GenSigSwitchedByIgnition" SG_ 2463978697 SAL_KL_75a_vFzg 0;
BA_ "GenSigSendType" SG_ 2463978697 SAL_KZL_Anf 4;
BA_ "GenSigSwitchedByIgnition" SG_ 2463978697 SAL_KZL_Anf 0;
BA_ "GenSigSendType" SG_ 2463978697 SAL_LDS_Abblendlicht_Anf 4;
BA_ "GenSigSwitchedByIgnition" SG_ 2463978697 SAL_LDS_Abblendlicht_Anf 0;
BA_ "GenSigSendType" SG_ 2463978697 SAL_LDS_Assistenzfahrlicht_Anf 4;
BA_ "GenSigSwitchedByIgnition" SG_ 2463978697 SAL_LDS_Assistenzfahrlicht_Anf 0;
BA_ "GenSigSendType" SG_ 2463978697 SAL_LDS_Nullstellung_Anf 4;
BA_ "GenSigSwitchedByIgnition" SG_ 2463978697 SAL_LDS_Nullstellung_Anf 0;
BA_ "GenSigSendType" SG_ 2463978697 SAL_LDS_Standlicht_Anf 4;
BA_ "GenSigSwitchedByIgnition" SG_ 2463978697 SAL_LDS_Standlicht_Anf 0;
BA_ "GenSigSendType" SG_ 2463978697 SAL_LH_Anf 4;
BA_ "GenSigSwitchedByIgnition" SG_ 2463978697 SAL_LH_Anf 0;
BA_ "GenSigSendType" SG_ 2463978697 SAL_NSL_Anf 4;
BA_ "GenSigSwitchedByIgnition" SG_ 2463978697 SAL_NSL_Anf 0;
BA_ "GenSigSendType" SG_ 2463978697 SAL_PL_L_Anf 4;
BA_ "GenSigSwitchedByIgnition" SG_ 2463978697 SAL_PL_L_Anf 0;
BA_ "GenSigSendType" SG_ 2463978697 SAL_PL_R_Anf 4;
BA_ "GenSigSwitchedByIgnition" SG_ 2463978697 SAL_PL_R_Anf 0;
BA_ "GenSigSendType" SG_ 2463978697 SAL_RFL_Anf 4;
BA_ "GenSigSwitchedByIgnition" SG_ 2463978697 SAL_RFL_Anf 0;
BA_ "GenSigSendType" SG_ 2463978697 SAL_SL_Anf 4;
BA_ "GenSigSwitchedByIgnition" SG_ 2463978697 SAL_SL_Anf 0;
BA_ "GenSigSendType" SG_ 2463978697 SAL_WBT_Bel 4;
BA_ "GenSigSwitchedByIgnition" SG_ 2463978697 SAL_WBT_Bel 0;
BA_ "GenSigSendType" SG_ 2463978697 SBBR_SL_AnimDimm_Freigabe 3;
BA_ "GenSigSwitchedByIgnition" SG_ 2463978697 SBBR_SL_AnimDimm_Freigabe 0;
BA_ "GenSigSendType" SG_ 517 BCM_Bremsbelag_Sensor_CND 4;
BA_ "GenSigSwitchedByIgnition" SG_ 517 BCM_Bremsbelag_Sensor_CND 0;
BA_ "GenSigSendType" SG_ 517 BCM_Bremsbelag_Sensor_NAR 4;
BA_ "GenSigSwitchedByIgnition" SG_ 517 BCM_Bremsbelag_Sensor_NAR 0;
BA_ "GenSigSendType" SG_ 517 BCM_Bremsbelag_Sensor_Rdw 4;
BA_ "GenSigSwitchedByIgnition" SG_ 517 BCM_Bremsbelag_Sensor_Rdw 0;
BA_ "GenSigSendType" SG_ 517 BCM_KiSi_Umschalt_gesperrt 3;
BA_ "GenSigSwitchedByIgnition" SG_ 517 BCM_KiSi_Umschalt_gesperrt 0;
BA_ "Fehlerwert" SG_ 517 BCM_Tankklappensteller_Fehler 1;
BA_ "GenSigSendType" SG_ 517 BCM_Tankklappensteller_Fehler 0;
BA_ "GenSigSwitchedByIgnition" SG_ 517 BCM_Tankklappensteller_Fehler 0;
BA_ "GenSigSendType" SG_ 517 BRL_Bremslicht_Schalter 3;
BA_ "GenSigSwitchedByIgnition" SG_ 517 BRL_Bremslicht_Schalter 0;
BA_ "GenSigSendType" SG_ 517 HD_Hauptraste 4;
BA_ "GenSigSwitchedByIgnition" SG_ 517 HD_Hauptraste 0;
BA_ "GenSigSendType" SG_ 517 HD_Vorraste 4;
BA_ "GenSigSwitchedByIgnition" SG_ 517 HD_Vorraste 0;
BA_ "GenSigSendType" SG_ 517 HW_Drehfalle_Tuer_HL 4;
BA_ "GenSigSwitchedByIgnition" SG_ 517 HW_Drehfalle_Tuer_HL 0;
BA_ "GenSigSendType" SG_ 517 HW_Drehfalle_Tuer_HR 4;
BA_ "GenSigSwitchedByIgnition" SG_ 517 HW_Drehfalle_Tuer_HR 0;
BA_ "GenSigSendType" SG_ 517 HW_HD_Taste_Innenraum 4;
BA_ "GenSigSwitchedByIgnition" SG_ 517 HW_HD_Taste_Innenraum 0;
BA_ "GenSigSendType" SG_ 517 HW_HSB_erkannt 4;
BA_ "GenSigSwitchedByIgnition" SG_ 517 HW_HSB_erkannt 0;
BA_ "GenSigSendType" SG_ 517 HW_MH_Schalter1 4;
BA_ "GenSigSwitchedByIgnition" SG_ 517 HW_MH_Schalter1 0;
BA_ "GenSigSendType" SG_ 517 HW_MH_Schalter2 4;
BA_ "GenSigSwitchedByIgnition" SG_ 517 HW_MH_Schalter2 0;
BA_ "GenSigSendType" SG_ 517 HW_Softtouch_betaetigt 4;
BA_ "GenSigSwitchedByIgnition" SG_ 517 HW_Softtouch_betaetigt 0;
BA_ "GenSigSendType" SG_ 517 HW_Status_Schloss_gesafet_HL 4;
BA_ "GenSigSwitchedByIgnition" SG_ 517 HW_Status_Schloss_gesafet_HL 0;
BA_ "GenSigSendType" SG_ 517 HW_Status_Schloss_gesafet_HR 4;
BA_ "GenSigSwitchedByIgnition" SG_ 517 HW_Status_Schloss_gesafet_HR 0;
BA_ "GenSigSendType" SG_ 517 HW_Status_Schloss_verriegelt_HL 4;
BA_ "GenSigSwitchedByIgnition" SG_ 517 HW_Status_Schloss_verriegelt_HL 0;
BA_ "GenSigSendType" SG_ 517 HW_Status_Schloss_verriegelt_HR 4;
BA_ "GenSigSwitchedByIgnition" SG_ 517 HW_Status_Schloss_verriegelt_HR 0;
BA_ "GenSigSendType" SG_ 517 HW_Tankdeckel_offen 4;
BA_ "GenSigSwitchedByIgnition" SG_ 517 HW_Tankdeckel_offen 0;
BA_ "GenSigSendType" SG_ 517 HW_Toggle_Taster 4;
BA_ "GenSigSwitchedByIgnition" SG_ 517 HW_Toggle_Taster 0;
BA_ "GenSigSendType" SG_ 517 KST_BSW_Fehlermode2 3;
BA_ "GenSigSwitchedByIgnition" SG_ 517 KST_BSW_Fehlermode2 0;
BA_ "Fehlerwert" SG_ 517 KST_BSW_Klemme_15_HW_Ist 3;
BA_ "GenSigSendType" SG_ 517 KST_BSW_Klemme_15_HW_Ist 3;
BA_ "GenSigSwitchedByIgnition" SG_ 517 KST_BSW_Klemme_15_HW_Ist 0;
BA_ "GenSigSendType" SG_ 517 KST_BSW_Klemmenhochschalten_Sper 3;
BA_ "GenSigSwitchedByIgnition" SG_ 517 KST_BSW_Klemmenhochschalten_Sper 0;
BA_ "GenSigSendType" SG_ 517 KST_BSW_Not_Taster_betaetigt 3;
BA_ "GenSigSwitchedByIgnition" SG_ 517 KST_BSW_Not_Taster_betaetigt 0;
BA_ "GenSigSendType" SG_ 517 KST_BSW_ZAT_betaetigt 4;
BA_ "GenSigSwitchedByIgnition" SG_ 517 KST_BSW_ZAT_betaetigt 0;
BA_ "GenSigSendType" SG_ 517 SAL_li1_Blinker_Status 4;
BA_ "GenSigSwitchedByIgnition" SG_ 517 SAL_li1_Blinker_Status 0;
BA_ "GenSigSendType" SG_ 517 SAL_re1_Blinker_Status 4;
BA_ "GenSigSwitchedByIgnition" SG_ 517 SAL_re1_Blinker_Status 0;
BA_ "GenSigFuncType" SG_ 517 SAM_01_BZ 1;
BA_ "GenSigSendType" SG_ 517 SAM_01_BZ 0;
BA_ "GenSigSwitchedByIgnition" SG_ 517 SAM_01_BZ 0;
BA_ "GenSigFuncType" SG_ 517 SAM_01_CRC 2;
BA_ "GenSigSendType" SG_ 517 SAM_01_CRC 0;
BA_ "GenSigSwitchedByIgnition" SG_ 517 SAM_01_CRC 0;
BA_ "Fehlerwert" SG_ 517 SAM_Fehler_DC_LWR 1;
BA_ "GenSigSendType" SG_ 517 SAM_Fehler_DC_LWR 3;
BA_ "GenSigSwitchedByIgnition" SG_ 517 SAM_Fehler_DC_LWR 0;
BA_ "GenSigSendType" SG_ 517 ZV_Ladeklappe_VerEntriegeln 3;
BA_ "GenSigSwitchedByIgnition" SG_ 517 ZV_Ladeklappe_VerEntriegeln 0;
BA_ "GenSigSendType" SG_ 517 ZV_LadeklappenStatus 3;
BA_ "GenSigSwitchedByIgnition" SG_ 517 ZV_LadeklappenStatus 0;
BA_ "Fehlerwert" SG_ 1522 KBI_Dimmpoti 127;
BA_ "GenSigSendType" SG_ 1522 KBI_Dimmpoti 0;
BA_ "GenSigSwitchedByIgnition" SG_ 1522 KBI_Dimmpoti 0;
BA_ "Fehlerwert" SG_ 1522 KBI_Phototransistor 255;
BA_ "GenSigSendType" SG_ 1522 KBI_Phototransistor 3;
BA_ "GenSigStartValue" SG_ 1522 KBI_Phototransistor 254;
BA_ "GenSigSwitchedByIgnition" SG_ 1522 KBI_Phototransistor 0;
BA_REL_ "GenSigTimeoutTime" BU_SG_REL_ Fahrerdisplay_Kombi SG_ 1610 RKA_FMVSS138_Lampe 5000;
BA_REL_ "GenSigTimeoutTime" BU_SG_REL_ Fahrerdisplay_Kombi SG_ 1610 RKA_FMVSS138_MIL 5000;
BA_REL_ "GenSigTimeoutTime" BU_SG_REL_ HUD SG_ 2527679669 LS_Helligkeit_FW 800;
BA_REL_ "GenSigTimeoutTime" BU_SG_REL_ HUD SG_ 2527679669 LS_Helligkeit_IR 800;
BA_REL_ "GenSigTimeoutTime" BU_SG_REL_ HUD SG_ 2527679669 RLS_02_BZ 800;
BA_REL_ "GenSigTimeoutTime" BU_SG_REL_ HUD SG_ 2527679669 RLS_02_CRC 800;
BA_REL_ "GenSigTimeoutTime" BU_SG_REL_ HUD SG_ 2527679669 RLS_Vorfeldhelligkeit_Boost 800;
BA_REL_ "GenSigTimeoutTime" BU_SG_REL_ ICAS1_X_Gateway SG_ 1122 PSD_Rampe 1500;
BA_REL_ "GenSigTimeoutTime" BU_SG_REL_ ICAS1_X_Gateway SG_ 1122 PSD_Strassenkategorie 1500;
BA_REL_ "GenSigTimeoutTime" BU_SG_REL_ ICAS1_X_Gateway SG_ 1123 PSD_Pos_Fahrspur 1500;
BA_REL_ "GenSigTimeoutTime" BU_SG_REL_ ICAS1_X_Gateway SG_ 1522 KBI_Phototransistor 2000;
BA_REL_ "GenSigTimeoutTime" BU_SG_REL_ ICAS3_Gateway SG_ 517 HW_Drehfalle_Tuer_HL 2000;
BA_REL_ "GenSigTimeoutTime" BU_SG_REL_ ICAS3_Gateway SG_ 517 HW_Drehfalle_Tuer_HR 2000;
BA_REL_ "GenSigTimeoutTime" BU_SG_REL_ ICAS3_Gateway SG_ 517 HW_Status_Schloss_verriegelt_HL 2000;
BA_REL_ "GenSigTimeoutTime" BU_SG_REL_ ICAS3_Gateway SG_ 517 HW_Status_Schloss_verriegelt_HR 2000;
BA_REL_ "GenSigTimeoutTime" BU_SG_REL_ ICAS3_Gateway SG_ 1175 PH_Anf_Audioabsenkung 1000;
BA_REL_ "GenSigTimeoutTime" BU_SG_REL_ ICAS3_Gateway SG_ 1175 PH_Visualisierung 1000;
BA_REL_ "GenSigTimeoutTime" BU_SG_REL_ ICAS3_Gateway SG_ 1355 PH_Ton_Ausgabe 5000;
BA_REL_ "GenSigTimeoutTime" BU_SG_REL_ ICAS3_Gateway SG_ 1355 PH_Ton_Lautstaerke 5000;
BA_REL_ "GenSigTimeoutTime" BU_SG_REL_ ICAS3_Gateway SG_ 1355 PH_Ton_Pausenlaenge 5000;
BA_REL_ "GenSigTimeoutTime" BU_SG_REL_ ICAS3_Gateway SG_ 1355 PH_Ton_Richtung 5000;
BA_REL_ "GenSigTimeoutTime" BU_SG_REL_ ICAS3_Gateway SG_ 2463978734 VPS_PaCo_CurrentVideoState 1000;
BA_REL_ "GenSigTimeoutTime" BU_SG_REL_ ICAS3_Gateway SG_ 2527679498 IAA_Active_User_ID 5000;
BA_REL_ "GenSigTimeoutTime" BU_SG_REL_ ICAS3_Gateway SG_ 2527679498 IAA_Identified_User_ID 5000;
BA_REL_ "GenSigTimeoutTime" BU_SG_REL_ ICAS3_Gateway SG_ 2527679498 IAA_PSO_wake_up 5000;
BA_REL_ "GenSigTimeoutTime" BU_SG_REL_ ICAS3_Gateway SG_ 2527679498 Perso_Aktiv 5000;
BA_REL_ "GenSigTimeoutTime" BU_SG_REL_ ICAS3_Gateway SG_ 2527679498 Perso_Bedienstelle 5000;
BA_REL_ "GenSigTimeoutTime" BU_SG_REL_ ICAS3_Gateway SG_ 2527679498 Perso_Fahrernummer 5000;
BA_REL_ "GenSigTimeoutTime" BU_SG_REL_ ICAS3_Gateway SG_ 2527679498 Perso_Freigabe_Verstellung 5000;
BA_REL_ "GenSigTimeoutTime" BU_SG_REL_ ICAS3_Gateway SG_ 2527679498 Perso_Kontonummer 5000;
BA_REL_ "GenSigTimeoutTime" BU_SG_REL_ ICAS3_Gateway SG_ 2527679498 Perso_Schreibschutz 5000;
BA_REL_ "GenSigTimeoutTime" BU_SG_REL_ ICAS3_Gateway SG_ 2527679498 Perso_Status 5000;
BA_REL_ "GenSigTimeoutTime" BU_SG_REL_ ICAS3_Gateway SG_ 2527679498 Perso_Steuerung 5000;
BA_REL_ "GenSigTimeoutTime" BU_SG_REL_ ICAS3_Gateway SG_ 2527679498 Perso_Steuerungsparameter 5000;
BA_REL_ "GenSigTimeoutTime" BU_SG_REL_ Kombi SG_ 319 SC_PreCrash_Texte 2000;
BA_REL_ "GenSigTimeoutTime" BU_SG_REL_ Kombi SG_ 319 SC_PreCrash_Warnung 2000;
BA_REL_ "GenSigTimeoutTime" BU_SG_REL_ Kombi SG_ 517 BCM_Bremsbelag_Sensor_CND 2000;
BA_REL_ "GenSigTimeoutTime" BU_SG_REL_ Kombi SG_ 517 BCM_Bremsbelag_Sensor_NAR 2000;
BA_REL_ "GenSigTimeoutTime" BU_SG_REL_ Kombi SG_ 517 BCM_Bremsbelag_Sensor_Rdw 2000;
BA_REL_ "GenSigTimeoutTime" BU_SG_REL_ Kombi SG_ 1124 PSD_Sys_Laendercode 1500;
BA_REL_ "GenSigTimeoutTime" BU_SG_REL_ Kombi SG_ 1175 PH_Stoermeldung 1000;
BA_REL_ "GenSigTimeoutTime" BU_SG_REL_ Kombi SG_ 1355 PH_Verschmutzungsmeldung 5000;
BA_REL_ "GenSigTimeoutTime" BU_SG_REL_ Kombi SG_ 1355 PH_WAH_Meldung 5000;
BA_REL_ "GenSigTimeoutTime" BU_SG_REL_ Kombi SG_ 1355 RBF_Anf_Meldungen 5000;
BA_REL_ "GenSigTimeoutTime" BU_SG_REL_ Kombi SG_ 1440 RS_defekt 2000;
BA_REL_ "GenSigTimeoutTime" BU_SG_REL_ Kombi SG_ 1525 RW_Gesamt_Reichweite 5000;
BA_REL_ "GenSigTimeoutTime" BU_SG_REL_ Kombi SG_ 1525 RW_Gesamt_Reichweite_Max_Anzeige 5000;
BA_REL_ "GenSigTimeoutTime" BU_SG_REL_ Kombi SG_ 1525 RW_Prim_Reichweitenv_Einheit 5000;
BA_REL_ "GenSigTimeoutTime" BU_SG_REL_ Kombi SG_ 1525 RW_Prim_Reichweitenverbrauch 5000;
BA_REL_ "GenSigTimeoutTime" BU_SG_REL_ Kombi SG_ 1525 RW_Primaer_Reichweite 5000;
BA_REL_ "GenSigTimeoutTime" BU_SG_REL_ Kombi SG_ 1525 RW_RWDS_Lastprofil 5000;
BA_REL_ "GenSigTimeoutTime" BU_SG_REL_ Kombi SG_ 1525 RW_Reservewarnung_2_aktiv 5000;
BA_REL_ "GenSigTimeoutTime" BU_SG_REL_ Kombi SG_ 1527 RW_Gesamt_Reichweite_Anzeige 5000;
BA_REL_ "GenSigTimeoutTime" BU_SG_REL_ Kombi SG_ 1527 RW_Primaer_Reichweite_Anzeige 5000;
BA_REL_ "GenSigTimeoutTime" BU_SG_REL_ Kombi SG_ 1527 RW_Reichweite_Einheit_Anzeige 5000;
BA_REL_ "GenSigTimeoutTime" BU_SG_REL_ Kombi SG_ 1527 RW_Reservewarnung_aktiv 5000;
BA_REL_ "GenSigTimeoutTime" BU_SG_REL_ Kombi SG_ 1527 RW_Sek_Reichweitenv_Einheit 5000;
BA_REL_ "GenSigTimeoutTime" BU_SG_REL_ Kombi SG_ 1527 RW_Sek_Reichweitenverbrauch 5000;
BA_REL_ "GenSigTimeoutTime" BU_SG_REL_ Kombi SG_ 1527 RW_Sekundaer_Reichweite 5000;
BA_REL_ "GenSigTimeoutTime" BU_SG_REL_ Kombi SG_ 1527 RW_Sekundaer_Reichweite_Anzeige 5000;
BA_REL_ "GenSigTimeoutTime" BU_SG_REL_ Kombi SG_ 1610 RKA_FMVSS138_Lampe 5000;
BA_REL_ "GenSigTimeoutTime" BU_SG_REL_ Kombi SG_ 1610 RKA_FMVSS138_MIL 5000;
BA_REL_ "GenSigTimeoutTime" BU_SG_REL_ Kombi SG_ 1610 RKA_Warnungen_02 5000;
BA_REL_ "GenSigTimeoutTime" BU_SG_REL_ Kombi SG_ 2463978697 AFS_Lampe 800;
BA_REL_ "GenSigTimeoutTime" BU_SG_REL_ Kombi SG_ 2463978697 LWR_Lampe 800;
BA_REL_ "GenSigTimeoutTime" BU_SG_REL_ Kombi SG_ 2463978697 LWR_Reisemodus_Texte 800;
BA_REL_ "GenSigTimeoutTime" BU_SG_REL_ Kombi SG_ 2527679498 Perso_Kontonummer 5000;
BA_REL_ "GenSigTimeoutTime" BU_SG_REL_ Kombi SG_ 2527679498 Perso_Status 5000;
BA_REL_ "GenSigTimeoutTime" BU_SG_REL_ Kombi SG_ 2527679498 Perso_Steuerung 5000;
BA_REL_ "GenSigTimeoutTime" BU_SG_REL_ Kombi SG_ 2527679498 Perso_Steuerungsparameter 5000;
BA_REL_ "GenSigTimeoutTime" BU_SG_REL_ Kombi SG_ 2527679676 RW_Prim_rRWB_Reichw_Anz 5000;
BA_REL_ "GenSigTimeoutTime" BU_SG_REL_ Kombi SG_ 2527679676 RW_Prim_rRWB_Reichw_Gesamt_Anz 5000;
BA_REL_ "GenSigTimeoutTime" BU_SG_REL_ Kombi SG_ 2527679676 RW_Prim_rRWB_Reichw_Max_Ges_Anz 5000;
BA_REL_ "GenSigTimeoutTime" BU_SG_REL_ Kombi SG_ 2527679676 RW_Prim_rRWB_Reichw_Rest_E_Anz 5000;
BA_REL_ "GenSigTimeoutTime" BU_SG_REL_ Kombi SG_ 2527679676 RW_Prim_rRWB_aktiv 5000;
BA_REL_ "GenSigTimeoutTime" BU_SG_REL_ Kombi SG_ 2527679676 RW_Prim_statische_Reichw_Anz 5000;
BA_REL_ "GenSigTimeoutTime" BU_SG_REL_ Kombi SG_ 2527679742 Kam_Anf_Meldung 1000;
BA_REL_ "GenSigTimeoutTime" BU_SG_REL_ Kombi SG_ 2527679748 TPMS_WarnLmpStMil 2000;
BA_REL_ "GenSigTimeoutTime" BU_SG_REL_ Kombi SG_ 2527679748 TPMS_WarnLmpStP 2000;
BA_REL_ "GenSigTimeoutTime" BU_SG_REL_ SmartLight_01 SG_ 1440 LS_Helligkeit_FW 2000;
BA_REL_ "GenSigTimeoutTime" BU_SG_REL_ SmartLight_01 SG_ 1440 LS_Helligkeit_IR 2000;
BA_REL_ "GenSigTimeoutTime" BU_SG_REL_ SmartLight_01 SG_ 1440 LS_defekt 2000;
BA_REL_ "GenSigTimeoutTime" BU_SG_REL_ SmartLight_01 SG_ 1440 RLS_Vorfeldhelligkeit_Boost 2000;
BA_REL_ "GenSigTimeoutTime" BU_SG_REL_ SmartLight_01 SG_ 2527679669 LS_Autobahnfahrlicht 800;
BA_REL_ "GenSigTimeoutTime" BU_SG_REL_ SmartLight_01 SG_ 2527679669 LS_Dunkel 800;
BA_REL_ "GenSigTimeoutTime" BU_SG_REL_ SmartLight_01 SG_ 2527679669 LS_Error 800;
BA_REL_ "GenSigTimeoutTime" BU_SG_REL_ SmartLight_01 SG_ 2527679669 LS_Helligkeit_FW 800;
BA_REL_ "GenSigTimeoutTime" BU_SG_REL_ SmartLight_01 SG_ 2527679669 LS_Helligkeit_IR 800;
BA_REL_ "GenSigTimeoutTime" BU_SG_REL_ SmartLight_01 SG_ 2527679669 LS_Licht_ein 800;
BA_REL_ "GenSigTimeoutTime" BU_SG_REL_ SmartLight_01 SG_ 2527679669 LS_Licht_ein_invers 800;
BA_REL_ "GenSigTimeoutTime" BU_SG_REL_ SmartLight_01 SG_ 2527679669 RLS_Qualifizierungsbit 800;
BA_REL_ "GenSigTimeoutTime" BU_SG_REL_ SmartLight_01 SG_ 2527679669 RLS_Vorfeldhelligkeit_Boost 800;
BA_REL_ "GenSigTimeoutTime" BU_SG_REL_ ZR_MIB_TOP_ab_Gen3 SG_ 319 SC_PreCrash_Warnung 2000;
BA_REL_ "GenSigTimeoutTime" BU_SG_REL_ ZR_MIB_TOP_ab_Gen3 SG_ 1175 PH_Anf_Audioabsenkung 1000;
BA_REL_ "GenSigTimeoutTime" BU_SG_REL_ ZR_MIB_TOP_ab_Gen3 SG_ 1355 PH_Ton_Ausgabe 5000;
BA_REL_ "GenSigTimeoutTime" BU_SG_REL_ ZR_MIB_TOP_ab_Gen3 SG_ 1355 PH_Ton_Lautstaerke 5000;
BA_REL_ "GenSigTimeoutTime" BU_SG_REL_ ZR_MIB_TOP_ab_Gen3 SG_ 1355 PH_Ton_Pausenlaenge 5000;
BA_REL_ "GenSigTimeoutTime" BU_SG_REL_ ZR_MIB_TOP_ab_Gen3 SG_ 1355 PH_Ton_Richtung 5000;
BA_REL_ "GenSigTimeoutTime" BU_SG_REL_ ZR_MIB_TOP_ab_Gen3 SG_ 1527 RW_Primaer_Reichweite_Anzeige 5000;
BA_REL_ "GenSigTimeoutTime" BU_SG_REL_ ZR_MIB_TOP_ab_Gen3 SG_ 2527679498 IAA_Active_User_ID 5000;
BA_REL_ "GenSigTimeoutTime" BU_SG_REL_ ZR_MIB_TOP_ab_Gen3 SG_ 2527679498 IAA_Identified_User_ID 5000;
BA_REL_ "GenSigTimeoutTime" BU_SG_REL_ ZR_MIB_TOP_ab_Gen3 SG_ 2527679498 IAA_PSO_wake_up 5000;
BA_REL_ "GenSigTimeoutTime" BU_SG_REL_ ZR_MIB_TOP_ab_Gen3 SG_ 2527679498 Perso_Fahrernummer 5000;
BA_REL_ "GenSigTimeoutTime" BU_SG_REL_ ZR_MIB_TOP_ab_Gen3 SG_ 2527679498 Perso_Freigabe_Verstellung 5000;
BA_REL_ "GenSigTimeoutTime" BU_SG_REL_ ZR_MIB_TOP_ab_Gen3 SG_ 2527679498 Perso_Kontonummer 5000;
BA_REL_ "GenSigTimeoutTime" BU_SG_REL_ ZR_MIB_TOP_ab_Gen3 SG_ 2527679498 Perso_Status 5000;
BA_REL_ "GenSigTimeoutTime" BU_SG_REL_ ZR_MIB_TOP_ab_Gen3 SG_ 2527679498 Perso_Steuerung 5000;
BA_REL_ "GenSigTimeoutTime" BU_SG_REL_ ZR_MIB_TOP_ab_Gen3 SG_ 2527679498 Perso_Steuerungsparameter 5000;
BA_REL_ "GenSigTimeoutTime" BU_SG_REL_ ZR_MIB_TOP_ab_Gen3 SG_ 2527679676 RW_Prim_rRWB_Reichw_Gesamt_Anz 5000;
BA_REL_ "GenSigTimeoutTime" BU_SG_REL_ ZR_MIB_TOP_ab_Gen3 SG_ 2527679676 RW_Prim_rRWB_aktiv 5000;
VAL_ 1175 PDC_Tonausgabe_Front 0 "kein_Ton" 1 "Intervallton_1" 2 "Intervallton_2" 3 "Intervallton_3" 4 "Intervallton_4" 5 "Intervallton_5" 6 "Dauerton" 7 "Fehlerton" 8 "RCTATon" ;
VAL_ 1175 PDC_Tonausgabe_Heck 0 "kein_Ton" 1 "Intervallton_1" 2 "Intervallton_2" 3 "Intervallton_3" 4 "Intervallton_4" 5 "Intervallton_5" 6 "Dauerton" 7 "Fehlerton" 8 "Erstwarnton_hinten" 9 "RCTATon" ;
VAL_ 1175 PH_Abschaltursache 0 "keine, bzw. System aktiv" 1 "Abschaltung durch Herausnahme R-Gang" 2 "Abschaltung ueber Geschwindigkeit" 3 "Abschaltung ueber PDC-Taster" 4 "Abschaltung wegen PLA" 5 "Abschaltung durch KL 15 Bit = 0" 6 "tbd." 7 "Fehler-/gestï?½rt Zustand, System noch aktiv" ;
VAL_ 1175 PH_Anf_Audioabsenkung 0 "Keine_Audioabsenkung" 1 "Anforderung_Audioabsenkung" ;
VAL_ 1175 PH_Anf_Verdeck 0 "Verdeckbetrieb_freigegeben" 1 "Verdeckbetrieb_sperren" 2 "reserviert" 3 "reserviert" ;
VAL_ 1175 PH_defekt 0 "PH aktiv" 1 "PH wurde aufgrund eines Defektes deaktiviert" ;
VAL_ 1175 PH_Display_Kundenwunsch 0 "Anzeige aus" 1 "Grafik" 2 "Rear View" 3 "automatisch" ;
VAL_ 1175 PH_gestoert 0 "PH aktiv" 1 "PH wurde auf Grund einer Stoerung tempraer deaktiviert" ;
VAL_ 1175 PH_nachtr_Stopp_Anf 0 "nicht_angefordert" 1 "angefordert" ;
VAL_ 1175 PH_Opt_Anz_H_Hindernis 0 "optische Anzeige hinten meldet kein Hindernis" 1 "optische Anzeige hinten meldet Hindernis im Warnbereich" ;
VAL_ 1175 PH_Opt_Anz_V_Hindernis 0 "optische Anzeige vorne meldet kein Hindernis" 1 "optische Anzeige vorne meldet Hindernis im Warnbereich" ;
VAL_ 1175 PH_Opt_Anzeige_H_ein 0 "Optische Anzeige aus" 1 "optische Anzeige hinten aktiviert" ;
VAL_ 1175 PH_Opt_Anzeige_V_ein 0 "optische Anzeige vorne nicht aktiv" 1 "optische Anzeige vorne aktiviert" ;
VAL_ 1175 PH_StartStopp_Info 0 "Motorlauf_nicht_notwendig_(Stoppfreigabe)" 1 "Motoranlauf_nicht_zwingend_notwendig_(Stoppverbot,keine_Startanforderung)" 2 "Motoranlauf_zwingend_notwendig_(Startanforderung)" 3 "Systemfehler" ;
VAL_ 1175 PH_Stoermeldung 0 "keine_Anzeige_kein_Gong" 1 "Textmeldung_PDC_hinten_gestoert_mit_Gong" 2 "Textmeldung_PDC_hinten_gestoert_ohne_Gong" 3 "Textmeldung_PDC_vorn_gestoert_mit_Gong" 4 "Textmeldung_PDC_vorn_gestoert_ohne_Gong" 5 "Textmeldung_PDC_gestoert_mit_Gong" 6 "Textmeldung_PDC_gestoert_ohne_Gong" 7 "Textmeldung_PDC_seitlich_gestoert_mit_Gong" 8 "Textmeldung_PDC_seitlich_gestoert_ohne_Gong" ;
VAL_ 1175 PH_Systemzustand 0 "Anlage aus" 1 "Anlage durch einlegen R-Gang aktiviert" 2 "Anlage manuell durch Taster aktiviert" 3 "Anlage automatisch aktiviert" 4 "Anlage durch ARA aktiviert" 6 "Init - Initialisierungsphase nach Kl. 15 ein / Reset" 7 "Fehler-/gestï?½rt Zustand, System noch aktiv" ;
VAL_ 1175 PH_Taster 0 "Taster_nicht_gedrueckt" 1 "Taster_gedrueckt" 2 "reserviert" 3 "Fehler" ;
VAL_ 1175 PH_Tongeber_H_aktiv 0 "Tongeber hinten nicht aktiv" 1 "Tongeber hinten aktiv" ;
VAL_ 1175 PH_Tongeber_H_verfuegbar 0 "nicht verfï?½gbar" 1 "verfï?½gbar" ;
VAL_ 1175 PH_Tongeber_mute 0 "Tongeber nicht stummgeschaltet" 1 "Tongeber stummgeschaltet" ;
VAL_ 1175 PH_Tongeber_V_aktiv 0 "Tongeber vorne nicht aktiv" 1 "Tongeber vorne aktiv" ;
VAL_ 1175 PH_Visualisierung 0 "Aus" 1 "Angefragt" 2 "InAnzeige" 3 "Abgefordert" 6 "Init" 7 "Fehler" ;
VAL_ 1175 PLA_Anf_Aufschaltung_RVC 0 "Keine_RVC_Aufschalteanf" 1 "RVC_Aufschalteanforderung" ;
VAL_ 1355 APS_PaCo_WarningTones 0 "Not_Possible" 1 "Possible" ;
VAL_ 1355 APSOPS_PaCo_ApproachingFront 0 "No_Obstacle_Approaching" 1 "Obstacle_Approaching" ;
VAL_ 1355 APSOPS_PaCo_ApproachingRear 0 "No_Obstacle_Approaching" 1 "Obstacle_Approaching" ;
VAL_ 1355 APSOPS_PaCo_Button 0 "Init_or_not_equipped" 1 "Button_not_pressed" 2 "Button_pressed_debounced" 3 "Error" ;
VAL_ 1355 APSOPS_PaCo_FunctionState 0 "No_Error" 1 "Sensor_Defect" 2 "Sensor_Contaminated" ;
VAL_ 1355 APSOPS_PaCo_MainState 0 "Init" 1 "InOperation_NoError" 7 "Fehler" ;
VAL_ 1355 APSOPS_PaCo_ObstacleDetectFront 0 "None" 1 "LongDistance_OutsideDriveTube" 2 "LongDistance_InsideDriveTube" 3 "ShortDistance_OutsideDriveTube" 4 "ShortDistance_InsideDriveTube" ;
VAL_ 1355 APSOPS_PaCo_ObstacleDetectRear 0 "None" 1 "LongDistance_OutsideDriveTube" 2 "LongDistance_InsideDriveTube" 3 "ShortDistance_OutsideDriveTube" 4 "ShortDistance_InsideDriveTube" ;
VAL_ 1355 PH_Aufschaltursache 0 "Anlage aus" 1 "Anlage durch einlegen R-Gang aktiviert" 2 "Anlage manuell durch Taster aktiviert" 3 "Anlage automatisch aktiviert" 4 "Anlage durch ARA aktiviert" 5 "Rueckwaertsrollen" 6 "Anlage_durch_PLA_aktiviert" 7 "Anlage_durch_IPA_aktiviert" 8 "Anlage_durch_FA_aktiviert" 9 "Anlage_durch_RBF_oder_MA_aktiviert" 10 "Anlage_durch_Smartphone_aktiviert" 11 "Anlage_durch_Jokertaste_aktiviert" 12 "Anlage_durch_Favoritentasten_aktiviert" 13 "Anlage_durch_SideViewTaster_aktiviert" 14 "Anlage_durch_RCTA_aktiviert" 15 "Anlage_durch_KAS_aktiviert" 16 "Anlage_durch_AWC_aktiviert" 30 "Init_Initialisierungsphase_nach_Kl_15_ein_oder_Reset" 31 "Fehler_gestoerter_Zustand_System_noch_aktiv" ;
VAL_ 1355 PH_Ton_Ausgabe 0 "Init" 1 "Intervallton_vorne" 2 "Intervallton_hinten" 3 "Dauerton_vorne" 4 "Dauerton_hinten" 5 "Quittierungston" 6 "Reserviert" 7 "Fehler" ;
VAL_ 1355 PH_Ton_Lautstaerke 0 "Minimallautstaerke" 1 "Lautstaerke_1" 2 "Lautstaerke_2" 3 "Lautstaerke_3" 4 "Lautstaerke_4" 5 "Lautstaerke_5" 6 "Lautstaerke_6" 7 "Maximallautstaerke" ;
VAL_ 1355 PH_Ton_Pausenlaenge 0 "Init" 1 "Pause_5ms" 2 "Pause_10ms" 3 "Pause_15ms" 100 "Pause_500ms" 101 "Reserviert" 126 "Reserviert" 127 "Fehler" ;
VAL_ 1355 PH_Ton_Richtung 0 "vorne" 1 "vorne_rechts" 2 "rechts" 3 "rechts_hinten" 4 "hinten" 5 "hinten_links" 6 "links" 7 "vorne_links" ;
VAL_ 1355 PH_Verschmutzungsmeldung 0 "keine_Anzeige_kein_Gong" 1 "Textmeldung_PDC_hinten_verschmutzt_mit_Gong" 2 "Textmeldung_PDC_hinten_verschmutzt_ohne_Gong" 3 "Textmeldung_PDC_vorn_verschmutzt_mit_Gong" 4 "Textmeldung_PDC_vorn_verschmutzt_ohne_Gong" 5 "Textmeldung_PDC_verschmutzt_mit_Gong" 6 "Textmeldung_PDC_verschmutzt_ohne_Gong" 7 "Textmeldung_PDC_seitlich_verschmutzt_mit_Gong" 8 "Textmeldung_PDC_seitlich_verschmutzt_ohne_Gong" ;
VAL_ 1355 PH_WAH_Meldung 0 "Init" 1 "Fehlermeldung_bei_Nichtverfuegbarkeit_mit_Gong" 2 "Fehlermeldung_bei_Nichtverfuegbarkeit_ohne_Gong" 3 "Anzeige_dass_Fahrzeug_erkannt_wurde_und_Funktion_aktiv_ist" 4 "Wiederanfahrhinweis_mit_Gong" 5 "Wiederanfahrhinweis_ohne_Gong" ;
VAL_ 1355 RBF_Anf_Meldungen 0 "Init" 1 "RBF_eingeschraenkt_Sensorsicht" 2 "RBF_eingeschraenkt_Reinigung" 3 "RBF_nicht_verfuegbar" 4 "RBF_Notbremsung" 5 "RBF_zurzeit_eingeschraenkt" 6 "RBF_eingeschraenkt_reinigen" ;
VAL_ 1355 RBF_PaCo_Anf_Meldungen 0 "Init" 1 "RBF_eingeschraenkt_Sensorsicht" 2 "RBF_eingeschraenkt_Reinigung" 3 "RBF_nicht_verfuegbar" 4 "RBF_Notbremsung" 5 "RBF_zurzeit_eingeschraenkt" 6 "RBF_eingeschraenkt_reinigen" ;
VAL_ 1355 RBFMA_PaCo_BrakeIntervention 0 "Inactive" 1 "Active_Rear" 2 "Active_Front" 3 "Active_Left" 4 "Active_Right" ;
VAL_ 1355 RBFMA_PaCo_MainState 0 "Init" 1 "InOperation_NoError" 2 "Eingeschraenkt" 7 "Fehler" ;
VAL_ 2527679498 IAA_PSO_wake_up 0 "wake_up_inactive" 1 "wake_up_active" ;
VAL_ 2527679498 Perso_Aktiv 0 "deaktiviert" 1 "aktiviert" ;
VAL_ 2527679498 Perso_Bedienstelle 0 "Init" 1 "Kombiinstrument" 2 "ABT" ;
VAL_ 2527679498 Perso_Fahrernummer 0 "kein_Fahrer" 1 "Fahrer_1" 2 "Fahrer_2" 3 "Fahrer_3" 4 "Fahrer_4" 5 "Fahrer_5" 6 "Fahrer_6" 7 "Fahrer_7" ;
VAL_ 2527679498 Perso_Freigabe_Verstellung 0 "Init" 1 "freigegeben" ;
VAL_ 2527679498 Perso_Kontonummer 0 "kein_Benutzerkonto" 1 "Benutzerkonto_1" 2 "Benutzerkonto_2" 3 "Benutzerkonto_3" 4 "Benutzerkonto_4" 5 "Benutzerkonto_5" 6 "Benutzerkonto_6" 7 "Benutzerkonto_7" ;
VAL_ 2527679498 Perso_Schreibschutz 0 "Schreibschutz_deaktiviert" 1 "Schreibschutz_aktiviert" ;
VAL_ 2527679498 Perso_Status 0 "deaktiviert" 1 "PSO_1x_aktiviert" 2 "PSO_2x_aktiviert" ;
VAL_ 2527679498 Perso_Steuerung 0 "keine_Steuerung" 1 "Reset_alle_Konten" 2 "Reset_aktives_Konto" 3 "Kopiere_aktives_Konto_nach" 4 "Wiederherstellen_aktives_Konto" 5 "Aktivieren_aktives_Konto" 6 "Reset_Konto" 7 "Reset_alle_Fahrer" 8 "Reset_aktiver_Fahrer" 9 "Reset_Fahrer" ;
VAL_ 2527679498 Perso_Steuerungsparameter 0 "kein_Parameter" 1 "Benutzerkonto_1" 2 "Benutzerkonto_2" 3 "Benutzerkonto_3" 4 "Benutzerkonto_4" 5 "Benutzerkonto_5" 6 "Benutzerkonto_6" 7 "Benutzerkonto_7" ;
VAL_ 319 PreCrash_Anforderung_AFR 0 "keine_Anforderung" 1 "linke_Seite" 2 "rechte_Seite" 3 "Vorderachse" 4 "Hinterachse" 5 "Vorwarnung" 7 "Init" ;
VAL_ 319 PreCrash_BFS_KSV_verfahren 0 "keine_Anforderung" 1 "in_pos_xRichtung_verfahren" 2 "in_neg_xRichung_verfahren" 3 "in_pos_zRichtung_verfahren" 4 "in_neg_zRichtung_verfahren" 5 "in_pos_xRichtung_und_neg_zRichtung_verfahren" 6 "in_pos_x_Richtung_und_pos_zRichtung_verfahren" 7 "in_neg_xRichtung_und_neg_zRichtung_verfahren" 8 "in_neg_xRichtung_und_pos_zRichtung_verfahren" 9 "Kopfstuetze_ansteuern" ;
VAL_ 319 PreCrash_BFS_Laengsverstellung 0 "nicht_angefordert" 1 "angefordert" ;
VAL_ 319 PreCrash_BFS_Pneumatik_ansteuern 0 "keine_Anforderung" 1 "Pneumatik_ansteuern" ;
VAL_ 319 PreCrash_BFS_Sitzlehne_verfahren 0 "keine_Anforderung" 1 "reserviert" 2 "reserviert" 3 "Sitzlehnenkopf_in_pos_xRichtung_verfahrenvor" 4 "Sitzlehnenkopf_in_neg_xRichtung_verfahrenzurueck" 6 "reserviert" 7 "Lehnenkopfverstellung_ansteuern" ;
VAL_ 319 PreCrash_Blinken 0 "keine_Blinkanforderung" 1 "Warnblinken" 2 "RECAS_Blinken" 3 "Notbremsblinken" ;
VAL_ 319 PreCrash_Charisma_FahrPr 0 "keine_Funktion" 1 "Programm_1" 2 "Programm_2" 3 "Programm_3" 4 "Programm_4" 5 "Programm_5" 6 "Programm_6" 7 "Programm_7" 8 "Programm_8" 9 "Programm_9" 10 "Programm_10" 11 "Programm_11" 12 "Programm_12" 13 "Programm_13" 14 "Programm_14" 15 "Programm_15" ;
VAL_ 319 PreCrash_Charisma_Status 0 "Init" 1 "verfuegbar" 2 "nicht_verfuegbar" 3 "asynchron_durch_Fahrerwunsch" ;
VAL_ 319 PreCrash_Fenster_schliessen 0 "keine_Schliessung" 1 "Schliessung_angefordert" ;
VAL_ 319 PreCrash_Fo_KSV_verfahren 0 "keine_Anforderung" 1 "in_pos_xRichtung_verfahren" 2 "in_neg_xRichung_verfahren" 3 "in_pos_zRichtung_verfahren" 4 "in_neg_zRichtung_verfahren" 5 "in_pos_xRichtung_und_neg_zRichtung_verfahren" 6 "in_pos_x_Richtung_und_pos_zRichtung_verfahren" 7 "in_neg_xRichtung_und_neg_zRichtung_verfahren" 8 "in_neg_xRichtung_und_pos_zRichtung_verfahren" ;
VAL_ 319 PreCrash_Fo_Pneumatik_ansteuern 0 "keine_Anforderung" 1 "Pneumatik_ansteuern" ;
VAL_ 319 PreCrash_Fo_Sitzlehne_verfahren 0 "keine_Anforderung" 1 "reserviert" 2 "reserviert" 3 "Sitzlehnenkopf_in_pos_xRichtung_verfahrenvor" 4 "Sitzlehnenkopf_in_neg_xRichtung_verfahrenzurueck" ;
VAL_ 319 PreCrash_FS_KSV_verfahren 0 "keine_Anforderung" 1 "in_pos_xRichtung_verfahren" 2 "in_neg_xRichung_verfahren" 3 "in_pos_zRichtung_verfahren" 4 "in_neg_zRichtung_verfahren" 5 "in_pos_xRichtung_und_neg_zRichtung_verfahren" 6 "in_pos_x_Richtung_und_pos_zRichtung_verfahren" 7 "in_neg_xRichtung_und_neg_zRichtung_verfahren" 8 "in_neg_xRichtung_und_pos_zRichtung_verfahren" 9 "Kopfstuetze_ansteuern" ;
VAL_ 319 PreCrash_FS_Laengsverstellung 0 "nicht_angefordert" 1 "angefordert" ;
VAL_ 319 PreCrash_FS_Pneumatik_ansteuern 0 "keine_Anforderung" 1 "Pneumatik_ansteuern" ;
VAL_ 319 PreCrash_FS_Sitzlehne_verfahren 0 "keine_Anforderung" 1 "reserviert" 2 "reserviert" 3 "Sitzlehnenkopf_in_pos_xRichtung_verfahrenvor" 4 "Sitzlehnenkopf_in_neg_xRichtung_verfahrenzurueck" 6 "reserviert" 7 "Lehnenkopfverstellung_ansteuern" ;
VAL_ 319 PreCrash_Schiebedach_schliessen 0 "keine_Schliessung" 1 "Schliessung_angefordert" ;
VAL_ 319 PreCrash_Tueren_Verriegeln 0 "keine_Anforderung" 1 "Tueren_Verriegeln" ;
VAL_ 319 SC_PreCrash_LED 0 "keine_Anzeige" 1 "Stufe_1_glimmen" 2 "Stufe_2_leuchten" 3 "Stufe_3_blinken" ;
VAL_ 319 SC_PreCrash_Texte 0 "keine_Anzeige" 1 "Systemstoerung" 2 "keine_Sensorsicht" 3 "Demomodus" 4 "System_aus" 5 "Anhaengerbetrieb" 6 "ESC_aus" 7 "zurzeit_eingeschraenkt" 8 "zurzeit_eingeschraenkt_ESP_Aus" 9 "Initialisierung" ;
VAL_ 319 SC_PreCrash_Warnung 0 "keine_Anzeige" 1 "latente_Vorwarnung" 2 "Vorwarnung" 3 "Akutwarnung" 4 "Eingriff" 5 "Fahreruebernahmeaufforderung" 6 "Abbiegewarnung" 7 "Basiseingriff" 8 "Heckeingriff" ;
VAL_ 319 SC_PreSense_FCWP 0 "Warnung_gilt_fuer_Objekte" 1 "Warnung_gitl_fuer_Fussgaenger" ;
VAL_ 1122 PSD_Abzweigerichtung 0 "rects_abzweigende_Strasse" 1 "links_abzweigende_Strasse" ;
VAL_ 1122 PSD_ADAS_Qualitaet 0 "keine_ADAS_Qualitaet" 1 "ADAS_Qualitaet" ;
VAL_ 1122 PSD_Anfangskruemmung 255 "Gerade" ;
VAL_ 1122 PSD_Anfangskruemmung_Vorz 0 "positiv" 1 "negativ" ;
VAL_ 1122 PSD_Bebauung 0 "ausserhalb_bebauten_Gebietes" 1 "innerhalb_bebauten_Gebietes" ;
VAL_ 1122 PSD_Endkruemmung 255 "Gerade" ;
VAL_ 1122 PSD_Endkruemmung_Vorz 0 "Kruemmung_positiv" 1 "Kruemmung_negativ" ;
VAL_ 1122 PSD_Fahrspuren_Anzahl 0 "Einbahnstrasse_in_falsche_Richtung" 1 "eine_Fahrspur" 2 "zwei_Fahrspuren" 3 "drei_Fahrspuren" 4 "vier_Fahrspuren" 5 "fuenf_Fahrspuren" 6 "sechs_Fahrspuren" 7 "mehr_als_sechs_Fahrspuren" ;
VAL_ 1122 PSD_Geradester_Pfad 0 "nicht_geradester_PFad" 1 "geradester_Pfad" ;
VAL_ 1122 PSD_Idenditaets_ID 0 "keine_Segment_Informationen_vorhanden" 1 "Fehler" ;
VAL_ 1122 PSD_Rampe 0 "Strasse_mit_Gegenverkehr" 1 "Auffahrt_Einbahnstr" 2 "Abfahrt_Einbahnstr" 3 "Einbahnstrasse" ;
VAL_ 1122 PSD_Segment_ID 0 "keine Segmentinformationen vorhanden" 1 "Fehlerwert" ;
VAL_ 1122 PSD_Segment_Komplett 0 "Segment_Attribute_nicht_komplett" 1 "Segment_Attribute_komplett" ;
VAL_ 1122 PSD_Strassenkategorie 0 "Rest_Feldweg_Schotterweg_Privatweg" 1 "Ortsstraï?½e" 2 "Kreisstraï?½e" 3 "Landstraï?½e" 4 "Bundesstraï?½e" 5 "Autobahn" 7 "Init" ;
VAL_ 1122 PSD_Vorgaenger_Segment_ID 0 "keine Segmentinformation vorhanden" 1 "Fehlerwert" ;
VAL_ 1122 PSD_wahrscheinlichster_Pfad 0 "Pfad_mit_geringer_Wahrscheinlichkeit" 1 "wahrscheinlichster_Pfad" ;
VAL_ 1123 PSD_Attribut_1_ID 0 "keine_Information" ;
VAL_ 1123 PSD_Attribut_2_ID 0 "keine_Information" ;
VAL_ 1123 PSD_Attribut_Segment_ID_05 0 "keine_Segment_Information" 1 "Fehler" ;
VAL_ 1123 PSD_Attribute_Komplett_05 0 "Attribute_nicht_komplett" 1 "Attribute_komplett" ;
VAL_ 1123 PSD_Pos_Fahrspur 0 "unbekannt" 1 "Erste_Spur_von_rechts" 2 "Zweite_Spur_von_rechts" 3 "Dritte_Spur_von_rechts" 4 "Vierte_Spur_von_rechts" 5 "Fuenfte_Spur_von_rechts" 6 "Sechte_Spur_von_rechts" 7 "Siebte_oder_weitere_Spur_von_rechts" ;
VAL_ 1123 PSD_Pos_Fehler_Laengsrichtung 0 "Init" 1 "< 2m" 2 "< 5m" 3 "< 10m" 4 "< 20m" 5 "< 50m" 6 "> 50m" 7 "Off-Road" ;
VAL_ 1123 PSD_Pos_Segment_ID 0 "keine Position gegeben" 1 "Fehlerwert" ;
VAL_ 1123 PSD_Pos_Standort_Eindeutig 0 "mehrdeutiger_Standort" 1 "eindeutiger_Standort" ;
VAL_ 1124 PSD_06_Mux 0 "Init" ;
VAL_ 1124 PSD_Attribut_3_ID 0 "keine_Information" ;
VAL_ 1124 PSD_Attribut_4_ID 0 "keine_Information" ;
VAL_ 1124 PSD_Attribut_5_ID 0 "keine_Information" ;
VAL_ 1124 PSD_Attribut_Segment_ID 0 "keine_Segment_Information_vorhanden" 1 "Fehler" ;
VAL_ 1124 PSD_Attribute_Komplett_06 0 "Attribute_nicht_komplett" 1 "Attribute_komplett" ;
VAL_ 1124 PSD_Baum_Breite_VZ 0 "Nord" 1 "Sued" ;
VAL_ 1124 PSD_Baum_Laenge 33554431 "keine_GPS_Information" ;
VAL_ 1124 PSD_Baum_Laenge_VZ 0 "Ost" 1 "West" ;
VAL_ 1124 PSD_Ges_Attribute_Komplett 0 "Attribute_nicht_komplett" 1 "Attribute_komplett" ;
VAL_ 1124 PSD_Ges_Geschwindigkeit 0 "Kein Geschwindigkeitsgebot" 1 "0 km/h < v_max < 5 km/h" 2 "5 km/h < v_max < 10km/h" 3 "10 km/h < v_max < 15 km/h" 4 "15 km/h < v_max < 20 km/h" 5 "20 km/h < v_max < 25 km/h" 6 "25 km/h < v_max < 30 km/h" 7 "30 km/h < v_max < 35 km/h" 8 "35 km/h < v_max < 40 km/h" 9 "40 km/h < v_max < 45 km/h" 10 "45 km/h < v_max < 50 km/h" 11 "50 km/h < v_max < 60 km/h" 12 "60 km/h < v_max < 70 km/h" 13 "70 km/h < v_max < 80 km/h" 14 "80 km/h < v_max < 90 km/h" 15 "90 km/h < v_max < 100 km/h" 16 "100 km/h < v_max < 110 km/h" 17 "110 km/h < v_max < 120 km/h" 18 "" ;
VAL_ 1124 PSD_Ges_Geschwindigkeit_Gespann 0 "alle Fahrzeuge" 1 "PKW mit Gespann" 2 "LKW, Busse, etc." ;
VAL_ 1124 PSD_Ges_Geschwindigkeit_Std_Anf 25 "kein Beginn fï?½r stundenweise Einschrï?½nkungen" ;
VAL_ 1124 PSD_Ges_Geschwindigkeit_Std_Ende 25 "kein Ende fï?½r stundenweise Einschrï?½nkungen" ;
VAL_ 1124 PSD_Ges_Geschwindigkeit_Tag_Anf 0 "kein Beginn definiert" 1 "Montag" 2 "Dienstag" 3 "Mittwoch" 4 "Donnerstag" 5 "Freitag" 6 "Samstag" 7 "Sonntag" ;
VAL_ 1124 PSD_Ges_Geschwindigkeit_Tag_Ende 0 "kein Ende definiert" 1 "Montag" 2 "Dienstag" 3 "Mittwoch" 4 "Donnerstag" 5 "Freitag" 6 "Samstag" 7 "Sonntag" ;
VAL_ 1124 PSD_Ges_Geschwindigkeit_Witter 0 "Witterungsunabhï?½ngig" 1 "Nï?½sse, Regen, Niederschlag" 2 "Glï?½tte" 3 "Nebel" ;
VAL_ 1124 PSD_Ges_Gesetzlich_Kategorie 0 "kein_legales_Verbot" 1 "innerorts" 2 "ausserorts" 3 "Autobahn" ;
VAL_ 1124 PSD_Ges_Gesetzlich_Zusatz 0 "kein_Zusatz_zu_legalem_Gebot" 1 "Anhaenger_Klasse_1" 2 "Anhaenger_Klasse_2" ;
VAL_ 1124 PSD_Ges_Segment_ID 0 "keine Segmentinformationen vorhanden" 1 "nicht zulaessig" ;
VAL_ 1124 PSD_Ges_Spur_Geschw_Begrenzung 0 "Gebot_fuer_alle_spuren_gueltig" ;
VAL_ 1124 PSD_Ges_Typ 0 "Geschw_Klasse_des_Kartendatensuppliers" 1 "Explizit_abgeleiteten_Begrenzung" 2 "Durch_Gesetzg_vorgeg_allgem_Gebot_fuer_uebertr_Rahmenbed" 3 "Init" ;
VAL_ 1124 PSD_Ges_Ueberholverbot 0 "kein ï?½berholverbot" 1 "alle Fahrzeuge" 2 "ï?½berholverbot fï?½r PKW mit Gespann" 3 "ï?½berholverbot fï?½r LKW, Busse, etc." ;
VAL_ 1124 PSD_Ges_Verkehrszeichen_Quelle 0 "VZA_kein_Onlinedienst" 1 "nur_VZA" 2 "nur_VZO" 3 "VZA_und_VZO" ;
VAL_ 1124 PSD_Ges_Wechselverkehrszeichen 0 "Kein Wechselverkehrszeichen" 1 "Wechselverkehrszeichen links" 2 "Wechselverkehrszeichen rechts" 3 "Wechselverkehrszeichen links und rechts" 4 "Wechselverkerhszeichen ï?½ber der Fahrbahn" ;
VAL_ 1124 PSD_Steigung_1_A_Steigung 126 "mehr_als_15_Prozent" 127 "Steigung_unbekannt" ;
VAL_ 1124 PSD_Steigung_1_A_Vorz 0 "Gefaelle" 1 "Steigung" ;
VAL_ 1124 PSD_Steigung_1_Attribute_kompl 0 "Steigungen_nicht_komplett" 1 "Steigungen_komplett" ;
VAL_ 1124 PSD_Steigung_1_B_Steigung 126 "mehr_als_15_Prozent" 127 "Steigung_unbekannt" ;
VAL_ 1124 PSD_Steigung_1_B_Vorz 0 "Gefaelle" 1 "Steigung" ;
VAL_ 1124 PSD_Steigung_1_Segment_ID 0 "keine_Segment_Information_vorhanden" 1 "Fehler" ;
VAL_ 1124 PSD_Steigung_2_Attribute_kompl 0 "Steigungen_nicht_komplett" 1 "Steigungen_komplett" ;
VAL_ 1124 PSD_Steigung_2_Segment_ID 0 "keine_Segment_Information_vorhanden" 1 "Fehler" ;
VAL_ 1124 PSD_Steigung_2_Steigung 126 "mehr_als_15_Prozent" 127 "Steigung_unbekannt" ;
VAL_ 1124 PSD_Steigung_2_Vorz 0 "Gefaelle" 1 "Steigung" ;
VAL_ 1124 PSD_Sys_Alter_Karte 0 "kleiner_1_Jahr" 1 "1_Jahr" 2 "2_Jahre" 3 "3_Jahre" 4 "4_Jahre" 5 "5_Jahre" 6 "6_Jahre" 7 "groesser_7_Jahre" ;
VAL_ 1124 PSD_Sys_Geometrieguete 0 "Geringe_Guete" 1 "tbd" 2 "tbd" 3 "Hohe_Guete" ;
VAL_ 1124 PSD_Sys_Geometrieguete_erweitert 0 "Init" ;
VAL_ 1124 PSD_Sys_Geschwindigkeit_Einheit 0 "km/h" 1 "mph" ;
VAL_ 1124 PSD_Sys_Mapmatchingguete 0 "geringe_Guete" 1 "res" 2 "res" 3 "hohe_Guete" ;
VAL_ 1124 PSD_Sys_Quali_verfuegbar 0 "Qualitaetskriterien_nicht_verfuegbar" 1 "Qualitaetskriterien_verfuegbar" ;
VAL_ 1124 PSD_Sys_Segment_ID 0 "keine Segmentinformationen vorhanden" 1 "nicht zulaessig" ;
VAL_ 1124 PSD_Sys_US_State 0 "kein_US_State" 1 "Alabama" 2 "Alaska" 3 "Arkansas" 4 "Arizona" 5 "California" 6 "Colorado" 7 "Conneticut" 8 "District_of_Columbia" 9 "Delaware" 10 "Florida" 11 "Georgia" 12 "Hawaii" 13 "Idaho" 14 "Illinois" 15 "Iowa" 16 "Indiana" 17 "Kansas" 18 "Kentucky" 19 "Louisiana" 20 "Massachusetts" 21 "Maryland" 22 "Maine" 23 "Michigan" 24 "Minnesota" 25 "Missouri" 26 "Mississippi" 27 "Montana" 28 "North_Carolina" 29 "North_Dakota" 30 "Nebraska" 31 "Nevada" 32 "New_Hampshire" 33 "New_Jersey" 34 "New_Mexico" 35 "New_York" 36 "Ohio" 37 "Oklahoma" 38 "Oregon" 39 "Pennsylvania" 40 "Puerto_Rico" 41 "Rhode_Island" 42 "South_Carolina" 43 "South_Dakota" 44 "Tennessee" 45 "Texas" 46 "Utah" 47 "Virginia" 48 "Virgin_Islands" 49 "Vermont" 50 "Washington" 51 "Wisconsin" 52 "West_Virginia" 53 "Wyoming" ;
VAL_ 1124 PSD_Sys_Verkehrsrichtung 0 "Rechtsverkehr" 1 "Linksverkehr" ;
VAL_ 1124 PSD_Sys_Zielfuehrung 0 "Zielfuehrung nicht aktiv" 1 "Zielfuehrung aktiv" ;
VAL_ 1124 PSD_Sys_Zielfuehrung_geaendert 0 "Zielfuehrung_nicht_geaendert" 1 "Zielfuehrung_geaendert" ;
VAL_ 1124 PSD_Wechselverkehrszeichen_Typ 0 "kein_Wechselverkehrszeichen" 1 "LED_Wechselverkehrszeichen" 2 "nicht_LED_Wechselverkehrszeichen" ;
VAL_ 1125 PSD_LR_01_MUX 0 "Init" ;
VAL_ 1125 PSD_LR_Attribut_1_Wert 0 "Init" ;
VAL_ 1125 PSD_LR_Attribut_2_Wert 0 "Init" ;
VAL_ 1125 PSD_LR_Attribut_3_Wert 0 "Init" ;
VAL_ 1125 PSD_LR_Globale_Steigung_Vorz 0 "Gefaelle" 1 "Steigung" ;
VAL_ 1125 PSD_LR_Reset 0 "kein Reset" 1 "Reset" ;
VAL_ 1125 PSD_LR_Steigung_1_Vorz 0 "Gefaelle" 1 "Steigung" ;
VAL_ 1125 PSD_LR_Steigung_2_Vorz 0 "Gefaelle" 1 "Steigung" ;
VAL_ 1125 PSD_LR_Steigung_3_Vorz 0 "Gefaelle" 1 "Steigung" ;
VAL_ 1616 PRIV_dataextraction_CDIS 0 "Init" 1 "Datenausleitung_aus" 2 "Datenausleitung_an" ;
VAL_ 1616 RA_AM_Tuning 0 "frequency_locked" 1 "AM_tuning" ;
VAL_ 1616 RA_Frequency_unit 0 "1_kHz" 1 "100_kHz" ;
VAL_ 1616 RA_Radio_Error_Flag 0 "kein_KD_Fehler" 1 "KD_Fehler" ;
VAL_ 2527679748 TPMS_CalTyp 0 "TPMS_Table_Calibration" 1 "TPMS_Switch_Calibration" 2 "TPMS_Semiautomatic_Calibration" 3 "Reserved" ;
VAL_ 2527679748 TPMS_disable 0 "unchanged" 1 "disable" ;
VAL_ 2527679748 TPMS_enable 0 "unchanged" 1 "enable" ;
VAL_ 2527679748 TPMS_LearningState 0 "learning_possible" 1 "learning_starts_above_speedlevel" 2 "learning_run" 3 "learning_successfull_allocated" 4 "learning_not_possible" 5 "learning_unsuccessful" 6 "learning_successf_not_allocated" 7 "init" 8 "Fehler" ;
VAL_ 2527679748 TPMS_PDeFrLe 127 "Init" ;
VAL_ 2527679748 TPMS_PDeFrRi 127 "Init" ;
VAL_ 2527679748 TPMS_PDeReLe 127 "Init" ;
VAL_ 2527679748 TPMS_PDeReRi 127 "Init" ;
VAL_ 2527679748 TPMS_RaceTrckMdSts 0 "Race_track_mode_inactive" 1 "Race_track_mode_active" ;
VAL_ 2527679748 TPMS_SensBattStsFrLe 126 "Init" 127 "Fehler" ;
VAL_ 2527679748 TPMS_SensBattStsFrRi 126 "Init" 127 "Fehler" ;
VAL_ 2527679748 TPMS_SensBattStsReLe 126 "Init" 127 "Fehler" ;
VAL_ 2527679748 TPMS_SensBattStsReRi 126 "Init" 127 "Fehler" ;
VAL_ 2527679748 TPMS_SensPFrLe 63 "Init" ;
VAL_ 2527679748 TPMS_SensPFrRi 63 "Init" ;
VAL_ 2527679748 TPMS_SensPReLe 63 "Init" ;
VAL_ 2527679748 TPMS_SensPReRi 63 "Init" ;
VAL_ 2527679748 TPMS_SensSigAgeFrLe 11 "Larger_than_10_minutes" 12 "Reserved" 13 "Reserved" 14 "Init" 15 "Fehler" ;
VAL_ 2527679748 TPMS_SensSigAgeFrRi 11 "Larger_than_10_minutes" 12 "Reserved" 13 "Reserved" 14 "Init" 15 "Fehler" ;
VAL_ 2527679748 TPMS_SensSigAgeReLe 11 "Larger_than_10_minutes" 12 "Reserved" 13 "Reserved" 14 "Init" 15 "Fehler" ;
VAL_ 2527679748 TPMS_SensSigAgeReRi 11 "Larger_than_10_minutes" 12 "Reserved" 13 "Reserved" 14 "Init" 15 "Fehler" ;
VAL_ 2527679748 TPMS_SensStsFrLe 0 "Sensor_is_working" 1 "Sensor_is_faulty" ;
VAL_ 2527679748 TPMS_SensStsFrRi 0 "Sensor_is_working" 1 "Sensor_is_faulty" ;
VAL_ 2527679748 TPMS_SensStsReLe 0 "Sensor_is_working" 1 "Sensor_is_faulty" ;
VAL_ 2527679748 TPMS_SensStsReRi 0 "Sensor_is_working" 1 "Sensor_is_faulty" ;
VAL_ 2527679748 TPMS_SensTFrLe 254 "Init" 255 "Fehler" ;
VAL_ 2527679748 TPMS_SensTFrRi 254 "Init" 255 "Fehler" ;
VAL_ 2527679748 TPMS_SensTReLe 254 "Init" 255 "Fehler" ;
VAL_ 2527679748 TPMS_SensTReRi 254 "Init" 255 "Fehler" ;
VAL_ 2527679748 TPMS_SensTypFrLe 0 "Wheel_electronics" 1 "Tire_sensor" ;
VAL_ 2527679748 TPMS_SensTypFrRi 0 "Wheel_electronics" 1 "Tire_sensors" ;
VAL_ 2527679748 TPMS_SensTypReLe 0 "Wheel_electronics" 1 "Tire_sensor" ;
VAL_ 2527679748 TPMS_SensTypReRi 0 "Wheel_electronics" 1 "Tire_sensor" ;
VAL_ 2527679748 TPMS_TarPTmpDepFrLe 63 "Init" ;
VAL_ 2527679748 TPMS_TarPTmpDepFrRi 63 "Init" ;
VAL_ 2527679748 TPMS_TarPTmpDepReLe 63 "Init" ;
VAL_ 2527679748 TPMS_TarPTmpDepReRi 63 "Init" ;
VAL_ 2527679748 TPMS_Warn1 0 "Warning_inactive" 1 "Warning_active" ;
VAL_ 2527679748 TPMS_Warn1TireFrLe 0 "Warning_inactive" 1 "Warning_active" ;
VAL_ 2527679748 TPMS_Warn1TireFrRi 0 "Warning_inactive" 1 "Warning_active" ;
VAL_ 2527679748 TPMS_Warn1TireReLe 0 "Warning_inactive" 1 "Warning_active" ;
VAL_ 2527679748 TPMS_Warn1TireReRi 0 "Warning_inactive" 1 "Warning_active" ;
VAL_ 2527679748 TPMS_Warn2 0 "Warning_inactive" 1 "Warning_active" ;
VAL_ 2527679748 TPMS_Warn2TireFrLe 0 "Warning_inactive" 1 "Warning_active" ;
VAL_ 2527679748 TPMS_Warn2TireFrRi 0 "Warning_inactive" 1 "Warning_active" ;
VAL_ 2527679748 TPMS_Warn2TireReLe 0 "Warning_inactive" 1 "Warning_active" ;
VAL_ 2527679748 TPMS_Warn2TireReRi 0 "Warning_inactive" 1 "Warning_active" ;
VAL_ 2527679748 TPMS_Warn3 0 "Warning_inactive" 1 "Warning_active" ;
VAL_ 2527679748 TPMS_Warn3TireFrLe 0 "Warning_inactive" 1 "Warning_active" ;
VAL_ 2527679748 TPMS_Warn3TireFrRi 0 "Warning_inactive" 1 "Warning_active" ;
VAL_ 2527679748 TPMS_Warn3TireReLe 0 "Warning_inactive" 1 "Warning_active" ;
VAL_ 2527679748 TPMS_Warn3TireReRi 0 "Warning_inactive" 1 "Warning_active" ;
VAL_ 2527679748 TPMS_Warn4 0 "Warning_inactive" 1 "Warning_active" ;
VAL_ 2527679748 TPMS_Warn4TireFrLe 0 "Warning_inactive" 1 "Warning_active" ;
VAL_ 2527679748 TPMS_Warn4TireFrRi 0 "Warning_inactive" 1 "Warning_active" ;
VAL_ 2527679748 TPMS_Warn4TireReLe 0 "Warning_inactive" 1 "Warning_active" ;
VAL_ 2527679748 TPMS_Warn4TireReRi 0 "Warning_inactive" 1 "Warning_active" ;
VAL_ 2527679748 TPMS_WarnAcoCalOk 0 "Acoustic_Calib_warning_inactive" 1 "Acoustic_Calib_warning_active" ;
VAL_ 2527679748 TPMS_WarnCalOk 0 "Calibration_warning_inactive" 1 "Calibration_warning_active" ;
VAL_ 2527679748 TPMS_WarnCmftP 0 "Warning_comfort_pressure_inactiv" 1 "Warning_comfort_pressure_active" ;
VAL_ 2527679748 TPMS_WarnFltIdc 0 "Warning_Fault_indication_inactiv" 1 "Warning_Fault_indication_active" ;
VAL_ 2527679748 TPMS_WarnFr 0 "Warning_inactive" 1 "Warning_active" ;
VAL_ 2527679748 TPMS_WarnLmpStMil 0 "TPMS_fault_indicator_inactive" 1 "TPMS_fault_indicator_active" ;
VAL_ 2527679748 TPMS_WarnLmpStP 0 "TPMS_Warning_lamp_P_inactive" 1 "TPMS_Warning_lamp_P_active" ;
VAL_ 2527679748 TPMS_WarnMaxV 0 "Warning_maxium_speed_inactive" 1 "Warning_maxium_speed_active" ;
VAL_ 2527679748 TPMS_WarnRaceTrckMdMinP 0 "RaceTrckMd_warn_min_p_inactive" 1 "RaceTrckMd_warn_min_p_active" ;
VAL_ 2527679748 TPMS_WarnRe 0 "Warning_inactive" 1 "Warning_active" ;
VAL_ 2527679748 TPMS_WarnSysLrn 0 "Warning_System_learns_inactive" 1 "Warning_System_learns_active" ;
VAL_ 2527679748 TPMS_WarnTmpFlt 0 "Warning_Temporary_fault_inactive" 1 "Warning_Temporary_fault_active" ;
VAL_ 2527679748 TPMS_WarnWhlChgDet 0 "Warning_wheel_change_detected_in" 1 "Warning_wheel_change_detected_ac" ;
VAL_ 2527679748 TPMS_WhlChgDetFrLe 0 "No_wheel_change_detected" 1 "Wheel_change_detected" ;
VAL_ 2527679748 TPMS_WhlChgDetFrRi 0 "No_wheel_change_detected" 1 "Wheel_change_detected" ;
VAL_ 2527679748 TPMS_WhlChgDetReLe 0 "No_wheel_change_detected" 1 "Wheel_change_detected" ;
VAL_ 2527679748 TPMS_WhlChgDetReRi 0 "No_wheel_change_detected" 1 "Wheel_change_detected" ;
VAL_ 2463978734 VPS_PaCo_Button 0 "Init_or_not_equipped" 1 "Button_not_pressed" 2 "Button_pressed_debounced" 3 "Error" ;
VAL_ 2463978734 VPS_PaCo_CurrentBirdview 0 "NoBirdView" 1 "BirdView_2D" 2 "BirdView_3D" 3 "BirdView_Autoakt" 4 "OPS_only" 5 "TPA_Trajectory" ;
VAL_ 2463978734 VPS_PaCo_CurrentBowl 0 "NoBowl" 1 "Preset_1" 2 "Preset_2" 3 "Preset_3" 4 "Preset_4" 5 "Preset_5" 6 "Preset_6" 7 "Preset_7" 8 "Preset_8" 9 "Preset_9" 10 "Modified" 11 "Preset_AWC" 12 "Preset_IPA" 13 "Preset_ParkingFront" 14 "Preset_ParkingRear" 15 "Preset_RPA" 16 "Preset_CarWash" ;
VAL_ 2463978734 VPS_PaCo_CurrentCarOverlay 0 "noCarOverlay" 1 "normalCarOverlay" 2 "transparentCarOverlay" ;
VAL_ 2463978734 VPS_PaCo_CurrentMode 0 "NoMode" 1 "Parking_Manual" 2 "Parking_Automatic" 3 "Crossing" 4 "BumperFocus" 5 "TrailerAssist_Manual" 6 "SV_Focus_Front" 7 "SV_Focus_Rear" 8 "SV_Focus_All" 9 "Legal" 10 "TrailerAssist_AAA" 11 "TrailerAssist_ARA" 12 "Smartphone" 13 "VirtualView" ;
VAL_ 2463978734 VPS_PaCo_CurrentRVCscreen 0 "NoScreen" 1 "Fullscreen" 2 "SidebySide_Splitscreen" ;
VAL_ 2463978734 VPS_PaCo_CurrentVideoState 0 "Inactive_ImageNotPossible" 1 "Inactive_ImagePossible" 2 "Active_ImageNotPossible" 3 "Active_ImagePossible" ;
VAL_ 2463978734 VPS_PaCo_CurrentView 0 "NoView" 1 "RearView" 2 "FrontView" 3 "SV_Left" 4 "SV_Right" 5 "SV_Both" 6 "BirdView_2D" 7 "BirdView_3D" 8 "VirtualView" ;
VAL_ 2463978734 VPS_PaCo_CurrGraphOverlay 0 "NoGraphic" 1 "IPA" 2 "ARA" 3 "AAA" 4 "TrailerAssist" 5 "AR" 6 "AWC" 7 "Parkbox" 8 "CarWash" 9 "RPA" 10 "TPA_Training" 11 "TPA_AutomatedDriving" 12 "TPA_Remote" 13 "legal" ;
VAL_ 2463978734 VPS_PaCo_MainState 0 "Init" 1 "InOperation_NoError" 7 "Fehler" ;
VAL_ 2527679742 Kam_Anf_Meldung 0 "Init" 1 "RBF_eingeschraenkt_Sensorsicht" 2 "RBF_eingeschraenkt_Reinigung" 3 "RBF_nicht_verfuegbar" 4 "RBF_Notbremsung" 5 "RBF_zurzeit_eingeschraenkt" 6 "RBF_eingeschraenkt_reinigen" ;
VAL_ 2527679742 Kam_PaCo_MainState 0 "Init" 1 "InOperation_NoError" 2 "Eingeschraenkt" 7 "Fehler" ;
VAL_ 1525 RW_Gesamt_Reichweite 2045 "nicht_verbaut" 2046 "Init" 2047 "Fehler" ;
VAL_ 1525 RW_Gesamt_Reichweite_Max_Anzeige 2045 "nicht_verbaut" 2046 "Init" 2047 "Fehler" ;
VAL_ 1525 RW_Prim_Reichweitenv_Einheit 0 "Liter_pro_100km" 1 "kWh_pro_100km" 2 "Kg_pro_100km" 3 "nicht_verbaut" ;
VAL_ 1525 RW_Prim_Reichweitenverbrauch 2047 "Init" ;
VAL_ 1525 RW_Primaer_Reichweite 2045 "nicht_verbaut" 2046 "Init" 2047 "Fehler" ;
VAL_ 1525 RW_Reservewarnung_2_aktiv 0 "Init" 1 "inaktiv" 2 "aktiv" 3 "reserviert" ;
VAL_ 1525 RW_RWDS_Lastprofil 2046 "Init" 2047 "Fehler" ;
VAL_ 1527 RW_Gesamt_Reichweite_Anzeige 2045 "nicht_verbaut" 2046 "Init" 2047 "Fehler" ;
VAL_ 1527 RW_Primaer_Reichweite_Anzeige 2045 "nicht_verbaut" 2046 "Init" 2047 "Fehler" ;
VAL_ 1527 RW_Reichweite_Einheit_Anzeige 0 "km" 1 "miles" ;
VAL_ 1527 RW_Reservewarnung_aktiv 0 "inaktiv" 1 "aktiv" ;
VAL_ 1527 RW_Sek_Reichweitenv_Einheit 0 "Liter_pro_100km" 1 "kWh_pro_100km" 2 "Kg_pro_100km" 3 "nicht_verbaut" ;
VAL_ 1527 RW_Sek_Reichweitenverbrauch 2047 "Init" ;
VAL_ 1527 RW_Sekundaer_Reichweite 2045 "nicht_verbaut" 2046 "Init" 2047 "Fehler" ;
VAL_ 1527 RW_Sekundaer_Reichweite_Anzeige 2045 "nicht_verbaut" 2046 "Init" 2047 "Fehler" ;
VAL_ 1527 RW_Tendenz 0 "keine_Tendenz" 1 "konstant" 2 "steigend" 3 "sinkend" ;
VAL_ 1527 RW_Texte 0 "kein_Text" 1 "Text_1" 2 "Text_2" 3 "Text_3" ;
VAL_ 2527679676 RW_Prim_rRWB_aktiv 0 "rRWB_inaktiv" 1 "rRWB_aktiv" 2 "reserviert" 3 "Init" ;
VAL_ 2527679676 RW_Prim_rRWB_Reichw_Anz 2045 "nicht_verbaut" 2046 "Init" 2047 "Fehler" ;
VAL_ 2527679676 RW_Prim_rRWB_Reichw_Gesamt_Anz 2045 "nicht_verbaut" 2046 "Init" 2047 "Fehler" ;
VAL_ 2527679676 RW_Prim_rRWB_Reichw_Max_Ges_Anz 2045 "nicht_verbaut" 2046 "Init" 2047 "Fehler" ;
VAL_ 2527679676 RW_Prim_rRWB_Reichw_Rest_E_Anz 2045 "nicht_verbaut" 2046 "Init" 2047 "Fehler" ;
VAL_ 2527679676 RW_Prim_statische_Reichw_Anz 2045 "nicht_verbaut" 2046 "Init" 2047 "Fehler" ;
VAL_ 1610 RKA_FMVSS138_Lampe 0 "keine Warnung" 1 "Warnlampe FMVSS 138, gelbe Lampe statisch an" ;
VAL_ 1610 RKA_Reifentyp 0 "Init" 1 "Winter" 2 "Sommer" 3 "Ganzjahresreifen" 4 "Kundenspezifisch" ;
VAL_ 1610 RKA_Warnungen_02 0 "keine_Anzeige" 1 "Kontrollleuchte" 2 "Systemfehler" 3 "Reifen_allgemein_Warnstufe_1" 4 "Reifen_vorne_links_Warnstufe_1" 5 "Reifen_vorne_rechts_Warnstufe_1" 6 "Reifen_hinten_links_Warnstufe_1" 7 "Reifen_hinten_rechts_Warnstufe_1" 8 "Reifen_allgemein_Warnstufe_2" 9 "Reifen_vorne_links_Warnstufe_2" 10 "Reifen_vorne_rechts_Warnstufe_2" 11 "Reifen_hinten_links_Warnstufe_2" 12 "Reifen_hinten_rechts_Warnstufe_2" 13 "Reifen_allgemein_Warnstufe_3" 14 "Reifen_vorne_links_Warnstufe_3" 15 "Reifen_vorne_rechts_Warnstufe_3" 16 "Reifen_hinten_links_Warnstufe_3" 17 "Reifen_hinten_rechts_Warnstufe_3" 18 "Reifendruecke_kalibrieren" 19 "Akustik" 20 "Systemfehler_Lampe_Text" 21 "Reifen_allgemein_Lampe_Text" 22 "Reifen_vorne_links_Lampe_Text" 23 "Reifen_vorne_rechts_Lampe_Text" 24 "Reifen_hinten_links_Lampe_Text" 25 "Reifen_hinten_rechts_Lampe_Text" 26 "Reifendruecke_kalibrieren_Text_Gong" 27 "Reifendruecke_kalibrieren_Text_Gong_Lampe" 28 "Reifenwechsel_erkannt" ;
VAL_ 1440 LS_defekt 0 "OK" 1 "defekt" ;
VAL_ 1440 LS_Helligkeit_FW 1022 "Init" 1023 "Fehler" ;
VAL_ 1440 LS_Helligkeit_IR 254 "Init" 255 "Fehler" ;
VAL_ 1440 LS_Verbau 0 "Init" 1 "Lichtsensor_verbaut" ;
VAL_ 1440 RLS_Vorfeldhelligkeit_Boost 0 "groesser_24413_Lux" 1 "bis_24413_Lux" 2 "bis_22193_Lux" 3 "bis_20176_Lux" 4 "bis_18342_Lux" 5 "bis_16647_Lux" 6 "bis_15158_Lux" 7 "bis_13780_Lux" 8 "bis_12527_Lux" 9 "bis_11388_Lux" 10 "bis_10353_Lux" 11 "bis_9412_Lux" 12 "bis_8556_Lux" 13 "bis_7778_Lux" 14 "bis_7071_Lux" 15 "bis_6428_Lux" ;
VAL_ 1440 RS_defekt 0 "OK" 1 "defekt" ;
VAL_ 1440 RS_Regenmenge 0 "0" 1 "0,0_bis_0,3" 2 "0,31_bis_1,4" 3 "1,41_bis_2,0" 4 "2,01_bis_2,8" 5 "2,81_bis_3,3" 6 "3,31_bis_4,0" 7 "4,01_bis_5,0" 8 "5,01_bis_7,0" 9 "7,01_bis_9,0" 10 "9,01_bis_11,0" 11 "11,01_bis_15,0" 12 "15,01_bis_22,0" 13 ">22,01" 14 "Init" 15 "Fehler" ;
VAL_ 1440 RS_Schwall 0 "Aus" 1 "Ein" ;
VAL_ 1440 RS_Verbau 0 "Init" 1 "Regensensor verbaut" ;
VAL_ 1440 RS_Verglasung_schliessen 0 "Verglasung nicht schliessen" 1 "Verglasung schliessen" ;
VAL_ 1440 RS_Wischergeschwindigkeit 0 "kein Wischen" 1 "42 Huebe/min" 2 "45 Huebe/min" 3 "48 Huebe/min" 4 "51 Huebe/min" 5 "54 Huebe/min" 6 "57 Huebe/min" 7 "60 Huebe/min" ;
VAL_ 1440 SLS_Helligkeit_IR 254 "Init" 255 "Fehler" ;
VAL_ 2527679669 LS_Autobahnfahrlicht 0 "Aus" 1 "Ein" ;
VAL_ 2527679669 LS_Dunkel 0 "Hell" 1 "Dunkel" ;
VAL_ 2527679669 LS_Error 0 "normal" 1 "Fehler" ;
VAL_ 2527679669 LS_Helligkeit_FW 1022 "Init" 1023 "Fehler" ;
VAL_ 2527679669 LS_Helligkeit_IR 254 "Init" 255 "Fehler" ;
VAL_ 2527679669 LS_Licht_ein 0 "Aus" 1 "Ein" ;
VAL_ 2527679669 LS_Licht_ein_invers 0 "Aus" 1 "Ein" ;
VAL_ 2527679669 RLS_Qualifizierungsbit 0 "ungueltig" 1 "gueltig" ;
VAL_ 2527679669 RLS_ResponseError 0 "normal" 1 "Fehler" ;
VAL_ 2527679669 RLS_Vorfeldhelligkeit_Boost 0 "groesser_24413_Lux" 1 "bis_24413_Lux" 2 "bis_22193_Lux" 3 "bis_20176_Lux" 4 "bis_18342_Lux" 5 "bis_16647_Lux" 6 "bis_15158_Lux" 7 "bis_13780_Lux" 8 "bis_12527_Lux" 9 "bis_11388_Lux" 10 "bis_10353_Lux" 11 "bis_9412_Lux" 12 "bis_8556_Lux" 13 "bis_7778_Lux" 14 "bis_7071_Lux" 15 "bis_6428_Lux" ;
VAL_ 2527679669 RS_AdaptierungError 0 "normal" 1 "Fehler" ;
VAL_ 2527679669 RS_Error 0 "normal" 1 "Fehler" ;
VAL_ 2527679669 RS_Regenfahrlicht 0 "Aus" 1 "Ein" ;
VAL_ 2527679669 RS_Regenmenge 0 "0" 1 "0,0_bis_0,3" 2 "0,31_bis_1,4" 3 "1,41_bis_2,0" 4 "2,01_bis_2,8" 5 "2,81_bis_3,3" 6 "3,31_bis_4,0" 7 "4,01_bis_5,0" 8 "5,01_bis_7,0" 9 "7,01_bis_9,0" 10 "9,01_bis_11,0" 11 "11,01_bis_15,0" 12 "15,01_bis_22,0" 13 ">22,01" 14 "Init" 15 "Fehler" ;
VAL_ 2527679669 RS_Schwall 0 "Aus" 1 "Ein" ;
VAL_ 2527679669 RS_Verglasung_schliessen 0 "Verglasung nicht schliessen" 1 "Verglasung schliessen" ;
VAL_ 2527679669 RS_versParklage_Wischer 0 "Aus" 1 "Ein" ;
VAL_ 2527679669 RS_Wischergeschwindigkeit 0 "kein Wischen" 1 "42 Huebe/min" 2 "45 Huebe/min" 3 "48 Huebe/min" 4 "51 Huebe/min" 5 "54 Huebe/min" 6 "57 Huebe/min" 7 "60 Huebe/min" ;
VAL_ 2463978697 AFS_Lampe 0 "Aus" 1 "Ein" ;
VAL_ 2463978697 BCM2_Bremsl_durch_ECD 0 "Bremslicht_ist_aus" 1 "Bremslicht_durch_ECD_aktiv" ;
VAL_ 2463978697 DLI_Ambex_RefStatus 0 "Init" 1 "notAvailable" 2 "Referenzlaufaktiv" 3 "Referenzlaufbeendet" 4 "Fehler" ;
VAL_ 2463978697 LWR_Lampe 0 "LWR Fehlerlampe aus" 1 "LWR Fehlerlampe ein" ;
VAL_ 2463978697 LWR_Reisemodus_Texte 0 "keine_Anzeige" 1 "Umschaltung_auf_Linksverkehr_aktiv" 2 "Umschaltung_auf_Rechtsverkehr_aktiv" ;
VAL_ 2463978697 LWR_SollDC 254 "Init" 255 "Fehler" ;
VAL_ 2463978697 SAL_Aussenbeleuchtung_defekt 0 "ok" 1 "defekt" ;
VAL_ 2463978697 SAL_Blinkerzyklus_L 0 "inaktiv" 1 "aktiv" ;
VAL_ 2463978697 SAL_Blinkerzyklus_R 0 "inaktiv" 1 "aktiv" ;
VAL_ 2463978697 SAL_BLK_L_Anf 0 "nicht_angefordert" 1 "angefordert" ;
VAL_ 2463978697 SAL_BLK_R_Anf 0 "nicht_angefordert" 1 "angefordert" ;
VAL_ 2463978697 SAL_Bremszyklus 0 "nicht_aktiv" 1 "aktiv" ;
VAL_ 2463978697 SAL_BRL_Anf 0 "nicht_angefordert" 1 "angefordert" ;
VAL_ 2463978697 SAL_CH_Anf 0 "nicht_angefordert" 1 "angefordert" ;
VAL_ 2463978697 SAL_HGB_Anf 0 "nicht_angefordert" 1 "angefordert" ;
VAL_ 2463978697 SAL_Kl_15 0 "aus" 1 "ein" ;
VAL_ 2463978697 SAL_Kl_15_vFzg 0 "aus" 1 "ein" ;
VAL_ 2463978697 SAL_Kl_15_vFzg_S 0 "aus" 1 "ein" ;
VAL_ 2463978697 SAL_KL_50 0 "aus" 1 "ein" ;
VAL_ 2463978697 SAL_KL_50_5s 0 "aus" 1 "ein" ;
VAL_ 2463978697 SAL_Kl_75 0 "aus" 1 "ein" ;
VAL_ 2463978697 SAL_KL_75_vFzg 0 "aus" 1 "ein" ;
VAL_ 2463978697 SAL_KL_75a 0 "aus" 1 "ein" ;
VAL_ 2463978697 SAL_KL_75a_vFzg 0 "aus" 1 "ein" ;
VAL_ 2463978697 SAL_KZL_Anf 0 "nicht_angefordert" 1 "angefordert" ;
VAL_ 2463978697 SAL_LDS_Abblendlicht_Anf 0 "nicht_aktiv" 1 "aktiv" ;
VAL_ 2463978697 SAL_LDS_Assistenzfahrlicht_Anf 0 "nicht_aktiv" 1 "aktiv" ;
VAL_ 2463978697 SAL_LDS_Nullstellung_Anf 0 "nicht_aktiv" 1 "aktiv" ;
VAL_ 2463978697 SAL_LDS_Standlicht_Anf 0 "nicht_aktiv" 1 "aktiv" ;
VAL_ 2463978697 SAL_LH_Anf 0 "nicht_angefordert" 1 "angefordert" ;
VAL_ 2463978697 SAL_NSL_Anf 0 "nicht_angefordert" 1 "angefordert" ;
VAL_ 2463978697 SAL_PL_L_Anf 0 "nicht_angefordert" 1 "angefordert" ;
VAL_ 2463978697 SAL_PL_R_Anf 0 "nicht_angefordert" 1 "angefordert" ;
VAL_ 2463978697 SAL_RFL_Anf 0 "nicht_angefordert" 1 "angefordert" ;
VAL_ 2463978697 SAL_SL_Anf 0 "nicht_angefordert" 1 "angefordert" ;
VAL_ 2463978697 SAL_WBT_Bel 0 "nicht_angefordert" 1 "angefordert" ;
VAL_ 2463978697 SBBR_SL_AnimDimm_Freigabe 0 "Dimmung_aus_Animation_aus" 1 "Dimmung_an_Animation_aus" 2 "Dimmung_aus_Animation_an" 3 "Dimmung_an_Animation_an" ;
VAL_ 517 BCM_Bremsbelag_Sensor_CND 0 "OK" 1 "Bremsbelag_unter_min" ;
VAL_ 517 BCM_Bremsbelag_Sensor_NAR 0 "OK" 1 "Bremsbelag_unter_min" ;
VAL_ 517 BCM_Bremsbelag_Sensor_Rdw 0 "OK" 1 "Bremsbelag_unter_min_iID" 2 "Bremsbelag_unter_min_MOD" ;
VAL_ 517 BCM_KiSi_Umschalt_gesperrt 0 "nicht_gesperrt" 1 "gesperrt" ;
VAL_ 517 BCM_Tankklappensteller_Fehler 0 "kein_Fehler" 1 "Fehler" ;
VAL_ 517 BRL_Bremslicht_Schalter 0 "nicht_betaetigt" 1 "betaetigt" ;
VAL_ 517 HD_Hauptraste 0 "geschlossen" 1 "offen" ;
VAL_ 517 HD_Vorraste 0 "geschlossen" 1 "offen" ;
VAL_ 517 HW_Drehfalle_Tuer_HL 0 "geschlossen" 1 "offen" ;
VAL_ 517 HW_Drehfalle_Tuer_HR 0 "geschlossen" 1 "offen" ;
VAL_ 517 HW_HD_Taste_Innenraum 0 "Innentaster_nicht_betaetigt" 1 "Innentaster_betaetigt" ;
VAL_ 517 HW_HSB_erkannt 0 "nicht_aktiv" 1 "aktiv" ;
VAL_ 517 HW_MH_Schalter1 0 "MH1_geschlossen" 1 "MH1_offen" ;
VAL_ 517 HW_MH_Schalter2 0 "MH2_geschlossen" 1 "MH2_offen" ;
VAL_ 517 HW_Softtouch_betaetigt 0 "Softtouch_nicht_betaetigt" 1 "Softtouch_betaetigt" ;
VAL_ 517 HW_Status_Schloss_gesafet_HL 0 "nicht_gesafet" 1 "gesafet" ;
VAL_ 517 HW_Status_Schloss_gesafet_HR 0 "nicht_gesafet" 1 "gesafet" ;
VAL_ 517 HW_Status_Schloss_verriegelt_HL 0 "nicht_verriegelt" 1 "verriegelt" ;
VAL_ 517 HW_Status_Schloss_verriegelt_HR 0 "nicht_verriegelt" 1 "verriegelt" ;
VAL_ 517 HW_Tankdeckel_offen 0 "geschlossen" 1 "offen" ;
VAL_ 517 HW_Toggle_Taster 0 "nicht_betaetigt" 1 "betaetigt" ;
VAL_ 517 KST_BSW_Fehlermode2 0 "Aus" 1 "Ein" ;
VAL_ 517 KST_BSW_Klemme_15_HW_Ist 0 "Klemme15HW_aus" 1 "Klemme15HW_ein" 3 "Fehler" ;
VAL_ 517 KST_BSW_Klemmenhochschalten_Sper 0 "nicht_gesperrt" 1 "gesperrt" ;
VAL_ 517 KST_BSW_Not_Taster_betaetigt 0 "nicht_betaetigt" 1 "betaetigt" ;
VAL_ 517 KST_BSW_ZAT_betaetigt 0 "Aus" 1 "Ein" ;
VAL_ 517 SAL_li1_Blinker_Status 0 "Blinker_aus" 1 "Blinker_an" ;
VAL_ 517 SAL_re1_Blinker_Status 0 "Blinker_aus" 1 "Blinker_an" ;
VAL_ 517 SAM_Fehler_DC_LWR 0 "kein_Fehler" 1 "Fehler" ;
VAL_ 517 ZV_Ladeklappe_VerEntriegeln 0 "Init" 1 "Ladeklappe_verriegeln" 2 "Ladeklappe_entriegeln" 3 "keine_Anforderung" ;
VAL_ 517 ZV_LadeklappenStatus 0 "Ladeklappe_geschlossen" 1 "Ladeklappe_geoeffnet" ;
VAL_ 1522 KBI_Dimmpoti 126 "Nicht verfï?½gbar" 127 "Fehler" ;
VAL_ 1522 KBI_Phototransistor 254 "Init" 255 "Fehler" ;
